VERSION ""

NS_ :

BS_:

BU_: PowertrainControlModule AtmosphericSensor SafetyRestraintSystem2 Aftertreatment_2_GasOutlet Aftertreatment_2_GasIntake DieselParticulateFilterControl Turbocharger SafetyRestraintSystem1 CabDisplay2 Aftertreatment_1_GasOutlet Aftertreatment_1_GasIntake OnBoardDataLogger OffBoardDiagnosticTool2 OffBoardDiagnosticTool1 FileServer ParkingBrakeController SeatController2 FanDriveController SteeringColumnUnit CommunicationUnitRadio CommunicationUnitSatellite CommunicationUnitCellular PropulsionBatteryCharger ChassisController2 ChassisController1 EngineValveControl AuxiliaryHeater2 AuxiliaryHeater1 ClutchUnit RampControl InformationSystem1 SuspensionSystemController2 OilSensor VehicleDynamicStability ExhaustEmissionController TransmissionDisplay2 TransmissionDisplay1 ClimateControl2 WaterPumpController RearAxleSteeringController LightingOperatorControl SeatController1 IgnitionController2 IgnitionController1 TirePressureController CabController2 CabController1 PneumaticSystemController SuspensionSystemController1 HydraulicPumpController EnduranceBrakingSystem RetarderExhaustEngine2 OnBoardDiagnosticUnit HeadwayController RetarderExhaustEngine1 CabDisplay1 ManagementComputer VirtualTerminal OffVehicleGateway PowerTakeOffFront HitchControl AuxiliaryValveControl BodyController TractorTrailerBridge1 StarterSystem ElectricalSystem VehicleSecurity VehicleNavigation AerodynamicControl ElectricalChargingSystem ClimateControl1 TripRecorder InstrumentCluster SuspensionDriveAxle2 SuspensionDriveAxle1 SuspensionSteerAxle SteeringController FuelSystem CruiseControl RetarderDriveline RetarderEngine BrakesDriveAxle2 BrakesDriveAxle1 BrakesSystemController BrakesSteerAxle AxleDrive2 AxleDrive1 AxleSteering PowerTakeOff ShiftConsoleSecondary ShiftConsolePrimary Transmission2 Transmission1 Engine2 Engine1

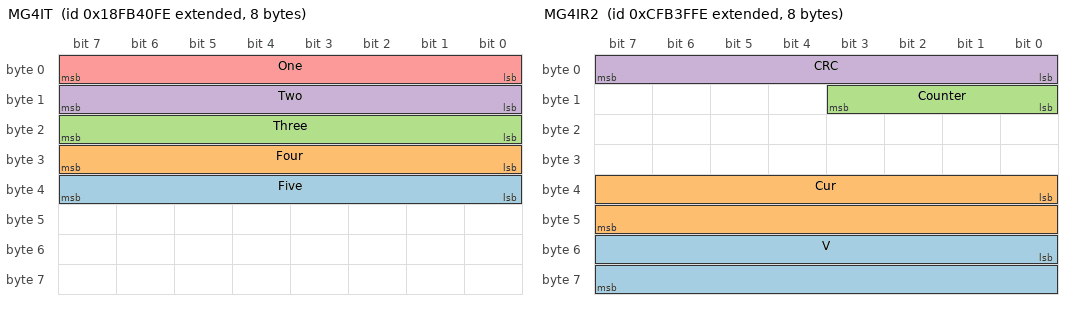
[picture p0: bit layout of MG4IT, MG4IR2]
BO_ 2566603006 MG4IT: 8 Vector__XXX
 SG_ Five : 32|8@1+ (1,-40) [-40|210] "°C" Vector__XXX
 SG_ Four : 24|8@1+ (1,-40) [-40|210] "°C" Vector__XXX
 SG_ Three : 16|8@1+ (1,-40) [-40|210] "°C" Vector__XXX
 SG_ Two : 8|8@1+ (1,-40) [-40|210] "°C" Vector__XXX
 SG_ One : 0|8@1+ (1,-40) [-40|210] "°C" Vector__XXX

BO_ 2365276158 MG4IR2: 8 Vector__XXX
 SG_ V : 48|16@1+ (0.125,0) [0|8031.875] "V" Vector__XXX
 SG_ Cur : 32|16@1+ (0.125,0) [0|8031.875] "A" Vector__XXX
 SG_ Counter : 8|4@1+ (1,0) [0|15] "" Vector__XXX
 SG_ CRC : 0|8@1+ (1,0) [0|255] "" Vector__XXX

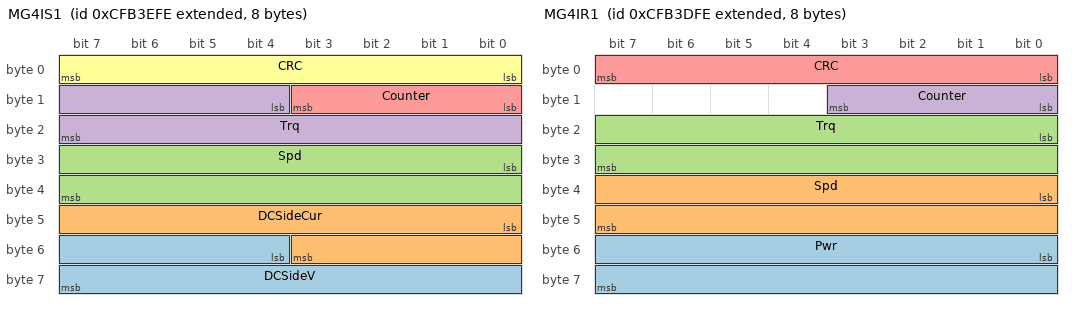
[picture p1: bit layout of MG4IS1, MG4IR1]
BO_ 2365275902 MG4IS1: 8 Vector__XXX
 SG_ DCSideV : 52|12@1+ (0.0625,-125) [-125|125.9375] "%" Vector__XXX
 SG_ DCSideCur : 40|12@1+ (0.0625,-125) [-125|125.9375] "%" Vector__XXX
 SG_ Spd : 24|16@1+ (0.00390625,-125) [-125|125.99609375] "%" Vector__XXX
 SG_ Trq : 12|12@1+ (0.0625,-125) [-125|125.9375] "%" Vector__XXX
 SG_ Counter : 8|4@1+ (1,0) [0|15] "" Vector__XXX
 SG_ CRC : 0|8@1+ (1,0) [0|255] "" Vector__XXX

BO_ 2365275646 MG4IR1: 8 Vector__XXX
 SG_ Pwr : 48|16@1+ (0.0625,0) [0|4015.9375] "kW" Vector__XXX
 SG_ Spd : 32|16@1+ (4,0) [0|257020] "rpm" Vector__XXX
 SG_ Trq : 16|16@1+ (0.5,0) [0|32127.5] "Nm" Vector__XXX
 SG_ Counter : 8|4@1+ (1,0) [0|15] "" Vector__XXX
 SG_ CRC : 0|8@1+ (1,0) [0|255] "" Vector__XXX

BO_ 2566601982 MG5IAPL: 8 Vector__XXX
 SG_ TrqLimDueToMachineCharacter_0003 : 38|2@1+ (1,0) [0|3] "" Vector__XXX
 SG_ PLedDueToActiveSpdRateLmt : 36|2@1+ (1,0) [0|3] "" Vector__XXX
 SG_ PLedDueToActiveTrqRateLmt : 34|2@1+ (1,0) [0|3] "" Vector__XXX
 SG_ PLedDueToFaultCondition : 32|2@1+ (1,0) [0|3] "" Vector__XXX
 SG_ PLedDueToMotorTemp : 30|2@1+ (1,0) [0|3] "" Vector__XXX
 SG_ PLedDueToInvTemp : 28|2@1+ (1,0) [0|3] "" Vector__XXX
 SG_ PLedDueToSpdMin : 24|2@1+ (1,0) [0|3] "" Vector__XXX
 SG_ PLedDueToSpdMax : 22|2@1+ (1,0) [0|3] "" Vector__XXX
 SG_ PLedDueToTrqMin : 20|2@1+ (1,0) [0|3] "" Vector__XXX
 SG_ PLedDueToTrqMax : 18|2@1+ (1,0) [0|3] "" Vector__XXX
 SG_ PLedDueToDCSidePwrMin : 16|2@1+ (1,0) [0|3] "" Vector__XXX
 SG_ PLedDueToDCSidePwrMax : 14|2@1+ (1,0) [0|3] "" Vector__XXX
 SG_ PLedDueToMechPwrMin : 12|2@1+ (1,0) [0|3] "" Vector__XXX
 SG_ PLedDueToMechPwrMax : 10|2@1+ (1,0) [0|3] "" Vector__XXX
 SG_ PLedDueToDCSideVMin : 8|2@1+ (1,0) [0|3] "" Vector__XXX
 SG_ PLedDueToDCSideVMax : 6|2@1+ (1,0) [0|3] "" Vector__XXX
 SG_ PLedDueToDCSideCurMin : 4|2@1+ (1,0) [0|3] "" Vector__XXX
 SG_ PLedDueToDCSideCurMax : 2|2@1+ (1,0) [0|3] "" Vector__XXX
 SG_ PLedDueToUndefinedReason : 0|2@1+ (1,0) [0|3] "" Vector__XXX

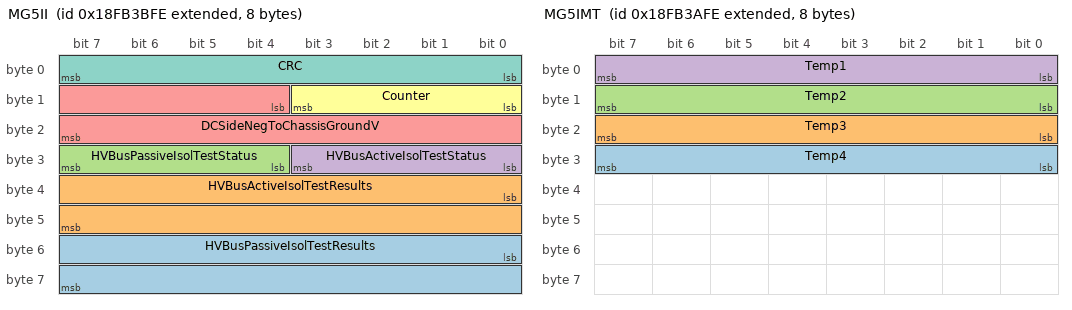
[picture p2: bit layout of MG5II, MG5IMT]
BO_ 2566601726 MG5II: 8 Vector__XXX
 SG_ HVBusPassiveIsolTestResults : 48|16@1+ (0.1,0) [0|6425.5] "Ohm/V" Vector__XXX
 SG_ HVBusActiveIsolTestResults : 32|16@1+ (0.1,0) [0|6425.5] "Ohm/V" Vector__XXX
 SG_ HVBusPassiveIsolTestStatus : 28|4@1+ (1,0) [0|15] "" Vector__XXX
 SG_ HVBusActiveIsolTestStatus : 24|4@1+ (1,0) [0|15] "" Vector__XXX
 SG_ DCSideNegToChassisGroundV : 12|12@1+ (0.0625,-125) [-125|125.9375] "%" Vector__XXX
 SG_ Counter : 8|4@1+ (1,0) [0|15] "" Vector__XXX
 SG_ CRC : 0|8@1+ (1,0) [0|255] "" Vector__XXX

BO_ 2566601470 MG5IMT: 8 Vector__XXX
 SG_ Temp4 : 24|8@1+ (1,-40) [-40|210] "°C" Vector__XXX
 SG_ Temp3 : 16|8@1+ (1,-40) [-40|210] "°C" Vector__XXX
 SG_ Temp2 : 8|8@1+ (1,-40) [-40|210] "°C" Vector__XXX
 SG_ Temp1 : 0|8@1+ (1,-40) [-40|210] "°C" Vector__XXX

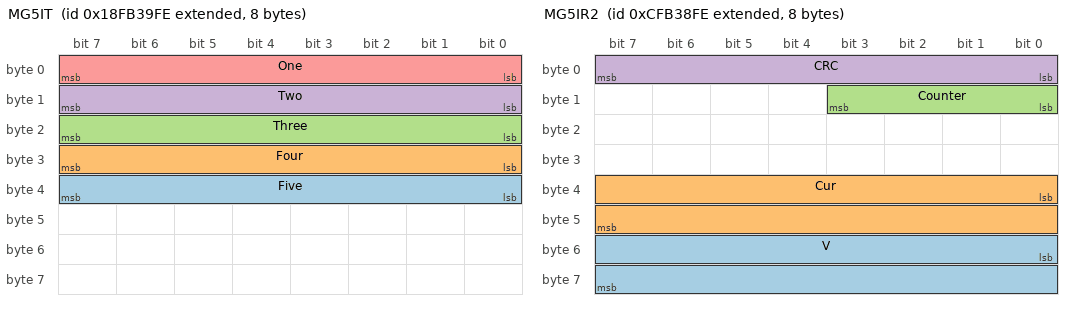
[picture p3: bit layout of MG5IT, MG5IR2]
BO_ 2566601214 MG5IT: 8 Vector__XXX
 SG_ Five : 32|8@1+ (1,-40) [-40|210] "°C" Vector__XXX
 SG_ Four : 24|8@1+ (1,-40) [-40|210] "°C" Vector__XXX
 SG_ Three : 16|8@1+ (1,-40) [-40|210] "°C" Vector__XXX
 SG_ Two : 8|8@1+ (1,-40) [-40|210] "°C" Vector__XXX
 SG_ One : 0|8@1+ (1,-40) [-40|210] "°C" Vector__XXX

BO_ 2365274366 MG5IR2: 8 Vector__XXX
 SG_ V : 48|16@1+ (0.125,0) [0|8031.875] "V" Vector__XXX
 SG_ Cur : 32|16@1+ (0.125,0) [0|8031.875] "A" Vector__XXX
 SG_ Counter : 8|4@1+ (1,0) [0|15] "" Vector__XXX
 SG_ CRC : 0|8@1+ (1,0) [0|255] "" Vector__XXX

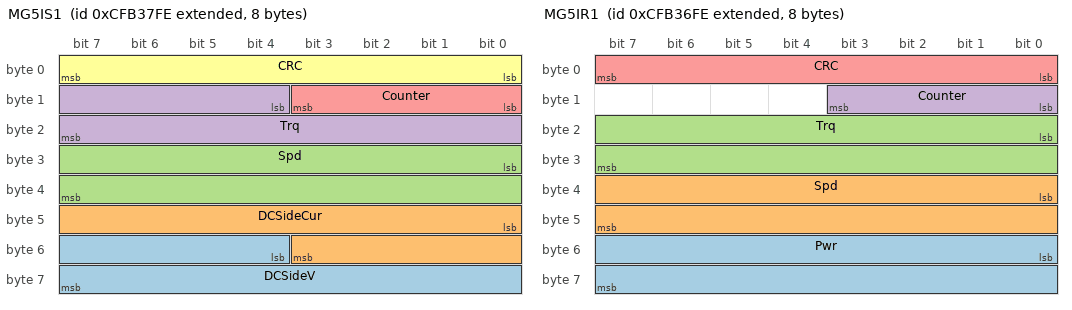
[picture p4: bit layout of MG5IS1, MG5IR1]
BO_ 2365274110 MG5IS1: 8 Vector__XXX
 SG_ DCSideV : 52|12@1+ (0.0625,-125) [-125|125.9375] "%" Vector__XXX
 SG_ DCSideCur : 40|12@1+ (0.0625,-125) [-125|125.9375] "%" Vector__XXX
 SG_ Spd : 24|16@1+ (0.00390625,-125) [-125|125.99609375] "%" Vector__XXX
 SG_ Trq : 12|12@1+ (0.0625,-125) [-125|125.9375] "%" Vector__XXX
 SG_ Counter : 8|4@1+ (1,0) [0|15] "" Vector__XXX
 SG_ CRC : 0|8@1+ (1,0) [0|255] "" Vector__XXX

BO_ 2365273854 MG5IR1: 8 Vector__XXX
 SG_ Pwr : 48|16@1+ (0.0625,0) [0|4015.9375] "kW" Vector__XXX
 SG_ Spd : 32|16@1+ (4,0) [0|257020] "rpm" Vector__XXX
 SG_ Trq : 16|16@1+ (0.5,0) [0|32127.5] "Nm" Vector__XXX
 SG_ Counter : 8|4@1+ (1,0) [0|15] "" Vector__XXX
 SG_ CRC : 0|8@1+ (1,0) [0|255] "" Vector__XXX

BO_ 2566600190 MG6IAPL: 8 Vector__XXX
 SG_ TrqLimDueToMachineCharacter_0004 : 38|2@1+ (1,0) [0|3] "" Vector__XXX
 SG_ PLedDueToActiveSpdRateLmt : 36|2@1+ (1,0) [0|3] "" Vector__XXX
 SG_ PLedDueToActiveTrqRateLmt : 34|2@1+ (1,0) [0|3] "" Vector__XXX
 SG_ PLedDueToFaultCondition : 32|2@1+ (1,0) [0|3] "" Vector__XXX
 SG_ PLedDueToMotorTemp : 30|2@1+ (1,0) [0|3] "" Vector__XXX
 SG_ PLedDueToInvTemp : 28|2@1+ (1,0) [0|3] "" Vector__XXX
 SG_ PLedDueToSpdMin : 24|2@1+ (1,0) [0|3] "" Vector__XXX
 SG_ PLedDueToSpdMax : 22|2@1+ (1,0) [0|3] "" Vector__XXX
 SG_ PLedDueToTrqMin : 20|2@1+ (1,0) [0|3] "" Vector__XXX
 SG_ PLedDueToTrqMax : 18|2@1+ (1,0) [0|3] "" Vector__XXX
 SG_ PLedDueToDCSidePwrMin : 16|2@1+ (1,0) [0|3] "" Vector__XXX
 SG_ PLedDueToDCSidePwrMax : 14|2@1+ (1,0) [0|3] "" Vector__XXX
 SG_ PLedDueToMechPwrMin : 12|2@1+ (1,0) [0|3] "" Vector__XXX
 SG_ PLedDueToMechPwrMax : 10|2@1+ (1,0) [0|3] "" Vector__XXX
 SG_ PLedDueToDCSideVMin : 8|2@1+ (1,0) [0|3] "" Vector__XXX
 SG_ PLedDueToDCSideVMax : 6|2@1+ (1,0) [0|3] "" Vector__XXX
 SG_ PLedDueToDCSideCurMin : 4|2@1+ (1,0) [0|3] "" Vector__XXX
 SG_ PLedDueToDCSideCurMax : 2|2@1+ (1,0) [0|3] "" Vector__XXX
 SG_ PLedDueToUndefinedReason : 0|2@1+ (1,0) [0|3] "" Vector__XXX

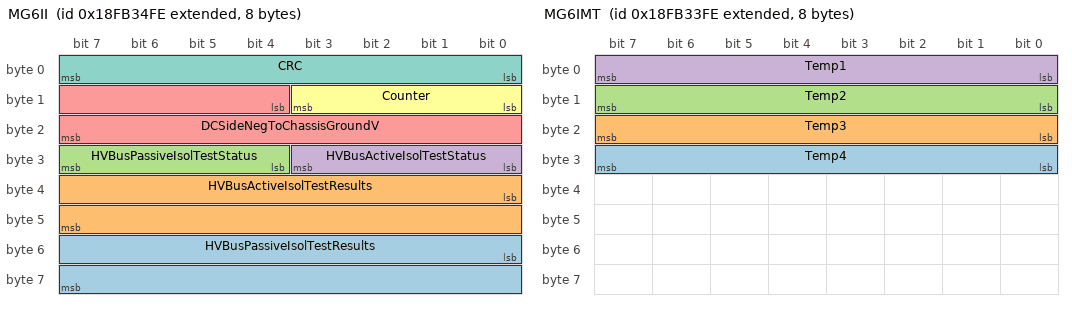
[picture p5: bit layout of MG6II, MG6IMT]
BO_ 2566599934 MG6II: 8 Vector__XXX
 SG_ HVBusPassiveIsolTestResults : 48|16@1+ (0.1,0) [0|6425.5] "Ohm/V" Vector__XXX
 SG_ HVBusActiveIsolTestResults : 32|16@1+ (0.1,0) [0|6425.5] "Ohm/V" Vector__XXX
 SG_ HVBusPassiveIsolTestStatus : 28|4@1+ (1,0) [0|15] "" Vector__XXX
 SG_ HVBusActiveIsolTestStatus : 24|4@1+ (1,0) [0|15] "" Vector__XXX
 SG_ DCSideNegToChassisGroundV : 12|12@1+ (0.0625,-125) [-125|125.9375] "%" Vector__XXX
 SG_ Counter : 8|4@1+ (1,0) [0|15] "" Vector__XXX
 SG_ CRC : 0|8@1+ (1,0) [0|255] "" Vector__XXX

BO_ 2566599678 MG6IMT: 8 Vector__XXX
 SG_ Temp4 : 24|8@1+ (1,-40) [-40|210] "°C" Vector__XXX
 SG_ Temp3 : 16|8@1+ (1,-40) [-40|210] "°C" Vector__XXX
 SG_ Temp2 : 8|8@1+ (1,-40) [-40|210] "°C" Vector__XXX
 SG_ Temp1 : 0|8@1+ (1,-40) [-40|210] "°C" Vector__XXX

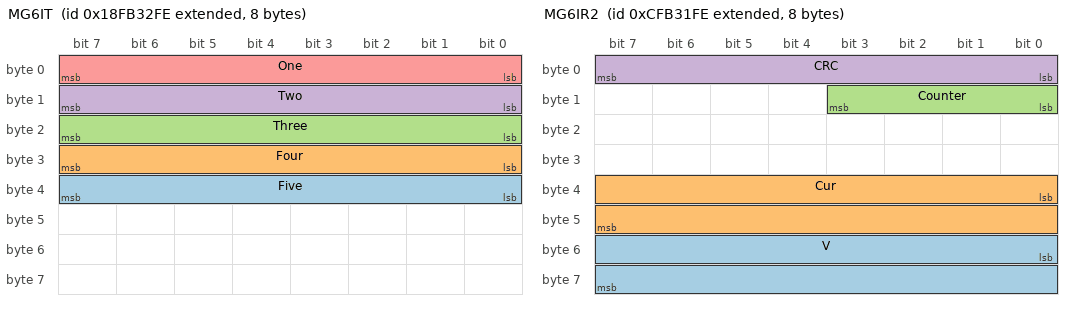
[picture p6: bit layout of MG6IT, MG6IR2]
BO_ 2566599422 MG6IT: 8 Vector__XXX
 SG_ Five : 32|8@1+ (1,-40) [-40|210] "°C" Vector__XXX
 SG_ Four : 24|8@1+ (1,-40) [-40|210] "°C" Vector__XXX
 SG_ Three : 16|8@1+ (1,-40) [-40|210] "°C" Vector__XXX
 SG_ Two : 8|8@1+ (1,-40) [-40|210] "°C" Vector__XXX
 SG_ One : 0|8@1+ (1,-40) [-40|210] "°C" Vector__XXX

BO_ 2365272574 MG6IR2: 8 Vector__XXX
 SG_ V : 48|16@1+ (0.125,0) [0|8031.875] "V" Vector__XXX
 SG_ Cur : 32|16@1+ (0.125,0) [0|8031.875] "A" Vector__XXX
 SG_ Counter : 8|4@1+ (1,0) [0|15] "" Vector__XXX
 SG_ CRC : 0|8@1+ (1,0) [0|255] "" Vector__XXX

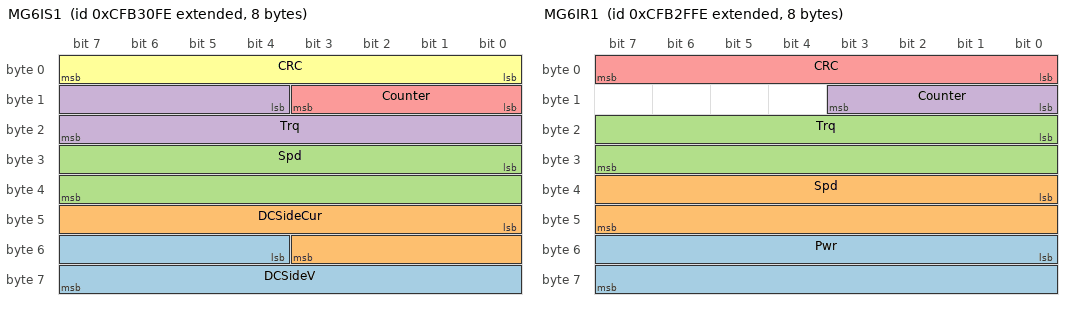
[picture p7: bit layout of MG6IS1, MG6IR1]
BO_ 2365272318 MG6IS1: 8 Vector__XXX
 SG_ DCSideV : 52|12@1+ (0.0625,-125) [-125|125.9375] "%" Vector__XXX
 SG_ DCSideCur : 40|12@1+ (0.0625,-125) [-125|125.9375] "%" Vector__XXX
 SG_ Spd : 24|16@1+ (0.00390625,-125) [-125|125.99609375] "%" Vector__XXX
 SG_ Trq : 12|12@1+ (0.0625,-125) [-125|125.9375] "%" Vector__XXX
 SG_ Counter : 8|4@1+ (1,0) [0|15] "" Vector__XXX
 SG_ CRC : 0|8@1+ (1,0) [0|255] "" Vector__XXX

BO_ 2365272062 MG6IR1: 8 Vector__XXX
 SG_ Pwr : 48|16@1+ (0.0625,0) [0|4015.9375] "kW" Vector__XXX
 SG_ Spd : 32|16@1+ (4,0) [0|257020] "rpm" Vector__XXX
 SG_ Trq : 16|16@1+ (0.5,0) [0|32127.5] "Nm" Vector__XXX
 SG_ Counter : 8|4@1+ (1,0) [0|15] "" Vector__XXX
 SG_ CRC : 0|8@1+ (1,0) [0|255] "" Vector__XXX

BO_ 2566598398 WINCH2: 8 Vector__XXX
 SG_ RevolutionCounter : 0|32@1+ (1,0) [0|4211081215] "" Vector__XXX

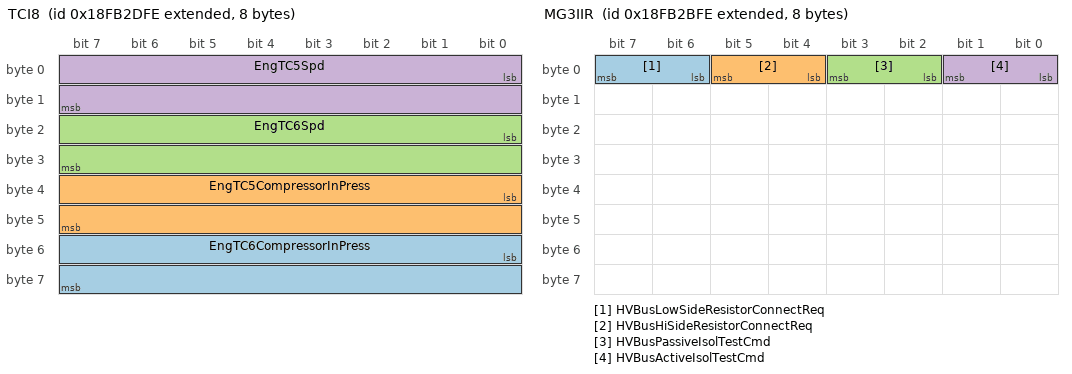
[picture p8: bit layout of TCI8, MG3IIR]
BO_ 2566598142 TCI8: 8 Vector__XXX
 SG_ EngTC6CompressorInPress : 48|16@1+ (0.0078125,-250) [-250|251.9921875] "kPa" Vector__XXX
 SG_ EngTC5CompressorInPress : 32|16@1+ (0.0078125,-250) [-250|251.9921875] "kPa" Vector__XXX
 SG_ EngTC6Spd : 16|16@1+ (4,0) [0|257020] "rpm" Vector__XXX
 SG_ EngTC5Spd : 0|16@1+ (4,0) [0|257020] "rpm" Vector__XXX

BO_ 2566597630 MG3IIR: 8 Vector__XXX
 SG_ HVBusLowSideResistorConnectReq : 6|2@1+ (1,0) [0|3] "" Vector__XXX
 SG_ HVBusHiSideResistorConnectReq : 4|2@1+ (1,0) [0|3] "" Vector__XXX
 SG_ HVBusPassiveIsolTestCmd : 2|2@1+ (1,0) [0|3] "" Vector__XXX
 SG_ HVBusActiveIsolTestCmd : 0|2@1+ (1,0) [0|3] "" Vector__XXX

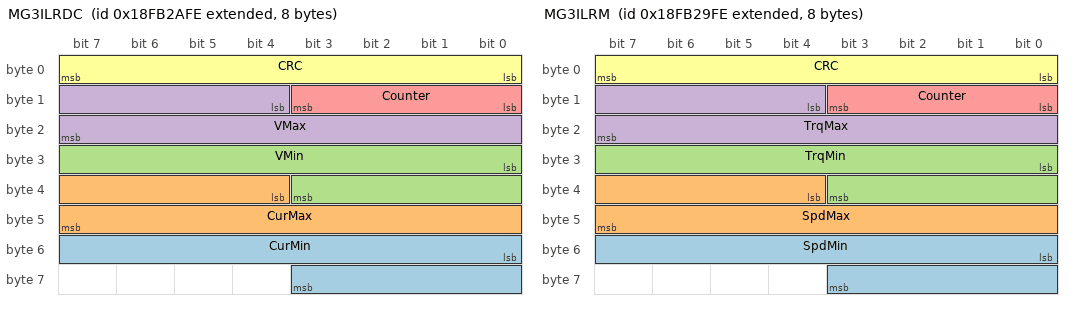
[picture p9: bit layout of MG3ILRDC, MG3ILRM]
BO_ 2566597374 MG3ILRDC: 8 Vector__XXX
 SG_ CurMin : 48|12@1+ (0.0625,-125) [-125|125.9375] "%" Vector__XXX
 SG_ CurMax : 36|12@1+ (0.0625,-125) [-125|125.9375] "%" Vector__XXX
 SG_ VMin : 24|12@1+ (0.0625,-125) [-125|125.9375] "%" Vector__XXX
 SG_ VMax : 12|12@1+ (0.0625,-125) [-125|125.9375] "%" Vector__XXX
 SG_ Counter : 8|4@1+ (1,0) [0|15] "" Vector__XXX
 SG_ CRC : 0|8@1+ (1,0) [0|255] "" Vector__XXX

BO_ 2566597118 MG3ILRM: 8 Vector__XXX
 SG_ SpdMin : 48|12@1+ (0.0625,-125) [-125|125.9375] "%" Vector__XXX
 SG_ SpdMax : 36|12@1+ (0.0625,-125) [-125|125.9375] "%" Vector__XXX
 SG_ TrqMin : 24|12@1+ (0.0625,-125) [-125|125.9375] "%" Vector__XXX
 SG_ TrqMax : 12|12@1+ (0.0625,-125) [-125|125.9375] "%" Vector__XXX
 SG_ Counter : 8|4@1+ (1,0) [0|15] "" Vector__XXX
 SG_ CRC : 0|8@1+ (1,0) [0|255] "" Vector__XXX

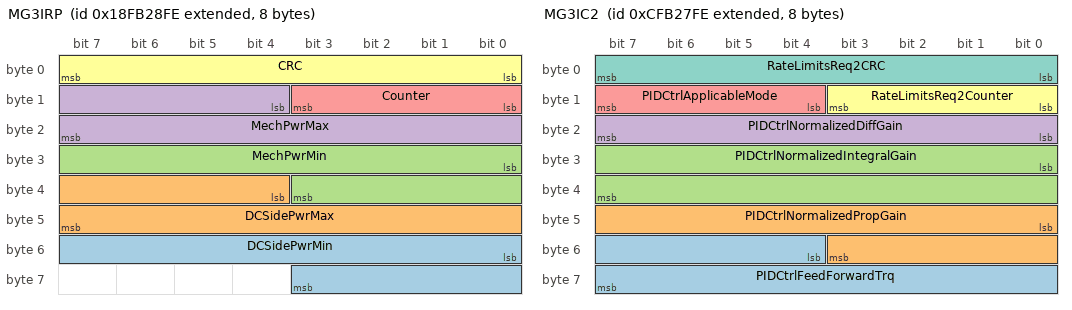
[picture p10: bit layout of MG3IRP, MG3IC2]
BO_ 2566596862 MG3IRP: 8 Vector__XXX
 SG_ DCSidePwrMin : 48|12@1+ (0.0625,-125) [-125|125.9375] "%" Vector__XXX
 SG_ DCSidePwrMax : 36|12@1+ (0.0625,-125) [-125|125.9375] "%" Vector__XXX
 SG_ MechPwrMin : 24|12@1+ (0.0625,-125) [-125|125.9375] "%" Vector__XXX
 SG_ MechPwrMax : 12|12@1+ (0.0625,-125) [-125|125.9375] "%" Vector__XXX
 SG_ Counter : 8|4@1+ (1,0) [0|15] "" Vector__XXX
 SG_ CRC : 0|8@1+ (1,0) [0|255] "" Vector__XXX

BO_ 2365270014 MG3IC2: 8 Vector__XXX
 SG_ PIDCtrlFeedForwardTrq : 52|12@1+ (0.0625,-125) [-125|125.9375] "%" Vector__XXX
 SG_ PIDCtrlNormalizedPropGain : 40|12@1+ (0.0625,0) [0|250.9375] "%/%" Vector__XXX
 SG_ PIDCtrlNormalizedIntegralGain : 24|16@1+ (0.015625,0) [0|1003.984375] "%/(%*s)" Vector__XXX
 SG_ PIDCtrlNormalizedDiffGain : 16|8@1+ (0.03125,0) [0|7.8125] "%/(%/s)" Vector__XXX
 SG_ PIDCtrlApplicableMode : 12|4@1+ (1,0) [0|15] "" Vector__XXX
 SG_ RateLimitsReq2Counter : 8|4@1+ (1,0) [0|15] "" Vector__XXX
 SG_ RateLimitsReq2CRC : 0|8@1+ (1,0) [0|255] "" Vector__XXX

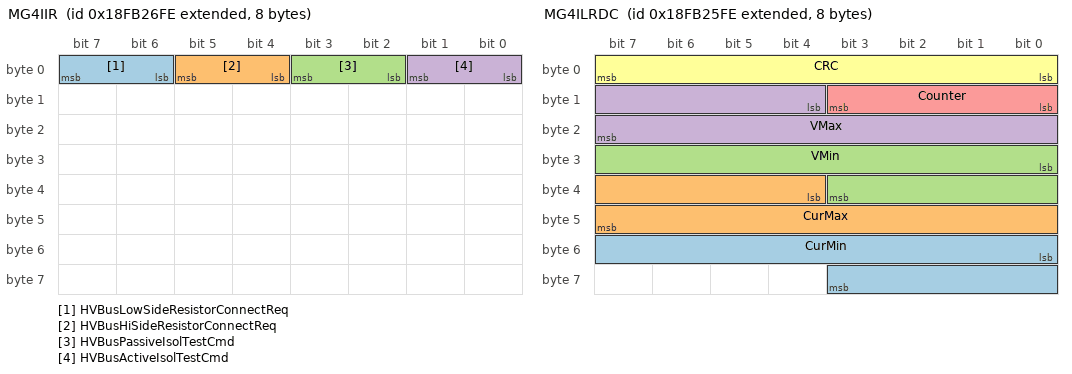
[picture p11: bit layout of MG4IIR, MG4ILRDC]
BO_ 2566596350 MG4IIR: 8 Vector__XXX
 SG_ HVBusLowSideResistorConnectReq : 6|2@1+ (1,0) [0|3] "" Vector__XXX
 SG_ HVBusHiSideResistorConnectReq : 4|2@1+ (1,0) [0|3] "" Vector__XXX
 SG_ HVBusPassiveIsolTestCmd : 2|2@1+ (1,0) [0|3] "" Vector__XXX
 SG_ HVBusActiveIsolTestCmd : 0|2@1+ (1,0) [0|3] "" Vector__XXX

BO_ 2566596094 MG4ILRDC: 8 Vector__XXX
 SG_ CurMin : 48|12@1+ (0.0625,-125) [-125|125.9375] "%" Vector__XXX
 SG_ CurMax : 36|12@1+ (0.0625,-125) [-125|125.9375] "%" Vector__XXX
 SG_ VMin : 24|12@1+ (0.0625,-125) [-125|125.9375] "%" Vector__XXX
 SG_ VMax : 12|12@1+ (0.0625,-125) [-125|125.9375] "%" Vector__XXX
 SG_ Counter : 8|4@1+ (1,0) [0|15] "" Vector__XXX
 SG_ CRC : 0|8@1+ (1,0) [0|255] "" Vector__XXX

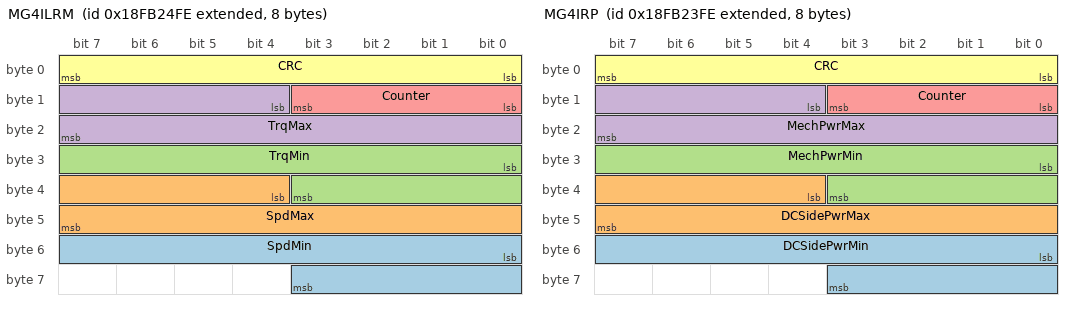
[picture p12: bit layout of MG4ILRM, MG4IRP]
BO_ 2566595838 MG4ILRM: 8 Vector__XXX
 SG_ SpdMin : 48|12@1+ (0.0625,-125) [-125|125.9375] "%" Vector__XXX
 SG_ SpdMax : 36|12@1+ (0.0625,-125) [-125|125.9375] "%" Vector__XXX
 SG_ TrqMin : 24|12@1+ (0.0625,-125) [-125|125.9375] "%" Vector__XXX
 SG_ TrqMax : 12|12@1+ (0.0625,-125) [-125|125.9375] "%" Vector__XXX
 SG_ Counter : 8|4@1+ (1,0) [0|15] "" Vector__XXX
 SG_ CRC : 0|8@1+ (1,0) [0|255] "" Vector__XXX

BO_ 2566595582 MG4IRP: 8 Vector__XXX
 SG_ DCSidePwrMin : 48|12@1+ (0.0625,-125) [-125|125.9375] "%" Vector__XXX
 SG_ DCSidePwrMax : 36|12@1+ (0.0625,-125) [-125|125.9375] "%" Vector__XXX
 SG_ MechPwrMin : 24|12@1+ (0.0625,-125) [-125|125.9375] "%" Vector__XXX
 SG_ MechPwrMax : 12|12@1+ (0.0625,-125) [-125|125.9375] "%" Vector__XXX
 SG_ Counter : 8|4@1+ (1,0) [0|15] "" Vector__XXX
 SG_ CRC : 0|8@1+ (1,0) [0|255] "" Vector__XXX

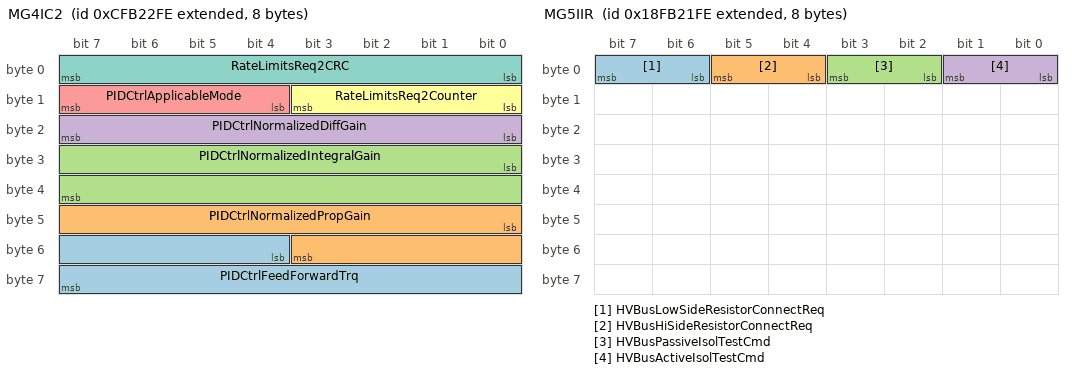
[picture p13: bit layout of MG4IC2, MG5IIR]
BO_ 2365268734 MG4IC2: 8 Vector__XXX
 SG_ PIDCtrlFeedForwardTrq : 52|12@1+ (0.0625,-125) [-125|125.9375] "%" Vector__XXX
 SG_ PIDCtrlNormalizedPropGain : 40|12@1+ (0.0625,0) [0|250.9375] "%/%" Vector__XXX
 SG_ PIDCtrlNormalizedIntegralGain : 24|16@1+ (0.015625,0) [0|1003.984375] "%/(%*s)" Vector__XXX
 SG_ PIDCtrlNormalizedDiffGain : 16|8@1+ (0.03125,0) [0|7.8125] "%/(%/s)" Vector__XXX
 SG_ PIDCtrlApplicableMode : 12|4@1+ (1,0) [0|15] "" Vector__XXX
 SG_ RateLimitsReq2Counter : 8|4@1+ (1,0) [0|15] "" Vector__XXX
 SG_ RateLimitsReq2CRC : 0|8@1+ (1,0) [0|255] "" Vector__XXX

BO_ 2566595070 MG5IIR: 8 Vector__XXX
 SG_ HVBusLowSideResistorConnectReq : 6|2@1+ (1,0) [0|3] "" Vector__XXX
 SG_ HVBusHiSideResistorConnectReq : 4|2@1+ (1,0) [0|3] "" Vector__XXX
 SG_ HVBusPassiveIsolTestCmd : 2|2@1+ (1,0) [0|3] "" Vector__XXX
 SG_ HVBusActiveIsolTestCmd : 0|2@1+ (1,0) [0|3] "" Vector__XXX

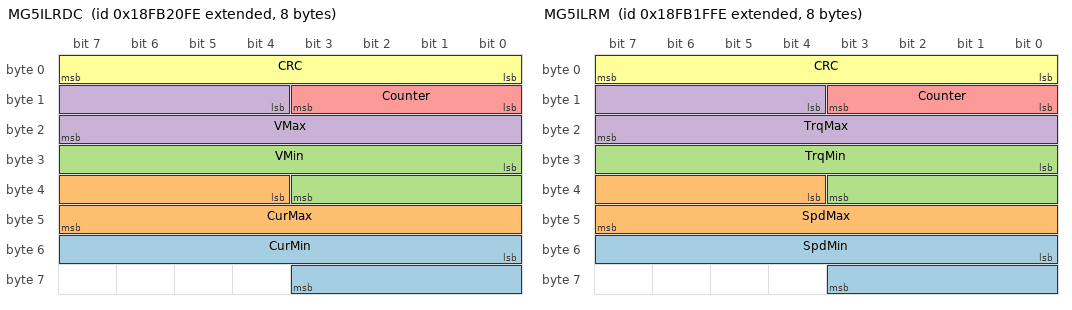
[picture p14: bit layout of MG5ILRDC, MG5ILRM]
BO_ 2566594814 MG5ILRDC: 8 Vector__XXX
 SG_ CurMin : 48|12@1+ (0.0625,-125) [-125|125.9375] "%" Vector__XXX
 SG_ CurMax : 36|12@1+ (0.0625,-125) [-125|125.9375] "%" Vector__XXX
 SG_ VMin : 24|12@1+ (0.0625,-125) [-125|125.9375] "%" Vector__XXX
 SG_ VMax : 12|12@1+ (0.0625,-125) [-125|125.9375] "%" Vector__XXX
 SG_ Counter : 8|4@1+ (1,0) [0|15] "" Vector__XXX
 SG_ CRC : 0|8@1+ (1,0) [0|255] "" Vector__XXX

BO_ 2566594558 MG5ILRM: 8 Vector__XXX
 SG_ SpdMin : 48|12@1+ (0.0625,-125) [-125|125.9375] "%" Vector__XXX
 SG_ SpdMax : 36|12@1+ (0.0625,-125) [-125|125.9375] "%" Vector__XXX
 SG_ TrqMin : 24|12@1+ (0.0625,-125) [-125|125.9375] "%" Vector__XXX
 SG_ TrqMax : 12|12@1+ (0.0625,-125) [-125|125.9375] "%" Vector__XXX
 SG_ Counter : 8|4@1+ (1,0) [0|15] "" Vector__XXX
 SG_ CRC : 0|8@1+ (1,0) [0|255] "" Vector__XXX

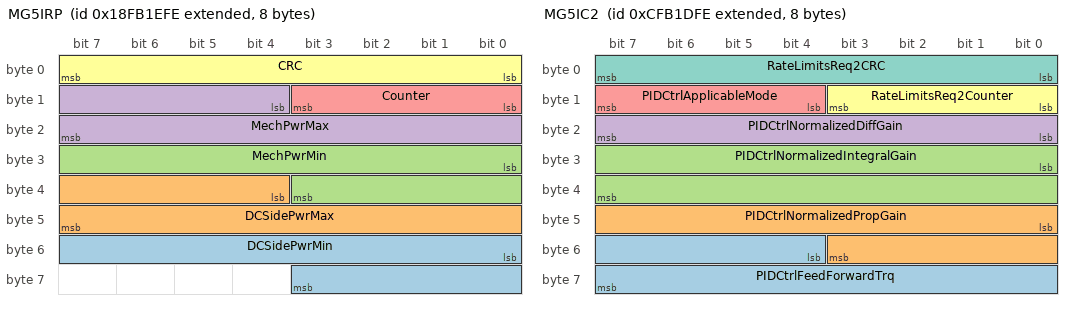
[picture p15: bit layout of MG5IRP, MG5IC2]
BO_ 2566594302 MG5IRP: 8 Vector__XXX
 SG_ DCSidePwrMin : 48|12@1+ (0.0625,-125) [-125|125.9375] "%" Vector__XXX
 SG_ DCSidePwrMax : 36|12@1+ (0.0625,-125) [-125|125.9375] "%" Vector__XXX
 SG_ MechPwrMin : 24|12@1+ (0.0625,-125) [-125|125.9375] "%" Vector__XXX
 SG_ MechPwrMax : 12|12@1+ (0.0625,-125) [-125|125.9375] "%" Vector__XXX
 SG_ Counter : 8|4@1+ (1,0) [0|15] "" Vector__XXX
 SG_ CRC : 0|8@1+ (1,0) [0|255] "" Vector__XXX

BO_ 2365267454 MG5IC2: 8 Vector__XXX
 SG_ PIDCtrlFeedForwardTrq : 52|12@1+ (0.0625,-125) [-125|125.9375] "%" Vector__XXX
 SG_ PIDCtrlNormalizedPropGain : 40|12@1+ (0.0625,0) [0|250.9375] "%/%" Vector__XXX
 SG_ PIDCtrlNormalizedIntegralGain : 24|16@1+ (0.015625,0) [0|1003.984375] "%/(%*s)" Vector__XXX
 SG_ PIDCtrlNormalizedDiffGain : 16|8@1+ (0.03125,0) [0|7.8125] "%/(%/s)" Vector__XXX
 SG_ PIDCtrlApplicableMode : 12|4@1+ (1,0) [0|15] "" Vector__XXX
 SG_ RateLimitsReq2Counter : 8|4@1+ (1,0) [0|15] "" Vector__XXX
 SG_ RateLimitsReq2CRC : 0|8@1+ (1,0) [0|255] "" Vector__XXX

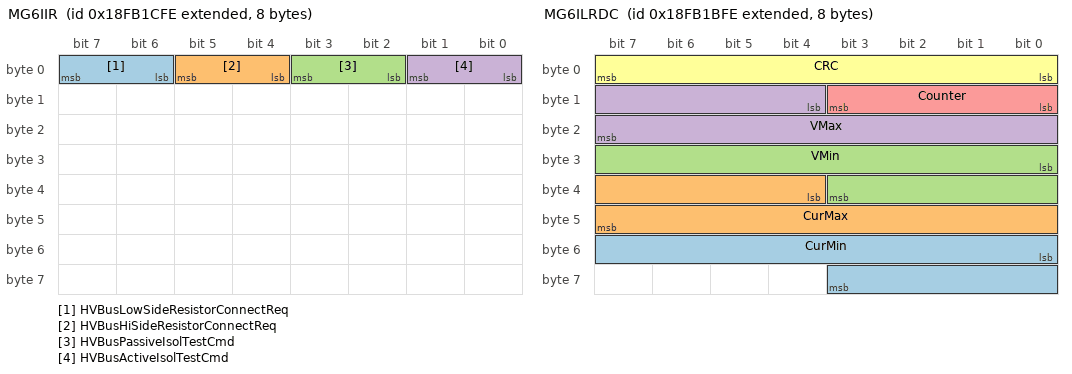
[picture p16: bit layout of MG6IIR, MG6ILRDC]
BO_ 2566593790 MG6IIR: 8 Vector__XXX
 SG_ HVBusLowSideResistorConnectReq : 6|2@1+ (1,0) [0|3] "" Vector__XXX
 SG_ HVBusHiSideResistorConnectReq : 4|2@1+ (1,0) [0|3] "" Vector__XXX
 SG_ HVBusPassiveIsolTestCmd : 2|2@1+ (1,0) [0|3] "" Vector__XXX
 SG_ HVBusActiveIsolTestCmd : 0|2@1+ (1,0) [0|3] "" Vector__XXX

BO_ 2566593534 MG6ILRDC: 8 Vector__XXX
 SG_ CurMin : 48|12@1+ (0.0625,-125) [-125|125.9375] "%" Vector__XXX
 SG_ CurMax : 36|12@1+ (0.0625,-125) [-125|125.9375] "%" Vector__XXX
 SG_ VMin : 24|12@1+ (0.0625,-125) [-125|125.9375] "%" Vector__XXX
 SG_ VMax : 12|12@1+ (0.0625,-125) [-125|125.9375] "%" Vector__XXX
 SG_ Counter : 8|4@1+ (1,0) [0|15] "" Vector__XXX
 SG_ CRC : 0|8@1+ (1,0) [0|255] "" Vector__XXX

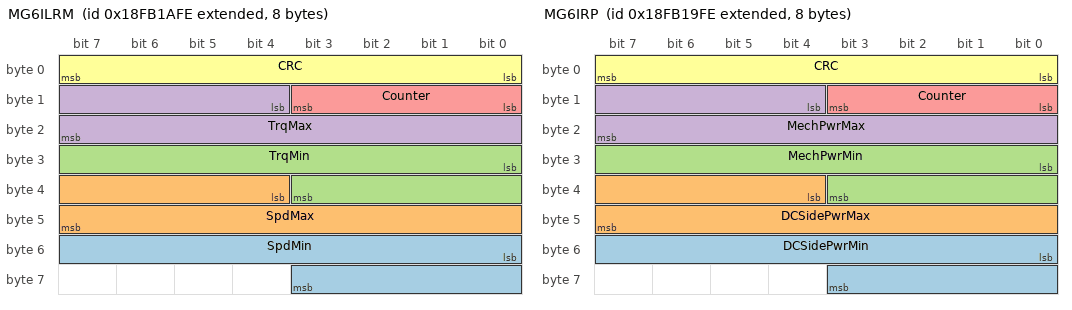
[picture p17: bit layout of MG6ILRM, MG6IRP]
BO_ 2566593278 MG6ILRM: 8 Vector__XXX
 SG_ SpdMin : 48|12@1+ (0.0625,-125) [-125|125.9375] "%" Vector__XXX
 SG_ SpdMax : 36|12@1+ (0.0625,-125) [-125|125.9375] "%" Vector__XXX
 SG_ TrqMin : 24|12@1+ (0.0625,-125) [-125|125.9375] "%" Vector__XXX
 SG_ TrqMax : 12|12@1+ (0.0625,-125) [-125|125.9375] "%" Vector__XXX
 SG_ Counter : 8|4@1+ (1,0) [0|15] "" Vector__XXX
 SG_ CRC : 0|8@1+ (1,0) [0|255] "" Vector__XXX

BO_ 2566593022 MG6IRP: 8 Vector__XXX
 SG_ DCSidePwrMin : 48|12@1+ (0.0625,-125) [-125|125.9375] "%" Vector__XXX
 SG_ DCSidePwrMax : 36|12@1+ (0.0625,-125) [-125|125.9375] "%" Vector__XXX
 SG_ MechPwrMin : 24|12@1+ (0.0625,-125) [-125|125.9375] "%" Vector__XXX
 SG_ MechPwrMax : 12|12@1+ (0.0625,-125) [-125|125.9375] "%" Vector__XXX
 SG_ Counter : 8|4@1+ (1,0) [0|15] "" Vector__XXX
 SG_ CRC : 0|8@1+ (1,0) [0|255] "" Vector__XXX

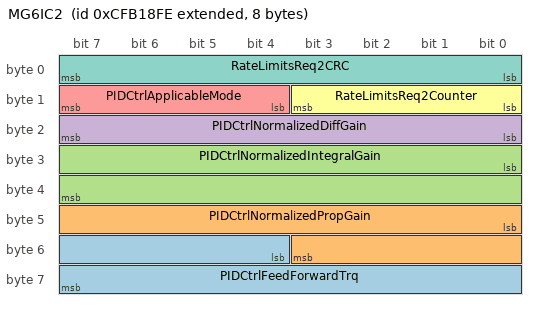
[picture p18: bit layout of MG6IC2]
BO_ 2365266174 MG6IC2: 8 Vector__XXX
 SG_ PIDCtrlFeedForwardTrq : 52|12@1+ (0.0625,-125) [-125|125.9375] "%" Vector__XXX
 SG_ PIDCtrlNormalizedPropGain : 40|12@1+ (0.0625,0) [0|250.9375] "%/%" Vector__XXX
 SG_ PIDCtrlNormalizedIntegralGain : 24|16@1+ (0.015625,0) [0|1003.984375] "%/(%*s)" Vector__XXX
 SG_ PIDCtrlNormalizedDiffGain : 16|8@1+ (0.03125,0) [0|7.8125] "%/(%/s)" Vector__XXX
 SG_ PIDCtrlApplicableMode : 12|4@1+ (1,0) [0|15] "" Vector__XXX
 SG_ RateLimitsReq2Counter : 8|4@1+ (1,0) [0|15] "" Vector__XXX
 SG_ RateLimitsReq2CRC : 0|8@1+ (1,0) [0|255] "" Vector__XXX

BO_ 2566592510 NTSNA: 68 Vector__XXX
 SG_ Bin17 : 512|32@1+ (0.0002,0) [0|842216.243] "g" Vector__XXX
 SG_ Bin16 : 480|32@1+ (0.0002,0) [0|842216.243] "g" Vector__XXX
 SG_ Bin15 : 448|32@1+ (0.0002,0) [0|842216.243] "g" Vector__XXX
 SG_ Bin14 : 416|32@1+ (0.0002,0) [0|842216.243] "g" Vector__XXX
 SG_ Bin13 : 384|32@1+ (0.0002,0) [0|842216.243] "g" Vector__XXX
 SG_ Bin12 : 352|32@1+ (0.0002,0) [0|842216.243] "g" Vector__XXX
 SG_ Bin11 : 320|32@1+ (0.0002,0) [0|842216.243] "g" Vector__XXX
 SG_ Bin10 : 288|32@1+ (0.0002,0) [0|842216.243] "g" Vector__XXX
 SG_ Bin9 : 256|32@1+ (0.0002,0) [0|842216.243] "g" Vector__XXX
 SG_ Bin8 : 224|32@1+ (0.0002,0) [0|842216.243] "g" Vector__XXX
 SG_ Bin7 : 192|32@1+ (0.0002,0) [0|842216.243] "g" Vector__XXX
 SG_ Bin6 : 160|32@1+ (0.0002,0) [0|842216.243] "g" Vector__XXX
 SG_ Bin5 : 128|32@1+ (0.0002,0) [0|842216.243] "g" Vector__XXX
 SG_ Bin4 : 96|32@1+ (0.0002,0) [0|842216.243] "g" Vector__XXX
 SG_ Bin3 : 64|32@1+ (0.0002,0) [0|842216.243] "g" Vector__XXX
 SG_ Bin2 : 32|32@1+ (0.0002,0) [0|842216.243] "g" Vector__XXX
 SG_ Bin1 : 0|32@1+ (0.0002,0) [0|842216.243] "g" Vector__XXX

BO_ 2566592254 NTENA: 68 Vector__XXX
 SG_ Bin17 : 512|32@1+ (0.0005,0) [0|2105540.6075] "g" Vector__XXX
 SG_ Bin16 : 480|32@1+ (0.0005,0) [0|2105540.6075] "g" Vector__XXX
 SG_ Bin15 : 448|32@1+ (0.0005,0) [0|2105540.6075] "g" Vector__XXX
 SG_ Bin14 : 416|32@1+ (0.0005,0) [0|2105540.6075] "g" Vector__XXX
 SG_ Bin13 : 384|32@1+ (0.0005,0) [0|2105540.6075] "g" Vector__XXX
 SG_ Bin12 : 352|32@1+ (0.0005,0) [0|2105540.6075] "g" Vector__XXX
 SG_ Bin11 : 320|32@1+ (0.0005,0) [0|2105540.6075] "g" Vector__XXX
 SG_ Bin10 : 288|32@1+ (0.0005,0) [0|2105540.6075] "g" Vector__XXX
 SG_ Bin9 : 256|32@1+ (0.0005,0) [0|2105540.6075] "g" Vector__XXX
 SG_ Bin8 : 224|32@1+ (0.0005,0) [0|2105540.6075] "g" Vector__XXX
 SG_ Bin7 : 192|32@1+ (0.0005,0) [0|2105540.6075] "g" Vector__XXX
 SG_ Bin6 : 160|32@1+ (0.0005,0) [0|2105540.6075] "g" Vector__XXX
 SG_ Bin5 : 128|32@1+ (0.0005,0) [0|2105540.6075] "g" Vector__XXX
 SG_ Bin4 : 96|32@1+ (0.0005,0) [0|2105540.6075] "g" Vector__XXX
 SG_ Bin3 : 64|32@1+ (0.0005,0) [0|2105540.6075] "g" Vector__XXX
 SG_ Bin2 : 32|32@1+ (0.0005,0) [0|2105540.6075] "g" Vector__XXX
 SG_ Bin1 : 0|32@1+ (0.0005,0) [0|2105540.6075] "g" Vector__XXX

BO_ 2566591998 NTEEA: 34 Vector__XXX
 SG_ Bin17 : 256|16@1+ (1,0) [0|64255] "kWh" Vector__XXX
 SG_ Bin16 : 240|16@1+ (1,0) [0|64255] "kWh" Vector__XXX
 SG_ Bin15 : 224|16@1+ (1,0) [0|64255] "kWh" Vector__XXX
 SG_ Bin14 : 208|16@1+ (1,0) [0|64255] "kWh" Vector__XXX
 SG_ Bin13 : 192|16@1+ (1,0) [0|64255] "kWh" Vector__XXX
 SG_ Bin12 : 176|16@1+ (1,0) [0|64255] "kWh" Vector__XXX
 SG_ Bin11 : 160|16@1+ (1,0) [0|64255] "kWh" Vector__XXX
 SG_ Bin10 : 144|16@1+ (1,0) [0|64255] "kWh" Vector__XXX
 SG_ Bin9 : 128|16@1+ (1,0) [0|64255] "kWh" Vector__XXX
 SG_ Bin8 : 112|16@1+ (1,0) [0|64255] "kWh" Vector__XXX
 SG_ Bin7 : 96|16@1+ (1,0) [0|64255] "kWh" Vector__XXX
 SG_ Bin6 : 80|16@1+ (1,0) [0|64255] "kWh" Vector__XXX
 SG_ Bin5 : 64|16@1+ (1,0) [0|64255] "kWh" Vector__XXX
 SG_ Bin4 : 48|16@1+ (1,0) [0|64255] "kWh" Vector__XXX
 SG_ Bin3 : 32|16@1+ (1,0) [0|64255] "kWh" Vector__XXX
 SG_ Bin2 : 16|16@1+ (1,0) [0|64255] "kWh" Vector__XXX
 SG_ Bin1 : 0|16@1+ (1,0) [0|64255] "kWh" Vector__XXX

BO_ 2566591742 NTVMA: 34 Vector__XXX
 SG_ Bin17 : 256|16@1+ (0.25,0) [0|16063.75] "km" Vector__XXX
 SG_ Bin16 : 240|16@1+ (0.25,0) [0|16063.75] "km" Vector__XXX
 SG_ Bin15 : 224|16@1+ (0.25,0) [0|16063.75] "km" Vector__XXX
 SG_ Bin14 : 208|16@1+ (0.25,0) [0|16063.75] "km" Vector__XXX
 SG_ Bin13 : 192|16@1+ (0.25,0) [0|16063.75] "km" Vector__XXX
 SG_ Bin12 : 176|16@1+ (0.25,0) [0|16063.75] "km" Vector__XXX
 SG_ Bin11 : 160|16@1+ (0.25,0) [0|16063.75] "km" Vector__XXX
 SG_ Bin10 : 144|16@1+ (0.25,0) [0|16063.75] "km" Vector__XXX
 SG_ Bin9 : 128|16@1+ (0.25,0) [0|16063.75] "km" Vector__XXX
 SG_ Bin8 : 112|16@1+ (0.25,0) [0|16063.75] "km" Vector__XXX
 SG_ Bin7 : 96|16@1+ (0.25,0) [0|16063.75] "km" Vector__XXX
 SG_ Bin6 : 80|16@1+ (0.25,0) [0|16063.75] "km" Vector__XXX
 SG_ Bin5 : 64|16@1+ (0.25,0) [0|16063.75] "km" Vector__XXX
 SG_ Bin4 : 48|16@1+ (0.25,0) [0|16063.75] "km" Vector__XXX
 SG_ Bin3 : 32|16@1+ (0.25,0) [0|16063.75] "km" Vector__XXX
 SG_ Bin2 : 16|16@1+ (0.25,0) [0|16063.75] "km" Vector__XXX
 SG_ Bin1 : 0|16@1+ (0.25,0) [0|16063.75] "km" Vector__XXX

BO_ 2566591486 NTEHA: 34 Vector__XXX
 SG_ Bin17 : 256|16@1+ (10,0) [0|642550] "s" Vector__XXX
 SG_ Bin16 : 240|16@1+ (10,0) [0|642550] "s" Vector__XXX
 SG_ Bin15 : 224|16@1+ (10,0) [0|642550] "s" Vector__XXX
 SG_ Bin14 : 208|16@1+ (10,0) [0|642550] "s" Vector__XXX
 SG_ Bin13 : 192|16@1+ (10,0) [0|642550] "s" Vector__XXX
 SG_ Bin12 : 176|16@1+ (10,0) [0|642550] "s" Vector__XXX
 SG_ Bin11 : 160|16@1+ (10,0) [0|642550] "s" Vector__XXX
 SG_ Bin10 : 144|16@1+ (10,0) [0|642550] "s" Vector__XXX
 SG_ Bin9 : 128|16@1+ (10,0) [0|642550] "s" Vector__XXX
 SG_ Bin8 : 112|16@1+ (10,0) [0|642550] "s" Vector__XXX
 SG_ Bin7 : 96|16@1+ (10,0) [0|642550] "s" Vector__XXX
 SG_ Bin6 : 80|16@1+ (10,0) [0|642550] "s" Vector__XXX
 SG_ Bin5 : 64|16@1+ (10,0) [0|642550] "s" Vector__XXX
 SG_ Bin4 : 48|16@1+ (10,0) [0|642550] "s" Vector__XXX
 SG_ Bin3 : 32|16@1+ (10,0) [0|642550] "s" Vector__XXX
 SG_ Bin2 : 16|16@1+ (10,0) [0|642550] "s" Vector__XXX
 SG_ Bin1 : 0|16@1+ (10,0) [0|642550] "s" Vector__XXX

BO_ 2566591230 NTFCA: 34 Vector__XXX
 SG_ Bin17 : 256|16@1+ (0.5,0) [0|32127.5] "l" Vector__XXX
 SG_ Bin16 : 240|16@1+ (0.5,0) [0|32127.5] "l" Vector__XXX
 SG_ Bin15 : 224|16@1+ (0.5,0) [0|32127.5] "l" Vector__XXX
 SG_ Bin14 : 208|16@1+ (0.5,0) [0|32127.5] "l" Vector__XXX
 SG_ Bin13 : 192|16@1+ (0.5,0) [0|32127.5] "l" Vector__XXX
 SG_ Bin12 : 176|16@1+ (0.5,0) [0|32127.5] "l" Vector__XXX
 SG_ Bin11 : 160|16@1+ (0.5,0) [0|32127.5] "l" Vector__XXX
 SG_ Bin10 : 144|16@1+ (0.5,0) [0|32127.5] "l" Vector__XXX
 SG_ Bin9 : 128|16@1+ (0.5,0) [0|32127.5] "l" Vector__XXX
 SG_ Bin8 : 112|16@1+ (0.5,0) [0|32127.5] "l" Vector__XXX
 SG_ Bin7 : 96|16@1+ (0.5,0) [0|32127.5] "l" Vector__XXX
 SG_ Bin6 : 80|16@1+ (0.5,0) [0|32127.5] "l" Vector__XXX
 SG_ Bin5 : 64|16@1+ (0.5,0) [0|32127.5] "l" Vector__XXX
 SG_ Bin4 : 48|16@1+ (0.5,0) [0|32127.5] "l" Vector__XXX
 SG_ Bin3 : 32|16@1+ (0.5,0) [0|32127.5] "l" Vector__XXX
 SG_ Bin2 : 16|16@1+ (0.5,0) [0|32127.5] "l" Vector__XXX
 SG_ Bin1 : 0|16@1+ (0.5,0) [0|32127.5] "l" Vector__XXX

BO_ 2566590974 NTSNS: 68 Vector__XXX
 SG_ Bin17 : 512|32@1+ (0.0002,0) [0|842216.243] "g" Vector__XXX
 SG_ Bin16 : 480|32@1+ (0.0002,0) [0|842216.243] "g" Vector__XXX
 SG_ Bin15 : 448|32@1+ (0.0002,0) [0|842216.243] "g" Vector__XXX
 SG_ Bin14 : 416|32@1+ (0.0002,0) [0|842216.243] "g" Vector__XXX
 SG_ Bin13 : 384|32@1+ (0.0002,0) [0|842216.243] "g" Vector__XXX
 SG_ Bin12 : 352|32@1+ (0.0002,0) [0|842216.243] "g" Vector__XXX
 SG_ Bin11 : 320|32@1+ (0.0002,0) [0|842216.243] "g" Vector__XXX
 SG_ Bin10 : 288|32@1+ (0.0002,0) [0|842216.243] "g" Vector__XXX
 SG_ Bin9 : 256|32@1+ (0.0002,0) [0|842216.243] "g" Vector__XXX
 SG_ Bin8 : 224|32@1+ (0.0002,0) [0|842216.243] "g" Vector__XXX
 SG_ Bin7 : 192|32@1+ (0.0002,0) [0|842216.243] "g" Vector__XXX
 SG_ Bin6 : 160|32@1+ (0.0002,0) [0|842216.243] "g" Vector__XXX
 SG_ Bin5 : 128|32@1+ (0.0002,0) [0|842216.243] "g" Vector__XXX
 SG_ Bin4 : 96|32@1+ (0.0002,0) [0|842216.243] "g" Vector__XXX
 SG_ Bin3 : 64|32@1+ (0.0002,0) [0|842216.243] "g" Vector__XXX
 SG_ Bin2 : 32|32@1+ (0.0002,0) [0|842216.243] "g" Vector__XXX
 SG_ Bin1 : 0|32@1+ (0.0002,0) [0|842216.243] "g" Vector__XXX

BO_ 2566590718 NTENS: 68 Vector__XXX
 SG_ Bin17 : 512|32@1+ (0.0005,0) [0|2105540.6075] "g" Vector__XXX
 SG_ Bin16 : 480|32@1+ (0.0005,0) [0|2105540.6075] "g" Vector__XXX
 SG_ Bin15 : 448|32@1+ (0.0005,0) [0|2105540.6075] "g" Vector__XXX
 SG_ Bin14 : 416|32@1+ (0.0005,0) [0|2105540.6075] "g" Vector__XXX
 SG_ Bin13 : 384|32@1+ (0.0005,0) [0|2105540.6075] "g" Vector__XXX
 SG_ Bin12 : 352|32@1+ (0.0005,0) [0|2105540.6075] "g" Vector__XXX
 SG_ Bin11 : 320|32@1+ (0.0005,0) [0|2105540.6075] "g" Vector__XXX
 SG_ Bin10 : 288|32@1+ (0.0005,0) [0|2105540.6075] "g" Vector__XXX
 SG_ Bin9 : 256|32@1+ (0.0005,0) [0|2105540.6075] "g" Vector__XXX
 SG_ Bin8 : 224|32@1+ (0.0005,0) [0|2105540.6075] "g" Vector__XXX
 SG_ Bin7 : 192|32@1+ (0.0005,0) [0|2105540.6075] "g" Vector__XXX
 SG_ Bin6 : 160|32@1+ (0.0005,0) [0|2105540.6075] "g" Vector__XXX
 SG_ Bin5 : 128|32@1+ (0.0005,0) [0|2105540.6075] "g" Vector__XXX
 SG_ Bin4 : 96|32@1+ (0.0005,0) [0|2105540.6075] "g" Vector__XXX
 SG_ Bin3 : 64|32@1+ (0.0005,0) [0|2105540.6075] "g" Vector__XXX
 SG_ Bin2 : 32|32@1+ (0.0005,0) [0|2105540.6075] "g" Vector__XXX
 SG_ Bin1 : 0|32@1+ (0.0005,0) [0|2105540.6075] "g" Vector__XXX

BO_ 2566590462 NTEES: 34 Vector__XXX
 SG_ Bin17 : 256|16@1+ (1,0) [0|64255] "kWh" Vector__XXX
 SG_ Bin16 : 240|16@1+ (1,0) [0|64255] "kWh" Vector__XXX
 SG_ Bin15 : 224|16@1+ (1,0) [0|64255] "kWh" Vector__XXX
 SG_ Bin14 : 208|16@1+ (1,0) [0|64255] "kWh" Vector__XXX
 SG_ Bin13 : 192|16@1+ (1,0) [0|64255] "kWh" Vector__XXX
 SG_ Bin12 : 176|16@1+ (1,0) [0|64255] "kWh" Vector__XXX
 SG_ Bin11 : 160|16@1+ (1,0) [0|64255] "kWh" Vector__XXX
 SG_ Bin10 : 144|16@1+ (1,0) [0|64255] "kWh" Vector__XXX
 SG_ Bin9 : 128|16@1+ (1,0) [0|64255] "kWh" Vector__XXX
 SG_ Bin8 : 112|16@1+ (1,0) [0|64255] "kWh" Vector__XXX
 SG_ Bin7 : 96|16@1+ (1,0) [0|64255] "kWh" Vector__XXX
 SG_ Bin6 : 80|16@1+ (1,0) [0|64255] "kWh" Vector__XXX
 SG_ Bin5 : 64|16@1+ (1,0) [0|64255] "kWh" Vector__XXX
 SG_ Bin4 : 48|16@1+ (1,0) [0|64255] "kWh" Vector__XXX
 SG_ Bin3 : 32|16@1+ (1,0) [0|64255] "kWh" Vector__XXX
 SG_ Bin2 : 16|16@1+ (1,0) [0|64255] "kWh" Vector__XXX
 SG_ Bin1 : 0|16@1+ (1,0) [0|64255] "kWh" Vector__XXX

BO_ 2566590206 NTVMS: 34 Vector__XXX
 SG_ Bin17 : 256|16@1+ (0.25,0) [0|16063.75] "km" Vector__XXX
 SG_ Bin16 : 240|16@1+ (0.25,0) [0|16063.75] "km" Vector__XXX
 SG_ Bin15 : 224|16@1+ (0.25,0) [0|16063.75] "km" Vector__XXX
 SG_ Bin14 : 208|16@1+ (0.25,0) [0|16063.75] "km" Vector__XXX
 SG_ Bin13 : 192|16@1+ (0.25,0) [0|16063.75] "km" Vector__XXX
 SG_ Bin12 : 176|16@1+ (0.25,0) [0|16063.75] "km" Vector__XXX
 SG_ Bin11 : 160|16@1+ (0.25,0) [0|16063.75] "km" Vector__XXX
 SG_ Bin10 : 144|16@1+ (0.25,0) [0|16063.75] "km" Vector__XXX
 SG_ Bin9 : 128|16@1+ (0.25,0) [0|16063.75] "km" Vector__XXX
 SG_ Bin8 : 112|16@1+ (0.25,0) [0|16063.75] "km" Vector__XXX
 SG_ Bin7 : 96|16@1+ (0.25,0) [0|16063.75] "km" Vector__XXX
 SG_ Bin6 : 80|16@1+ (0.25,0) [0|16063.75] "km" Vector__XXX
 SG_ Bin5 : 64|16@1+ (0.25,0) [0|16063.75] "km" Vector__XXX
 SG_ Bin4 : 48|16@1+ (0.25,0) [0|16063.75] "km" Vector__XXX
 SG_ Bin3 : 32|16@1+ (0.25,0) [0|16063.75] "km" Vector__XXX
 SG_ Bin2 : 16|16@1+ (0.25,0) [0|16063.75] "km" Vector__XXX
 SG_ Bin1 : 0|16@1+ (0.25,0) [0|16063.75] "km" Vector__XXX

BO_ 2566589950 NTEHS: 34 Vector__XXX
 SG_ Bin17 : 256|16@1+ (10,0) [0|642550] "s" Vector__XXX
 SG_ Bin16 : 240|16@1+ (10,0) [0|642550] "s" Vector__XXX
 SG_ Bin15 : 224|16@1+ (10,0) [0|642550] "s" Vector__XXX
 SG_ Bin14 : 208|16@1+ (10,0) [0|642550] "s" Vector__XXX
 SG_ Bin13 : 192|16@1+ (10,0) [0|642550] "s" Vector__XXX
 SG_ Bin12 : 176|16@1+ (10,0) [0|642550] "s" Vector__XXX
 SG_ Bin11 : 160|16@1+ (10,0) [0|642550] "s" Vector__XXX
 SG_ Bin10 : 144|16@1+ (10,0) [0|642550] "s" Vector__XXX
 SG_ Bin9 : 128|16@1+ (10,0) [0|642550] "s" Vector__XXX
 SG_ Bin8 : 112|16@1+ (10,0) [0|642550] "s" Vector__XXX
 SG_ Bin7 : 96|16@1+ (10,0) [0|642550] "s" Vector__XXX
 SG_ Bin6 : 80|16@1+ (10,0) [0|642550] "s" Vector__XXX
 SG_ Bin5 : 64|16@1+ (10,0) [0|642550] "s" Vector__XXX
 SG_ Bin4 : 48|16@1+ (10,0) [0|642550] "s" Vector__XXX
 SG_ Bin3 : 32|16@1+ (10,0) [0|642550] "s" Vector__XXX
 SG_ Bin2 : 16|16@1+ (10,0) [0|642550] "s" Vector__XXX
 SG_ Bin1 : 0|16@1+ (10,0) [0|642550] "s" Vector__XXX

BO_ 2566589694 NTFCS: 34 Vector__XXX
 SG_ Bin17 : 256|16@1+ (0.5,0) [0|32127.5] "l" Vector__XXX
 SG_ Bin16 : 240|16@1+ (0.5,0) [0|32127.5] "l" Vector__XXX
 SG_ Bin15 : 224|16@1+ (0.5,0) [0|32127.5] "l" Vector__XXX
 SG_ Bin14 : 208|16@1+ (0.5,0) [0|32127.5] "l" Vector__XXX
 SG_ Bin13 : 192|16@1+ (0.5,0) [0|32127.5] "l" Vector__XXX
 SG_ Bin12 : 176|16@1+ (0.5,0) [0|32127.5] "l" Vector__XXX
 SG_ Bin11 : 160|16@1+ (0.5,0) [0|32127.5] "l" Vector__XXX
 SG_ Bin10 : 144|16@1+ (0.5,0) [0|32127.5] "l" Vector__XXX
 SG_ Bin9 : 128|16@1+ (0.5,0) [0|32127.5] "l" Vector__XXX
 SG_ Bin8 : 112|16@1+ (0.5,0) [0|32127.5] "l" Vector__XXX
 SG_ Bin7 : 96|16@1+ (0.5,0) [0|32127.5] "l" Vector__XXX
 SG_ Bin6 : 80|16@1+ (0.5,0) [0|32127.5] "l" Vector__XXX
 SG_ Bin5 : 64|16@1+ (0.5,0) [0|32127.5] "l" Vector__XXX
 SG_ Bin4 : 48|16@1+ (0.5,0) [0|32127.5] "l" Vector__XXX
 SG_ Bin3 : 32|16@1+ (0.5,0) [0|32127.5] "l" Vector__XXX
 SG_ Bin2 : 16|16@1+ (0.5,0) [0|32127.5] "l" Vector__XXX
 SG_ Bin1 : 0|16@1+ (0.5,0) [0|32127.5] "l" Vector__XXX

BO_ 2566589438 NTSNV: 68 Vector__XXX
 SG_ Bin17 : 512|32@1+ (1,0) [0|4211081215] "g" Vector__XXX
 SG_ Bin16 : 480|32@1+ (1,0) [0|4211081215] "g" Vector__XXX
 SG_ Bin15 : 448|32@1+ (1,0) [0|4211081215] "g" Vector__XXX
 SG_ Bin14 : 416|32@1+ (1,0) [0|4211081215] "g" Vector__XXX
 SG_ Bin13 : 384|32@1+ (1,0) [0|4211081215] "g" Vector__XXX
 SG_ Bin12 : 352|32@1+ (1,0) [0|4211081215] "g" Vector__XXX
 SG_ Bin11 : 320|32@1+ (1,0) [0|4211081215] "g" Vector__XXX
 SG_ Bin10 : 288|32@1+ (1,0) [0|4211081215] "g" Vector__XXX
 SG_ Bin9 : 256|32@1+ (1,0) [0|4211081215] "g" Vector__XXX
 SG_ Bin8 : 224|32@1+ (1,0) [0|4211081215] "g" Vector__XXX
 SG_ Bin7 : 192|32@1+ (1,0) [0|4211081215] "g" Vector__XXX
 SG_ Bin6 : 160|32@1+ (1,0) [0|4211081215] "g" Vector__XXX
 SG_ Bin5 : 128|32@1+ (1,0) [0|4211081215] "g" Vector__XXX
 SG_ Bin4 : 96|32@1+ (1,0) [0|4211081215] "g" Vector__XXX
 SG_ Bin3 : 64|32@1+ (1,0) [0|4211081215] "g" Vector__XXX
 SG_ Bin2 : 32|32@1+ (1,0) [0|4211081215] "g" Vector__XXX
 SG_ Bin1 : 0|32@1+ (1,0) [0|4211081215] "g" Vector__XXX

BO_ 2566589182 NTENV: 68 Vector__XXX
 SG_ Bin17 : 512|32@1+ (1,0) [0|4211081215] "g" Vector__XXX
 SG_ Bin16 : 480|32@1+ (1,0) [0|4211081215] "g" Vector__XXX
 SG_ Bin15 : 448|32@1+ (1,0) [0|4211081215] "g" Vector__XXX
 SG_ Bin14 : 416|32@1+ (1,0) [0|4211081215] "g" Vector__XXX
 SG_ Bin13 : 384|32@1+ (1,0) [0|4211081215] "g" Vector__XXX
 SG_ Bin12 : 352|32@1+ (1,0) [0|4211081215] "g" Vector__XXX
 SG_ Bin11 : 320|32@1+ (1,0) [0|4211081215] "g" Vector__XXX
 SG_ Bin10 : 288|32@1+ (1,0) [0|4211081215] "g" Vector__XXX
 SG_ Bin9 : 256|32@1+ (1,0) [0|4211081215] "g" Vector__XXX
 SG_ Bin8 : 224|32@1+ (1,0) [0|4211081215] "g" Vector__XXX
 SG_ Bin7 : 192|32@1+ (1,0) [0|4211081215] "g" Vector__XXX
 SG_ Bin6 : 160|32@1+ (1,0) [0|4211081215] "g" Vector__XXX
 SG_ Bin5 : 128|32@1+ (1,0) [0|4211081215] "g" Vector__XXX
 SG_ Bin4 : 96|32@1+ (1,0) [0|4211081215] "g" Vector__XXX
 SG_ Bin3 : 64|32@1+ (1,0) [0|4211081215] "g" Vector__XXX
 SG_ Bin2 : 32|32@1+ (1,0) [0|4211081215] "g" Vector__XXX
 SG_ Bin1 : 0|32@1+ (1,0) [0|4211081215] "g" Vector__XXX

CM_ BO_ 2566603006 "Motor/Generator 4 Inverter Temperature
Inverter Temperature Status Message";
CM_ SG_ 2566603006 Five "The exact location of this temperature can be defined by the manufacturer. It is intended to be located somewhere on the inverter.";
CM_ SG_ 2566603006 Four "The exact location of this temperature can be defined by the manufacturer.  It is intended to be located somewhere on the inverter.";
CM_ SG_ 2566603006 Three "The exact location of this temperature can be defined by the manufacturer.  It is intended to be located somewhere on the inverter.";
CM_ SG_ 2566603006 Two "The exact location of this temperature can be defined by the manufacturer.  It is intended to be located somewhere on the inverter.";
CM_ SG_ 2566603006 One "The exact location of this temperature can be defined by the manufacturer.  It is intended to be located somewhere on the inverter.";
CM_ BO_ 2365276158 "Motor/Generator 4 Inverter Reference 2
The electrical reference values from this inverter.";
CM_ SG_ 2365276158 V "This value is used for converting inverter voltage in percent to units of Volts (RMS or DC).
(Value in Volts) = (Percent Value)/(100%) * (Reference Voltage)
For example, if this parameter has a value of 400 V and the percent value is equal to 75%, ...";
CM_ SG_ 2365276158 Cur "This value is used for converting inverter current in percent to units of Amps (RMS or DC).
(Value in Amps) = (Percent Value)/(100%) * (Reference Current)
For example, if this parameter has a value of 200 A and the percent value is equal to 75%, ...";
CM_ SG_ 2365276158 Counter "The message counter is used to detect situations where the transmitting ECU malfunction repeats the same frame all the time. The receiver of the information may use the counter parameter to detect this situation. The transmitting device will ...";
CM_ SG_ 2365276158 CRC "The CRC is defined as follows:
• Length: 8 bits
• Polynomial: x^8+x^5+x^3+x^2+x+1
• Initial Value: FFh
• Input Data Reflection: Not reflected
• Result Data Reflection: Not reflected
• XOR value: FFh
SAE makes no claim of the functional safety ...";
CM_ BO_ 2365275902 "Motor/Generator 4 Inverter Status 1
First Status Message from the Inverter.  Some examples of use would be for a hybrid or electric vehicle propulsion motor or generator.";
CM_ SG_ 2365275902 DCSideV "The measured or estimated DC side voltage.  

Refer to SPN 11972 [Reference Voltage] to convert % to Volts.";
CM_ SG_ 2365275902 DCSideCur "This is the DC side current of the inverter.
Refer to SPN 11971 [Reference Current] to convert % to Amps.
While motoring, the current is defined as positive.  For example, in a hybrid propulsion system, positive current flows from the HVES through ...";
CM_ SG_ 2365275902 Spd "The measured or estimated motor speed.  This refers to the motor rotor output and excludes any gearbox that may be attached to the motor.   

Refer to SPN 11940 [Reference Speed] to convert % to rpm.";
CM_ SG_ 2365275902 Trq "The measured or estimated motor torque.  This refers to the motor rotor output and excludes any gearbox that may be attached to the motor.
Refer to SPN 11939 [Reference Torque] to convert % to Nm.
The motor is generating when SPN 11919 [Speed] and ...";
CM_ SG_ 2365275902 Counter "The message counter is used to detect situations where the transmitting ECU malfunction repeats the same frame all the time. The receiver of the information may use the counter parameter to detect this situation. The transmitting device will ...";
CM_ SG_ 2365275902 CRC "The CRC is defined as follows:
• Length: 8 bits
• Polynomial: x^8+x^5+x^3+x^2+x+1
• Initial Value: FFh
• Input Data Reflection: Not reflected
• Result Data Reflection: Not reflected
• XOR value: FFh
SAE makes no claim of the functional safety ...";
CM_ BO_ 2365275646 "Motor/Generator 4 Inverter Reference 1
The torque and speed reference values from this inverter.";
CM_ SG_ 2365275646 Pwr "This value is used for converting power in percent to units of kW.  It is applicable to both mechanical and electrical power.
(Value in kW) = (Percent Value)/(100%) * (Reference Power)
For example, if this parameter has a value of 400 kW and the ...";
CM_ SG_ 2365275646 Spd "This value is used for converting Speed in percent to units of rpm.
Value in rpm = (Percent Value)/(100%) * (Reference Speed)
For example, if this parameter has a value of 8192 rpm and the percent value is equal to 75%, then the value in rpm will ...";
CM_ SG_ 2365275646 Trq "This value is used for converting torque in percent to units of Nm.
Value in Nm = (Percent Value)/(100%) * (Reference Torque)
For example, if this parameter has a value of 400 Nm and the percent value is equal to 75%, then the value in Nm will be ...";
CM_ SG_ 2365275646 Counter "The message counter is used to detect situations where the transmitting ECU malfunction repeats the same frame all the time. The receiver of the information may use the counter parameter to detect this situation. The transmitting device will ...";
CM_ SG_ 2365275646 CRC "The CRC is defined as follows:
• Length: 8 bits
• Polynomial: x^8+x^5+x^3+x^2+x+1
• Initial Value: FFh
• Input Data Reflection: Not reflected
• Result Data Reflection: Not reflected
• XOR value: FFh
SAE makes no claim of the functional safety ...";
CM_ BO_ 2566601982 "Motor/Generator 5 Inverter Active Power Limits
Sent by this Motor/Generator Inverter instance and contains the current operating conditions of the inverter.  This message would be received by a controller application that is responsible for ...";
CM_ SG_ 2566601982 TrqLimDueToMachineCharacter_0003 "Output torque is being limited due to SPN 12039 [Torque] approaching or exceeding a motor design characteristic.  For example, for permanent magnet machines, this would be in the field weakening area.
00b = No torque limit for this reason
01b = ...";
CM_ SG_ 2566601982 PLedDueToActiveSpdRateLmt "Output power is being limited due to exceeding internally defined speed rate limit(s) or SPN 12142 [Inverter Rate Limits Request Absolute Speed Rate Limit].
00b = No power limit for this reason
01b = Power limited for this reason
10b = Error
11b ...";
CM_ SG_ 2566601982 PLedDueToActiveTrqRateLmt "Output power is being limited due to exceeding internally defined torque rate limit(s) or SPN 12143 [Inverter Rate Limits Request Absolute Torque Rate Limit].
00b = No power limit for this reason
01b = Power limited for this reason
10b = Error
 ...";
CM_ SG_ 2566601982 PLedDueToFaultCondition "Output power is being limited due to an fault condition that requires a torque limitation to prevent further damage (e.g. “limp home mode”).  For example, this could be in case of temperature sensor defects.  Typically, this parameter would be ...";
CM_ SG_ 2566601982 PLedDueToMotorTemp "Output power is being limited due to one or more motor temperature(s), see SPNs 12038 and 12107 through 12109 [Motor Temperature 1-4] approaching or exceeding internally defined limit(s).
00b = No power limit for this reason
01b = Power limited ...";
CM_ SG_ 2566601982 PLedDueToInvTemp "Output power is being limited due to one or more inverter temperature(s), see SPNs 12103 through 12106 [Inverter Temperature 1-4] approaching or exceeding internally defined limit(s).
00b = No power limit for this reason
01b = Power limited for ...";
CM_ SG_ 2566601982 PLedDueToSpdMin "Output power is being limited due to SPN 12037 [Speed] approaching or falling below the SPN 12086 [Inverter Limits Active Speed Minimum].

00b = No power limit for this reason
01b = Power limited for this reason
10b = Error
11b = Not Available";
CM_ SG_ 2566601982 PLedDueToSpdMax "Output power is being limited due to SPN 12037 [Speed] approaching or exceeding the SPN 12085 [Inverter Limits Active Speed Maximum].

00b = No power limit for this reason
01b = Power limited for this reason
10b = Error
11b = Not Available";
CM_ SG_ 2566601982 PLedDueToTrqMin "Output power is being limited due to SPN 12039 [Torque] approaching or falling below the SPN 12084 [Inverter Limits Active Torque Minimum].
00b = No power limit for this reason
01b = Power limited for this reason
10b = Error
11b = Not Available
 ...";
CM_ SG_ 2566601982 PLedDueToTrqMax "Output power is being limited due to SPN 12039 [Torque] approaching or exceeding the SPN 12083 [Inverter Limits Active Torque Maximum].

00b = No power limit for this reason
01b = Power limited for this reason
10b = Error
11b = Not Available";
CM_ SG_ 2566601982 PLedDueToDCSidePwrMin "Output power is being limited due to DC Side Power (product of SPN 12062 [Inverter DC Side Current] and SPN 12040 [Inverter DC Side Voltage]) approaching or falling below the SPN 12074 [Inverter Limits Active DC Side Power Minimum].
00b = No power ...";
CM_ SG_ 2566601982 PLedDueToDCSidePwrMax "Output power is being limited due to DC Side Power (product of SPN 12062 [Inverter DC Side Current] and SPN 12040 [Inverter DC Side Voltage]) approaching or exceeding the SPN 12073 [Inverter Limits Active DC Side Power Maximum].
00b = No power ...";
CM_ SG_ 2566601982 PLedDueToMechPwrMin "Output power is being limited due to Mechanical Power (product of SPN 12039 [Torque] and SPN 12037 [Speed]) approaching or falling below the SPN 12072 [Inverter Limits Active Mechanical Power Minimum].
00b = No power limit for this reason
01b = ...";
CM_ SG_ 2566601982 PLedDueToMechPwrMax "Output power is being limited due to Mechanical Power (product of SPN 12039 [Torque] and SPN 12037 [Speed]) approaching or exceeding the SPN 12071 [Inverter Limits Active Mechanical Power Maximum].
00b = No power limit for this reason
01b = Power ...";
CM_ SG_ 2566601982 PLedDueToDCSideVMin "Output power is being limited due to SPN 12040 [Inverter DC Side Voltage] approaching or falling below the SPN 12100 [Inverter Limits Active DC Side Voltage Minimum].
00b = No power limit for this reason
01b = Power limited for this reason
10b = ...";
CM_ SG_ 2566601982 PLedDueToDCSideVMax "Output power is being limited due to SPN 12040 [Inverter DC Side Voltage] approaching or exceeding the SPN 12099 [Inverter Limits Active DC Side Voltage Maximum].
00b = No power limit for this reason
01b = Power limited for this reason
10b = ...";
CM_ SG_ 2566601982 PLedDueToDCSideCurMin "Output power is being limited due to SPN 12062 [Inverter DC Side Current] approaching or falling below the SPN 12102 [Inverter Limits Active DC Side Current Minimum].
00b = No power limit for this reason
01b = Power limited for this reason
10b = ...";
CM_ SG_ 2566601982 PLedDueToDCSideCurMax "Output power is being limited due to SPN 12062 [Inverter DC Side Current] approaching or exceeding the SPN 12101 [Inverter Limits Active DC Side Current Maximum].
00b = No power limit for this reason
01b = Power limited for this reason
10b = ...";
CM_ SG_ 2566601982 PLedDueToUndefinedReason "Output power is being limited due to an undefined reason.

00b = No power limit for this reason
01b = Power limited for this reason
10b = Error
11b = Not Available";
CM_ BO_ 2566601726 "Motor/Generator 5 Inverter Isolation Integrity
The electrical isolation Integrity status of the Inverter.  Some examples of use would be for a hybrid or electric vehicle propulsion motor or generator.";
CM_ SG_ 2566601726 HVBusPassiveIsolTestResults "The isolation resistance that resulted from the High-Voltage Bus Passive Isolation Test.
See SPN 12122 [High-Voltage Bus Passive Isolation Test Status] for test status and SPN 12115 [High-Voltage Bus Passive Isolation Test Command] for the command ...";
CM_ SG_ 2566601726 HVBusActiveIsolTestResults "The isolation resistance that resulted from the High-Voltage Bus Active Isolation Test.
See SPN 12121 [High-Voltage Bus Active Isolation Test Status] for test status and SPN 12114 [High-Voltage Bus Active Isolation Test Command] for the command to ...";
CM_ SG_ 2566601726 HVBusPassiveIsolTestStatus "Status of the high-voltage bus electrical passive isolation test as performed by this instance of the Motor/Generator.
0000b = No test requested / No test in process
0001b = Test requested but not yet in process
0010b = Test in process
0011b = ...";
CM_ SG_ 2566601726 HVBusActiveIsolTestStatus "Status of the high-voltage bus electrical active isolation test as performed by this instance of the Motor/Generator.
0000b = No test requested / No test in process
0001b = Test requested but not yet in process
0010b = Test in process
0011b = ...";
CM_ SG_ 2566601726 DCSideNegToChassisGroundV "The voltage level of the high voltage DC side, as measured by the inverter between the negative side of the High Voltage DC Side input and the chassis of the inverter enclosure.  This voltage can be used for system level monitoring of DC Side High ...";
CM_ SG_ 2566601726 Counter "The message counter is used to detect situations where the transmitting ECU malfunction repeats the same frame all the time. The receiver of the information may use the counter parameter to detect this situation. The transmitting device will ...";
CM_ SG_ 2566601726 CRC "The CRC is defined as follows:
• Length: 8 bits
• Polynomial: x^8+x^5+x^3+x^2+x+1
• Initial Value: FFh
• Input Data Reflection: Not reflected
• Result Data Reflection: Not reflected
• XOR value: FFh
SAE makes no claim of the functional safety ...";
CM_ BO_ 2566601470 "Motor/Generator 5 Inverter Motor Temperature
Motor Temperature Status Message";
CM_ SG_ 2566601470 Temp4 "The exact location of this temperature can be defined by the manufacturer.  It is intended to located somewhere on the motor.";
CM_ SG_ 2566601470 Temp3 "The exact location of this temperature can be defined by the manufacturer.  It is intended to located somewhere on the motor.";
CM_ SG_ 2566601470 Temp2 "The exact location of this temperature can be defined by the manufacturer.  It is intended to located somewhere on the motor.";
CM_ SG_ 2566601470 Temp1 "The exact location of this temperature can be defined by the manufacturer.  It is intended to located somewhere on the motor.";
CM_ BO_ 2566601214 "Motor/Generator 5 Inverter Temperature
Inverter Temperature Status Message";
CM_ SG_ 2566601214 Five "The exact location of this temperature can be defined by the manufacturer. It is intended to be located somewhere on the inverter.";
CM_ SG_ 2566601214 Four "The exact location of this temperature can be defined by the manufacturer.  It is intended to be located somewhere on the inverter.";
CM_ SG_ 2566601214 Three "The exact location of this temperature can be defined by the manufacturer.  It is intended to be located somewhere on the inverter.";
CM_ SG_ 2566601214 Two "The exact location of this temperature can be defined by the manufacturer.  It is intended to be located somewhere on the inverter.";
CM_ SG_ 2566601214 One "The exact location of this temperature can be defined by the manufacturer.  It is intended to be located somewhere on the inverter.";
CM_ BO_ 2365274366 "Motor/Generator 5 Inverter Reference 2
The electrical reference values from this inverter.";
CM_ SG_ 2365274366 V "This value is used for converting inverter voltage in percent to units of Volts (RMS or DC).
(Value in Volts) = (Percent Value)/(100%) * (Reference Voltage)
For example, if this parameter has a value of 400 V and the percent value is equal to 75%, ...";
CM_ SG_ 2365274366 Cur "This value is used for converting inverter current in percent to units of Amps (RMS or DC).
(Value in Amps) = (Percent Value)/(100%) * (Reference Current)
For example, if this parameter has a value of 200 A and the percent value is equal to 75%, ...";
CM_ SG_ 2365274366 Counter "The message counter is used to detect situations where the transmitting ECU malfunction repeats the same frame all the time. The receiver of the information may use the counter parameter to detect this situation. The transmitting device will ...";
CM_ SG_ 2365274366 CRC "The CRC is defined as follows:
• Length: 8 bits
• Polynomial: x^8+x^5+x^3+x^2+x+1
• Initial Value: FFh
• Input Data Reflection: Not reflected
• Result Data Reflection: Not reflected
• XOR value: FFh
SAE makes no claim of the functional safety ...";
CM_ BO_ 2365274110 "Motor/Generator 5 Inverter Status 1
First Status Message from the Inverter.  Some examples of use would be for a hybrid or electric vehicle propulsion motor or generator.";
CM_ SG_ 2365274110 DCSideV "The measured or estimated DC side voltage.  

Refer to SPN 12090 [Reference Voltage] to convert % to Volts.";
CM_ SG_ 2365274110 DCSideCur "This is the DC side current of the inverter.
Refer to SPN 12089 [Reference Current] to convert % to Amps.
While motoring, the current is defined as positive.  For example, in a hybrid propulsion system, positive current flows from the HVES through ...";
CM_ SG_ 2365274110 Spd "The measured or estimated motor speed.  This refers to the motor rotor output and excludes any gearbox that may be attached to the motor.   

Refer to SPN 12058 [Reference Speed] to convert % to rpm.";
CM_ SG_ 2365274110 Trq "The measured or estimated motor torque.  This refers to the motor rotor output and excludes any gearbox that may be attached to the motor.
Refer to SPN 12057 [Reference Torque] to convert % to Nm.
The motor is generating when SPN 12037 [Speed] and ...";
CM_ SG_ 2365274110 Counter "The message counter is used to detect situations where the transmitting ECU malfunction repeats the same frame all the time. The receiver of the information may use the counter parameter to detect this situation. The transmitting device will ...";
CM_ SG_ 2365274110 CRC "The CRC is defined as follows:
• Length: 8 bits
• Polynomial: x^8+x^5+x^3+x^2+x+1
• Initial Value: FFh
• Input Data Reflection: Not reflected
• Result Data Reflection: Not reflected
• XOR value: FFh
SAE makes no claim of the functional safety ...";
CM_ BO_ 2365273854 "Motor/Generator 5 Inverter Reference 1
The torque and speed reference values from this inverter.";
CM_ SG_ 2365273854 Pwr "This value is used for converting power in percent to units of kW.  It is applicable to both mechanical and electrical power.
(Value in kW) = (Percent Value)/(100%) * (Reference Power)
For example, if this parameter has a value of 400 kW and the ...";
CM_ SG_ 2365273854 Spd "This value is used for converting Speed in percent to units of rpm.
Value in rpm = (Percent Value)/(100%) * (Reference Speed)
For example, if this parameter has a value of 8192 rpm and the percent value is equal to 75%, then the value in rpm will ...";
CM_ SG_ 2365273854 Trq "This value is used for converting torque in percent to units of Nm.
Value in Nm = (Percent Value)/(100%) * (Reference Torque)
For example, if this parameter has a value of 400 Nm and the percent value is equal to 75%, then the value in Nm will be ...";
CM_ SG_ 2365273854 Counter "The message counter is used to detect situations where the transmitting ECU malfunction repeats the same frame all the time. The receiver of the information may use the counter parameter to detect this situation. The transmitting device will ...";
CM_ SG_ 2365273854 CRC "The CRC is defined as follows:
• Length: 8 bits
• Polynomial: x^8+x^5+x^3+x^2+x+1
• Initial Value: FFh
• Input Data Reflection: Not reflected
• Result Data Reflection: Not reflected
• XOR value: FFh
SAE makes no claim of the functional safety ...";
CM_ BO_ 2566600190 "Motor/Generator 6 Inverter Active Power Limits
Sent by this Motor/Generator Inverter instance and contains the current operating conditions of the inverter.  This message would be received by a controller application that is responsible for ...";
CM_ SG_ 2566600190 TrqLimDueToMachineCharacter_0004 "Output torque is being limited due to SPN 12157 [Torque] approaching or exceeding a motor design characteristic.  For example, for permanent magnet machines, this would be in the field weakening area.
00b = No torque limit for this reason
01b = ...";
CM_ SG_ 2566600190 PLedDueToActiveSpdRateLmt "Output power is being limited due to exceeding internally defined speed rate limit(s) or SPN 12260 [Inverter Rate Limits Request Absolute Speed Rate Limit].
00b = No power limit for this reason
01b = Power limited for this reason
10b = Error
11b ...";
CM_ SG_ 2566600190 PLedDueToActiveTrqRateLmt "Output power is being limited due to exceeding internally defined torque rate limit(s) or SPN 12261 [Inverter Rate Limits Request Absolute Torque Rate Limit].
00b = No power limit for this reason
01b = Power limited for this reason
10b = Error
 ...";
CM_ SG_ 2566600190 PLedDueToFaultCondition "Output power is being limited due to an fault condition that requires a torque limitation to prevent further damage (e.g. “limp home mode”).  For example, this could be in case of temperature sensor defects.  Typically, this parameter would be ...";
CM_ SG_ 2566600190 PLedDueToMotorTemp "Output power is being limited due to one or more motor temperature(s), see SPNs 12156 and 12225 through 12227 [Motor Temperature 1-4] approaching or exceeding internally defined limit(s).
00b = No power limit for this reason
01b = Power limited ...";
CM_ SG_ 2566600190 PLedDueToInvTemp "Output power is being limited due to one or more inverter temperature(s), see SPNs 12221 through 12224 [Inverter Temperature 1-4] approaching or exceeding internally defined limit(s).
00b = No power limit for this reason
01b = Power limited for ...";
CM_ SG_ 2566600190 PLedDueToSpdMin "Output power is being limited due to SPN 12155 [Speed] approaching or falling below the SPN 12204 [Inverter Limits Active Speed Minimum].

00b = No power limit for this reason
01b = Power limited for this reason
10b = Error
11b = Not Available";
CM_ SG_ 2566600190 PLedDueToSpdMax "Output power is being limited due to SPN 12155 [Speed] approaching or exceeding the SPN 12203 [Inverter Limits Active Speed Maximum].

00b = No power limit for this reason
01b = Power limited for this reason
10b = Error
11b = Not Available";
CM_ SG_ 2566600190 PLedDueToTrqMin "Output power is being limited due to SPN 12157 [Torque] approaching or falling below the SPN 12202 [Inverter Limits Active Torque Minimum].
00b = No power limit for this reason
01b = Power limited for this reason
10b = Error
11b = Not Available
 ...";
CM_ SG_ 2566600190 PLedDueToTrqMax "Output power is being limited due to SPN 12157 [Torque] approaching or exceeding the SPN 12201 [Inverter Limits Active Torque Maximum].

00b = No power limit for this reason
01b = Power limited for this reason
10b = Error
11b = Not Available";
CM_ SG_ 2566600190 PLedDueToDCSidePwrMin "Output power is being limited due to DC Side Power (product of SPN 12180 [Inverter DC Side Current] and SPN 12158 [Inverter DC Side Voltage]) approaching or falling below the SPN 12192 [Inverter Limits Active DC Side Power Minimum].
00b = No power ...";
CM_ SG_ 2566600190 PLedDueToDCSidePwrMax "Output power is being limited due to DC Side Power (product of SPN 12180 [Inverter DC Side Current] and SPN 12158 [Inverter DC Side Voltage]) approaching or exceeding the SPN 12191 [Inverter Limits Active DC Side Power Maximum].
00b = No power ...";
CM_ SG_ 2566600190 PLedDueToMechPwrMin "Output power is being limited due to Mechanical Power (product of SPN 12157 [Torque] and SPN 12155 [Speed]) approaching or falling below the SPN 12190 [Inverter Limits Active Mechanical Power Minimum].
00b = No power limit for this reason
01b = ...";
CM_ SG_ 2566600190 PLedDueToMechPwrMax "Output power is being limited due to Mechanical Power (product of SPN 12157 [Torque] and SPN 12155 [Speed]) approaching or exceeding the SPN 12189 [Inverter Limits Active Mechanical Power Maximum].
00b = No power limit for this reason
01b = Power ...";
CM_ SG_ 2566600190 PLedDueToDCSideVMin "Output power is being limited due to SPN 12158 [Inverter DC Side Voltage] approaching or falling below the SPN 12218 [Inverter Limits Active DC Side Voltage Minimum].
00b = No power limit for this reason
01b = Power limited for this reason
10b = ...";
CM_ SG_ 2566600190 PLedDueToDCSideVMax "Output power is being limited due to SPN 12158 [Inverter DC Side Voltage] approaching or exceeding the SPN 12217 [Inverter Limits Active DC Side Voltage Maximum].
00b = No power limit for this reason
01b = Power limited for this reason
10b = ...";
CM_ SG_ 2566600190 PLedDueToDCSideCurMin "Output power is being limited due to SPN 12180 [Inverter DC Side Current] approaching or falling below the SPN 12220 [Inverter Limits Active DC Side Current Minimum].
00b = No power limit for this reason
01b = Power limited for this reason
10b = ...";
CM_ SG_ 2566600190 PLedDueToDCSideCurMax "Output power is being limited due to SPN 12180 [Inverter DC Side Current] approaching or exceeding the SPN 12219 [Inverter Limits Active DC Side Current Maximum].
00b = No power limit for this reason
01b = Power limited for this reason
10b = ...";
CM_ SG_ 2566600190 PLedDueToUndefinedReason "Output power is being limited due to an undefined reason.

00b = No power limit for this reason
01b = Power limited for this reason
10b = Error
11b = Not Available";
CM_ BO_ 2566599934 "Motor/Generator 6 Inverter Isolation Integrity
The electrical isolation Integrity status of the Inverter.  Some examples of use would be for a hybrid or electric vehicle propulsion motor or generator.";
CM_ SG_ 2566599934 HVBusPassiveIsolTestResults "The isolation resistance that resulted from the High-Voltage Bus Passive Isolation Test.
See SPN 12240 [High-Voltage Bus Passive Isolation Test Status] for test status and SPN 12233 [High-Voltage Bus Passive Isolation Test Command] for the command ...";
CM_ SG_ 2566599934 HVBusActiveIsolTestResults "The isolation resistance that resulted from the High-Voltage Bus Active Isolation Test.
See SPN 12239 [High-Voltage Bus Active Isolation Test Status] for test status and SPN 12232 [High-Voltage Bus Active Isolation Test Command] for the command to ...";
CM_ SG_ 2566599934 HVBusPassiveIsolTestStatus "Status of the high-voltage bus electrical passive isolation test as performed by this instance of the Motor/Generator.
0000b = No test requested / No test in process
0001b = Test requested but not yet in process
0010b = Test in process
0011b = ...";
CM_ SG_ 2566599934 HVBusActiveIsolTestStatus "Status of the high-voltage bus electrical active isolation test as performed by this instance of the Motor/Generator.
0000b = No test requested / No test in process
0001b = Test requested but not yet in process
0010b = Test in process
0011b = ...";
CM_ SG_ 2566599934 DCSideNegToChassisGroundV "The voltage level of the high voltage DC side, as measured by the inverter between the negative side of the High Voltage DC Side input and the chassis of the inverter enclosure.  This voltage can be used for system level monitoring of DC Side High ...";
CM_ SG_ 2566599934 Counter "The message counter is used to detect situations where the transmitting ECU malfunction repeats the same frame all the time. The receiver of the information may use the counter parameter to detect this situation. The transmitting device will ...";
CM_ SG_ 2566599934 CRC "The CRC is defined as follows:
• Length: 8 bits
• Polynomial: x^8+x^5+x^3+x^2+x+1
• Initial Value: FFh
• Input Data Reflection: Not reflected
• Result Data Reflection: Not reflected
• XOR value: FFh
SAE makes no claim of the functional safety ...";
CM_ BO_ 2566599678 "Motor/Generator 6 Inverter Motor Temperature
Motor Temperature Status Message";
CM_ SG_ 2566599678 Temp4 "The exact location of this temperature can be defined by the manufacturer.  It is intended to located somewhere on the motor.";
CM_ SG_ 2566599678 Temp3 "The exact location of this temperature can be defined by the manufacturer.  It is intended to located somewhere on the motor.";
CM_ SG_ 2566599678 Temp2 "The exact location of this temperature can be defined by the manufacturer.  It is intended to located somewhere on the motor.";
CM_ SG_ 2566599678 Temp1 "The exact location of this temperature can be defined by the manufacturer.  It is intended to located somewhere on the motor.";
CM_ BO_ 2566599422 "Motor/Generator 6 Inverter Temperature
Inverter Temperature Status Message";
CM_ SG_ 2566599422 Five "The exact location of this temperature can be defined by the manufacturer. It is intended to be located somewhere on the inverter.";
CM_ SG_ 2566599422 Four "The exact location of this temperature can be defined by the manufacturer.  It is intended to be located somewhere on the inverter.";
CM_ SG_ 2566599422 Three "The exact location of this temperature can be defined by the manufacturer.  It is intended to be located somewhere on the inverter.";
CM_ SG_ 2566599422 Two "The exact location of this temperature can be defined by the manufacturer.  It is intended to be located somewhere on the inverter.";
CM_ SG_ 2566599422 One "The exact location of this temperature can be defined by the manufacturer.  It is intended to be located somewhere on the inverter.";
CM_ BO_ 2365272574 "Motor/Generator 6 Inverter Reference 2
The electrical reference values from this inverter.";
CM_ SG_ 2365272574 V "This value is used for converting inverter voltage in percent to units of Volts (RMS or DC).
(Value in Volts) = (Percent Value)/(100%) * (Reference Voltage)
For example, if this parameter has a value of 400 V and the percent value is equal to 75%, ...";
CM_ SG_ 2365272574 Cur "This value is used for converting inverter current in percent to units of Amps (RMS or DC).
(Value in Amps) = (Percent Value)/(100%) * (Reference Current)
For example, if this parameter has a value of 200 A and the percent value is equal to 75%, ...";
CM_ SG_ 2365272574 Counter "The message counter is used to detect situations where the transmitting ECU malfunction repeats the same frame all the time. The receiver of the information may use the counter parameter to detect this situation. The transmitting device will ...";
CM_ SG_ 2365272574 CRC "The CRC is defined as follows:
• Length: 8 bits
• Polynomial: x^8+x^5+x^3+x^2+x+1
• Initial Value: FFh
• Input Data Reflection: Not reflected
• Result Data Reflection: Not reflected
• XOR value: FFh
SAE makes no claim of the functional safety ...";
CM_ BO_ 2365272318 "Motor/Generator 6 Inverter Status 1
First Status Message from the Inverter.  Some examples of use would be for a hybrid or electric vehicle propulsion motor or generator.";
CM_ SG_ 2365272318 DCSideV "The measured or estimated DC side voltage.  

Refer to SPN 12208 [Reference Voltage] to convert % to Volts.";
CM_ SG_ 2365272318 DCSideCur "This is the DC side current of the inverter.
Refer to SPN 12207 [Reference Current] to convert % to Amps.
While motoring, the current is defined as positive.  For example, in a hybrid propulsion system, positive current flows from the HVES through ...";
CM_ SG_ 2365272318 Spd "The measured or estimated motor speed.  This refers to the motor rotor output and excludes any gearbox that may be attached to the motor.   

Refer to SPN 12176 [Reference Speed] to convert % to rpm.";
CM_ SG_ 2365272318 Trq "The measured or estimated motor torque.  This refers to the motor rotor output and excludes any gearbox that may be attached to the motor.
Refer to SPN 12175 [Reference Torque] to convert % to Nm.
The motor is generating when SPN 12155 [Speed] and ...";
CM_ SG_ 2365272318 Counter "The message counter is used to detect situations where the transmitting ECU malfunction repeats the same frame all the time. The receiver of the information may use the counter parameter to detect this situation. The transmitting device will ...";
CM_ SG_ 2365272318 CRC "The CRC is defined as follows:
• Length: 8 bits
• Polynomial: x^8+x^5+x^3+x^2+x+1
• Initial Value: FFh
• Input Data Reflection: Not reflected
• Result Data Reflection: Not reflected
• XOR value: FFh
SAE makes no claim of the functional safety ...";
CM_ BO_ 2365272062 "Motor/Generator 6 Inverter Reference 1
The torque and speed reference values from this inverter.";
CM_ SG_ 2365272062 Pwr "This value is used for converting power in percent to units of kW.  It is applicable to both mechanical and electrical power.
(Value in kW) = (Percent Value)/(100%) * (Reference Power)
For example, if this parameter has a value of 400 kW and the ...";
CM_ SG_ 2365272062 Spd "This value is used for converting Speed in percent to units of rpm.
Value in rpm = (Percent Value)/(100%) * (Reference Speed)
For example, if this parameter has a value of 8192 rpm and the percent value is equal to 75%, then the value in rpm will ...";
CM_ SG_ 2365272062 Trq "This value is used for converting torque in percent to units of Nm.
Value in Nm = (Percent Value)/(100%) * (Reference Torque)
For example, if this parameter has a value of 400 Nm and the percent value is equal to 75%, then the value in Nm will be ...";
CM_ SG_ 2365272062 Counter "The message counter is used to detect situations where the transmitting ECU malfunction repeats the same frame all the time. The receiver of the information may use the counter parameter to detect this situation. The transmitting device will ...";
CM_ SG_ 2365272062 CRC "The CRC is defined as follows:
• Length: 8 bits
• Polynomial: x^8+x^5+x^3+x^2+x+1
• Initial Value: FFh
• Input Data Reflection: Not reflected
• Result Data Reflection: Not reflected
• XOR value: FFh
SAE makes no claim of the functional safety ...";
CM_ BO_ 2566598398 "Winch Information 2
Message provides status information for a winch";
CM_ SG_ 2566598398 RevolutionCounter "Accumulated number of revolutions of winch motor during its operation. This includes both forward and reverse directions and may be used for maintenance purposes.";
CM_ BO_ 2566598142 "Turbocharger Information 8
Turbocharger Information";
CM_ SG_ 2566598142 EngTC6CompressorInPress "Gage pressure of the air entering the compressor side of the turbocharger.";
CM_ SG_ 2566598142 EngTC5CompressorInPress "Gage pressure of the air entering the compressor side of the turbocharger.";
CM_ SG_ 2566598142 EngTC6Spd "Rotational velocity of rotor in the turbocharger.";
CM_ SG_ 2566598142 EngTC5Spd "Rotational velocity of rotor in the turbocharger.";
CM_ BO_ 2566597630 "Motor/Generator 3 Inverter Isolation Integrity Request
Requests the Inverter to perform isoltation integritry related tests.";
CM_ SG_ 2566597630 HVBusLowSideResistorConnectReq "This parameter is used to request connection of the inverter High-Voltage bus low side resistor in order to perform an isolation test.  

00b = Connection not Requested
01b = Connection Requested
10b = Reserved
11b = Don’t care/take no action";
CM_ SG_ 2566597630 HVBusHiSideResistorConnectReq "This parameter is used to request connection of the inverter High-Voltage bus high side resistor in order to perform an isolation test. 

00b = Connection not Requested
01b = Connection Requested
10b = Reserved
11b = Don’t care/take no action";
CM_ SG_ 2566597630 HVBusPassiveIsolTestCmd "Command for the inverter to perform a passive electrical isolation test on the high voltage bus.
A passive isolation test uses additional circuitry (e.g. a high impedance network) to monitor the delta between the high voltage connections (e.g ...";
CM_ SG_ 2566597630 HVBusActiveIsolTestCmd "Command for the inverter to perform an active electrical isolation test on the high voltage bus.
An active isolation test might use a generated signal (e.g. an injected AC signal) and then monitor changes in the measurements of the isolated ...";
CM_ BO_ 2566597374 "Motor/Generator 3 Inverter Limits Request DC Side
Sets the DC Side Voltage and Current limits for the inverter being controlled.  Some examples of use would be for a hybrid or electric vehicle propulsion motor or generator.";
CM_ SG_ 2566597374 CurMin "This is a request to the inverter to set a minimum DC Side Current limit for this device instance.
Refer to SPN 11853 [Reference Current] to convert % to Amps.
Request a value of FBFh to instruct the inverter to use its default values.
While ...";
CM_ SG_ 2566597374 CurMax "This is a request to the inverter to set a maximum DC Side Current limit for this device instance.
Refer to SPN 11853 [Reference Current] to convert % to Amps.
Request a value of FBFh to instruct the inverter to use its default values.
While ...";
CM_ SG_ 2566597374 VMin "This is a request to the inverter to set a minimum DC Side Voltage limit for this device instance.
Refer to SPN 11854 [Reference Voltage] to convert % to Volts.
Request a value of FBFh to instruct the inverter to use its default values.
This ...";
CM_ SG_ 2566597374 VMax "This is a request to the inverter to set a maximum DC Side Voltage limit for this device instance.
Refer to SPN 11854 [Reference Voltage] to convert % to Volts.
Request a value of FBFh to instruct the inverter to use its default values.
This ...";
CM_ SG_ 2566597374 Counter "The message counter is used to detect situations where the transmitting ECU malfunction repeats the same frame all the time. The receiver of the information may use the counter parameter to detect this situation. The transmitting device will ...";
CM_ SG_ 2566597374 CRC "The CRC is defined as follows:
• Length: 8 bits
• Polynomial: x^8+x^5+x^3+x^2+x+1
• Initial Value: FFh
• Input Data Reflection: Not reflected
• Result Data Reflection: Not reflected
• XOR value: FFh
SAE makes no claim of the functional safety ...";
CM_ BO_ 2566597118 "Motor/Generator 3 Inverter Limits Request Mechanical
Sets the torque and speed limits for the inverter being controlled. Some examples of use would be for a hybrid or electric vehicle propulsion motor or generator.";
CM_ SG_ 2566597118 SpdMin "This is a request to the inverter to set a minimum speed limit for this device.
Refer to SPN 11822 [Reference Speed] to convert % to rpm.
Request a value of FBFh to instruct the inverter to use its default values.
One use of this message is for ...";
CM_ SG_ 2566597118 SpdMax "This is a request to the inverter to set a maximum speed limit for this device.
Refer to SPN 11822 [Reference Speed] to convert % to rpm.
Request a value of FBFh to instruct the inverter to use its default values.
One use of this message is for ...";
CM_ SG_ 2566597118 TrqMin "This requests a minimum torque the inverter should command for this device.
Refer to SPN 11821 [Reference Torque] to convert % to Nm.
Request a value of FBFh to instruct the inverter to use its default values.
For example, in a typical vehicle ...";
CM_ SG_ 2566597118 TrqMax "This requests a maximum torque the inverter should command for this device.
Refer to SPN 11821 [Reference Torque] to convert % to Nm.
Request a value of FBFh to instruct the inverter to use its default values.
For example, in a typical vehicle ...";
CM_ SG_ 2566597118 Counter "The message counter is used to detect situations where the transmitting ECU malfunction repeats the same frame all the time. The receiver of the information may use the counter parameter to detect this situation. The transmitting device will ...";
CM_ SG_ 2566597118 CRC "The CRC is defined as follows:
• Length: 8 bits
• Polynomial: x^8+x^5+x^3+x^2+x+1
• Initial Value: FFh
• Input Data Reflection: Not reflected
• Result Data Reflection: Not reflected
• XOR value: FFh
SAE makes no claim of the functional safety ...";
CM_ BO_ 2566596862 "Motor/Generator 3 Inverter Limits Request Power
Sets the electrical and mechanical power limits for the inverter being controlled.  Some examples of use would be for a hybrid or electric vehicle propulsion motor or generator.";
CM_ SG_ 2566596862 DCSidePwrMin "This requests a minimum limit for the DC Side power.
Refer to SPN 11823 [Reference Power] to convert % to kW.
Request a value of FBFh to instruct the inverter to use its default values.
For example, in a typical electric vehicle application, the ...";
CM_ SG_ 2566596862 DCSidePwrMax "This requests a maximum limit for the DC Side power.
Refer to SPN 11823 [Reference Power] to convert % to kW.
Request a value of FBFh to instruct the inverter to use its default values.
For example, in a typical electric vehicle application, the ...";
CM_ SG_ 2566596862 MechPwrMin "This requests a minimum limit for the mechanical power.
Refer to SPN 11823 [Reference Power] to convert % to kW.
Request a value of FBFh to instruct the inverter to use its default values.
For example, in a typical electric vehicle application, ...";
CM_ SG_ 2566596862 MechPwrMax "This requests a maximum limit for the mechanical power.
Refer to SPN 11823 [Reference Power] to convert % to kW.
Request a value of FBFh to instruct the inverter to use its default values.
For example, in a typical electric vehicle application, ...";
CM_ SG_ 2566596862 Counter "The message counter is used to detect situations where the transmitting ECU malfunction repeats the same frame all the time. The receiver of the information may use the counter parameter to detect this situation. The transmitting device will ...";
CM_ SG_ 2566596862 CRC "The CRC is defined as follows:
• Length: 8 bits
• Polynomial: x^8+x^5+x^3+x^2+x+1
• Initial Value: FFh
• Input Data Reflection: Not reflected
• Result Data Reflection: Not reflected
• XOR value: FFh
SAE makes no claim of the functional safety ...";
CM_ BO_ 2365270014 "Motor/Generator 3 Inverter Control 2
Secondary control message from this instance of Inverter.  Some examples of use would be for a hybrid or electric vehicle propulsion motor or generator.";
CM_ SG_ 2365270014 PIDCtrlFeedForwardTrq "A PID controller can have a Feed-Forward Torque added to its output. This parameter defines the Feed-Forward Torque Setpoint for control applications in this inverter instance. The Setpoint is in %. Refer to SPN 11821 [Reference Torque] to convert % ...";
CM_ SG_ 2365270014 PIDCtrlNormalizedPropGain "A PID controller can be parametrized by factors Kp, Ki and Kd. This parameter defines the normalized proportional gain (Kpn) for control applications in this inverter instance. The normalization converts absolute physical ranges into normalized ...";
CM_ SG_ 2365270014 PIDCtrlNormalizedIntegralGain "A PID controller can be parametrized by factors Kp, Ki and Kd. This parameter defines the normalized integral gain (Kin) for control applications in this inverter instance. The normalization converts absolute physical ranges into normalized values, ...";
CM_ SG_ 2365270014 PIDCtrlNormalizedDiffGain "A PID controller can be parametrized by factors Kp, Ki and Kd. This parameter defines the normalized integral gain (Kin) for control applications in this inverter instance. The normalization converts absolute physical ranges into normalized values, ...";
CM_ SG_ 2365270014 PIDCtrlApplicableMode "Defines the Mode that the PID Gain parameters apply for this instance of the inverter.  See SPN 11818 [Control Setpoint Mode] for a definition of modes for control purposes.
Applicable modes:
0000b = Speed Control Mode
0001b = DC Side Voltage ...";
CM_ SG_ 2365270014 RateLimitsReq2Counter "The message counter is used to detect situations where the transmitting ECU malfunction repeats the same frame all the time. The receiver of the information may use the counter parameter to detect this situation. The transmitting device will ...";
CM_ SG_ 2365270014 RateLimitsReq2CRC "The CRC is defined as follows:
• Length: 8 bits
• Polynomial: x^8+x^5+x^3+x^2+x+1
• Initial Value: FFh
• Input Data Reflection: Not reflected
• Result Data Reflection: Not reflected
• XOR value: FFh
SAE makes no claim of the functional safety ...";
CM_ BO_ 2566596350 "Motor/Generator 4 Inverter Isolation Integrity Request
Requests the Inverter to perform isolation integrity related tests.";
CM_ SG_ 2566596350 HVBusLowSideResistorConnectReq "This parameter is used to request connection of the inverter High-Voltage bus low side resistor in order to perform an isolation test.  

00b = Connection not Requested
01b = Connection Requested
10b = Reserved
11b = Don’t care/take no action";
CM_ SG_ 2566596350 HVBusHiSideResistorConnectReq "This parameter is used to request connection of the inverter High-Voltage bus high side resistor in order to perform an isolation test. 

00b = Connection not Requested
01b = Connection Requested
10b = Reserved
11b = Don’t care/take no action";
CM_ SG_ 2566596350 HVBusPassiveIsolTestCmd "Command for the inverter to perform a passive electrical isolation test on the high voltage bus.
A passive isolation test uses additional circuitry (e.g. a high impedance network) to monitor the delta between the high voltage connections (e.g ...";
CM_ SG_ 2566596350 HVBusActiveIsolTestCmd "Command for the inverter to perform an active electrical isolation test on the high voltage bus.
An active isolation test might use a generated signal (e.g. an injected AC signal) and then monitor changes in the measurements of the isolated ...";
CM_ BO_ 2566596094 "Motor/Generator 4 Inverter Limits Request DC Side
Sets the DC Side Voltage and Current limits for the inverter being controlled.  Some examples of use would be for a hybrid or electric vehicle propulsion motor or generator.";
CM_ SG_ 2566596094 CurMin "This is a request to the inverter to set a minimum DC Side Current limit for this device instance.
Refer to SPN 11971 [Reference Current] to convert % to Amps.
Request a value of FBFh to instruct the inverter to use its default values.
While ...";
CM_ SG_ 2566596094 CurMax "This is a request to the inverter to set a maximum DC Side Current limit for this device instance.
Refer to SPN 11971 [Reference Current] to convert % to Amps.
Request a value of FBFh to instruct the inverter to use its default values.
While ...";
CM_ SG_ 2566596094 VMin "This is a request to the inverter to set a minimum DC Side Voltage limit for this device instance.
Refer to SPN 11972 [Reference Voltage] to convert % to Volts.
Request a value of FBFh to instruct the inverter to use its default values.
This ...";
CM_ SG_ 2566596094 VMax "This is a request to the inverter to set a maximum DC Side Voltage limit for this device instance.
Refer to SPN 11972 [Reference Voltage] to convert % to Volts.
Request a value of FBFh to instruct the inverter to use its default values.
This ...";
CM_ SG_ 2566596094 Counter "The message counter is used to detect situations where the transmitting ECU malfunction repeats the same frame all the time. The receiver of the information may use the counter parameter to detect this situation. The transmitting device will ...";
CM_ SG_ 2566596094 CRC "The CRC is defined as follows:
• Length: 8 bits
• Polynomial: x^8+x^5+x^3+x^2+x+1
• Initial Value: FFh
• Input Data Reflection: Not reflected
• Result Data Reflection: Not reflected
• XOR value: FFh
SAE makes no claim of the functional safety ...";
CM_ BO_ 2566595838 "Motor/Generator 4 Inverter Limits Request Mechanical
Sets the torque and speed limits for the inverter being controlled. Some examples of use would be for a hybrid or electric vehicle propulsion motor or generator.";
CM_ SG_ 2566595838 SpdMin "This is a request to the inverter to set a minimum speed limit for this device.
Refer to SPN 11940 [Reference Speed] to convert % to rpm.
Request a value of FBFh to instruct the inverter to use its default values.
One use of this message is for ...";
CM_ SG_ 2566595838 SpdMax "This is a request to the inverter to set a maximum speed limit for this device.
Refer to SPN 11940 [Reference Speed] to convert % to rpm.
Request a value of FBFh to instruct the inverter to use its default values.
One use of this message is for ...";
CM_ SG_ 2566595838 TrqMin "This requests a minimum torque the inverter should command for this device.
Refer to SPN 11939 [Reference Torque] to convert % to Nm.
Request a value of FBFh to instruct the inverter to use its default values.
For example, in a typical vehicle ...";
CM_ SG_ 2566595838 TrqMax "This requests a maximum torque the inverter should command for this device.
Refer to SPN 11939 [Reference Torque] to convert % to Nm.
Request a value of FBFh to instruct the inverter to use its default values.
For example, in a typical vehicle ...";
CM_ SG_ 2566595838 Counter "The message counter is used to detect situations where the transmitting ECU malfunction repeats the same frame all the time. The receiver of the information may use the counter parameter to detect this situation. The transmitting device will ...";
CM_ SG_ 2566595838 CRC "The CRC is defined as follows:
• Length: 8 bits
• Polynomial: x^8+x^5+x^3+x^2+x+1
• Initial Value: FFh
• Input Data Reflection: Not reflected
• Result Data Reflection: Not reflected
• XOR value: FFh
SAE makes no claim of the functional safety ...";
CM_ BO_ 2566595582 "Motor/Generator 4 Inverter Limits Request Power
Sets the electrical and mechanical power limits for the inverter being controlled.  Some examples of use would be for a hybrid or electric vehicle propulsion motor or generator.";
CM_ SG_ 2566595582 DCSidePwrMin "This requests a minimum limit for the DC Side power.
Refer to SPN 11941 [Reference Power] to convert % to kW.
Request a value of FBFh to instruct the inverter to use its default values.
For example, in a typical electric vehicle application, the ...";
CM_ SG_ 2566595582 DCSidePwrMax "This requests a maximum limit for the DC Side power.
Refer to SPN 11941 [Reference Power] to convert % to kW.
Request a value of FBFh to instruct the inverter to use its default values.
For example, in a typical electric vehicle application, the ...";
CM_ SG_ 2566595582 MechPwrMin "This requests a minimum limit for the mechanical power.
Refer to SPN 11941 [Reference Power] to convert % to kW.
Request a value of FBFh to instruct the inverter to use its default values.
For example, in a typical electric vehicle application, ...";
CM_ SG_ 2566595582 MechPwrMax "This requests a maximum limit for the mechanical power.
Refer to SPN 11941 [Reference Power] to convert % to kW.
Request a value of FBFh to instruct the inverter to use its default values.
For example, in a typical electric vehicle application, ...";
CM_ SG_ 2566595582 Counter "The message counter is used to detect situations where the transmitting ECU malfunction repeats the same frame all the time. The receiver of the information may use the counter parameter to detect this situation. The transmitting device will ...";
CM_ SG_ 2566595582 CRC "The CRC is defined as follows:
• Length: 8 bits
• Polynomial: x^8+x^5+x^3+x^2+x+1
• Initial Value: FFh
• Input Data Reflection: Not reflected
• Result Data Reflection: Not reflected
• XOR value: FFh
SAE makes no claim of the functional safety ...";
CM_ BO_ 2365268734 "Motor/Generator 4 Inverter Control 2
Secondary control message from this instance of Inverter.  Some examples of use would be for a hybrid or electric vehicle propulsion motor or generator.";
CM_ SG_ 2365268734 PIDCtrlFeedForwardTrq "A PID controller can have a Feed-Forward Torque added to its output. This parameter defines the Feed-Forward Torque Setpoint for control applications in this inverter instance. The Setpoint is in %. Refer to SPN 11939 [Reference Torque] to convert % ...";
CM_ SG_ 2365268734 PIDCtrlNormalizedPropGain "A PID controller can be parametrized by factors Kp, Ki and Kd. This parameter defines the normalized proportional gain (Kpn) for control applications in this inverter instance. The normalization converts absolute physical ranges into normalized ...";
CM_ SG_ 2365268734 PIDCtrlNormalizedIntegralGain "A PID controller can be parametrized by factors Kp, Ki and Kd. This parameter defines the normalized integral gain (Kin) for control applications in this inverter instance. The normalization converts absolute physical ranges into normalized values, ...";
CM_ SG_ 2365268734 PIDCtrlNormalizedDiffGain "A PID controller can be parametrized by factors Kp, Ki and Kd. This parameter defines the normalized integral gain (Kin) for control applications in this inverter instance. The normalization converts absolute physical ranges into normalized values, ...";
CM_ SG_ 2365268734 PIDCtrlApplicableMode "Defines the Mode that the PID Gain parameters apply for this instance of the inverter.  See SPN 11936 [Control Setpoint Mode] for a definition of modes for control purposes.
Applicable modes:
0000b = Speed Control Mode
0001b = DC Side Voltage ...";
CM_ SG_ 2365268734 RateLimitsReq2Counter "The message counter is used to detect situations where the transmitting ECU malfunction repeats the same frame all the time. The receiver of the information may use the counter parameter to detect this situation. The transmitting device will ...";
CM_ SG_ 2365268734 RateLimitsReq2CRC "The CRC is defined as follows:
• Length: 8 bits
• Polynomial: x^8+x^5+x^3+x^2+x+1
• Initial Value: FFh
• Input Data Reflection: Not reflected
• Result Data Reflection: Not reflected
• XOR value: FFh
SAE makes no claim of the functional safety ...";
CM_ BO_ 2566595070 "Motor/Generator 5 Inverter Isolation Integrity Request
Requests the Inverter to perform isolation integrity related tests.";
CM_ SG_ 2566595070 HVBusLowSideResistorConnectReq "This parameter is used to request connection of the inverter High-Voltage bus low side resistor in order to perform an isolation test.  

00b = Connection not Requested
01b = Connection Requested
10b = Reserved
11b = Don’t care/take no action";
CM_ SG_ 2566595070 HVBusHiSideResistorConnectReq "This parameter is used to request connection of the inverter High-Voltage bus high side resistor in order to perform an isolation test. 

00b = Connection not Requested
01b = Connection Requested
10b = Reserved
11b = Don’t care/take no action";
CM_ SG_ 2566595070 HVBusPassiveIsolTestCmd "Command for the inverter to perform a passive electrical isolation test on the high voltage bus.
A passive isolation test uses additional circuitry (e.g. a high impedance network) to monitor the delta between the high voltage connections (e.g ...";
CM_ SG_ 2566595070 HVBusActiveIsolTestCmd "Command for the inverter to perform an active electrical isolation test on the high voltage bus.
An active isolation test might use a generated signal (e.g. an injected AC signal) and then monitor changes in the measurements of the isolated ...";
CM_ BO_ 2566594814 "Motor/Generator 5 Inverter Limits Request DC Side
Sets the DC Side Voltage and Current limits for the inverter being controlled.  Some examples of use would be for a hybrid or electric vehicle propulsion motor or generator.";
CM_ SG_ 2566594814 CurMin "This is a request to the inverter to set a minimum DC Side Current limit for this device instance.
Refer to SPN 12089 [Reference Current] to convert % to Amps.
Request a value of FBFh to instruct the inverter to use its default values.
While ...";
CM_ SG_ 2566594814 CurMax "This is a request to the inverter to set a maximum DC Side Current limit for this device instance.
Refer to SPN 12089 [Reference Current] to convert % to Amps.
Request a value of FBFh to instruct the inverter to use its default values.
While ...";
CM_ SG_ 2566594814 VMin "This is a request to the inverter to set a minimum DC Side Voltage limit for this device instance.
Refer to SPN 12090 [Reference Voltage] to convert % to Volts.
Request a value of FBFh to instruct the inverter to use its default values.
This ...";
CM_ SG_ 2566594814 VMax "This is a request to the inverter to set a maximum DC Side Voltage limit for this device instance.
Refer to SPN 12090 [Reference Voltage] to convert % to Volts.
Request a value of FBFh to instruct the inverter to use its default values.
This ...";
CM_ SG_ 2566594814 Counter "The message counter is used to detect situations where the transmitting ECU malfunction repeats the same frame all the time. The receiver of the information may use the counter parameter to detect this situation. The transmitting device will ...";
CM_ SG_ 2566594814 CRC "The CRC is defined as follows:
• Length: 8 bits
• Polynomial: x^8+x^5+x^3+x^2+x+1
• Initial Value: FFh
• Input Data Reflection: Not reflected
• Result Data Reflection: Not reflected
• XOR value: FFh
SAE makes no claim of the functional safety ...";
CM_ BO_ 2566594558 "Motor/Generator 5 Inverter Limits Request Mechanical
Sets the torque and speed limits for the inverter being controlled. Some examples of use would be for a hybrid or electric vehicle propulsion motor or generator.";
CM_ SG_ 2566594558 SpdMin "This is a request to the inverter to set a minimum speed limit for this device.
Refer to SPN 12058 [Reference Speed] to convert % to rpm.
Request a value of FBFh to instruct the inverter to use its default values.
One use of this message is for ...";
CM_ SG_ 2566594558 SpdMax "This is a request to the inverter to set a maximum speed limit for this device.
Refer to SPN 12058 [Reference Speed] to convert % to rpm.
Request a value of FBFh to instruct the inverter to use its default values.
One use of this message is for ...";
CM_ SG_ 2566594558 TrqMin "This requests a minimum torque the inverter should command for this device.
Refer to SPN 12057 [Reference Torque] to convert % to Nm.
Request a value of FBFh to instruct the inverter to use its default values.
For example, in a typical vehicle ...";
CM_ SG_ 2566594558 TrqMax "This requests a maximum torque the inverter should command for this device.
Refer to SPN 12057 [Reference Torque] to convert % to Nm.
Request a value of FBFh to instruct the inverter to use its default values.
For example, in a typical vehicle ...";
CM_ SG_ 2566594558 Counter "The message counter is used to detect situations where the transmitting ECU malfunction repeats the same frame all the time. The receiver of the information may use the counter parameter to detect this situation. The transmitting device will ...";
CM_ SG_ 2566594558 CRC "The CRC is defined as follows:
• Length: 8 bits
• Polynomial: x^8+x^5+x^3+x^2+x+1
• Initial Value: FFh
• Input Data Reflection: Not reflected
• Result Data Reflection: Not reflected
• XOR value: FFh
SAE makes no claim of the functional safety ...";
CM_ BO_ 2566594302 "Motor/Generator 5 Inverter Limits Request Power
Sets the electrical and mechanical power limits for the inverter being controlled.  Some examples of use would be for a hybrid or electric vehicle propulsion motor or generator.";
CM_ SG_ 2566594302 DCSidePwrMin "This requests a minimum limit for the DC Side power.
Refer to SPN 12059 [Reference Power] to convert % to kW.
Request a value of FBFh to instruct the inverter to use its default values.
For example, in a typical electric vehicle application, the ...";
CM_ SG_ 2566594302 DCSidePwrMax "This requests a maximum limit for the DC Side power.
Refer to SPN 12059 [Reference Power] to convert % to kW.
Request a value of FBFh to instruct the inverter to use its default values.
For example, in a typical electric vehicle application, the ...";
CM_ SG_ 2566594302 MechPwrMin "This requests a minimum limit for the mechanical power.
Refer to SPN 12059 [Reference Power] to convert % to kW.
Request a value of FBFh to instruct the inverter to use its default values.
For example, in a typical electric vehicle application, ...";
CM_ SG_ 2566594302 MechPwrMax "This requests a maximum limit for the mechanical power.
Refer to SPN 12059 [Reference Power] to convert % to kW.
Request a value of FBFh to instruct the inverter to use its default values.
For example, in a typical electric vehicle application, ...";
CM_ SG_ 2566594302 Counter "The message counter is used to detect situations where the transmitting ECU malfunction repeats the same frame all the time. The receiver of the information may use the counter parameter to detect this situation. The transmitting device will ...";
CM_ SG_ 2566594302 CRC "The CRC is defined as follows:
• Length: 8 bits
• Polynomial: x^8+x^5+x^3+x^2+x+1
• Initial Value: FFh
• Input Data Reflection: Not reflected
• Result Data Reflection: Not reflected
• XOR value: FFh
SAE makes no claim of the functional safety ...";
CM_ BO_ 2365267454 "Motor/Generator 5 Inverter Control 2
Secondary control message from this instance of Inverter.  Some examples of use would be for a hybrid or electric vehicle propulsion motor or generator.";
CM_ SG_ 2365267454 PIDCtrlFeedForwardTrq "A PID controller can have a Feed-Forward Torque added to its output. This parameter defines the Feed-Forward Torque Setpoint for control applications in this inverter instance. The Setpoint is in %. Refer to SPN 12057 [Reference Torque] to convert % ...";
CM_ SG_ 2365267454 PIDCtrlNormalizedPropGain "A PID controller can be parametrized by factors Kp, Ki and Kd. This parameter defines the normalized proportional gain (Kpn) for control applications in this inverter instance. The normalization converts absolute physical ranges into normalized ...";
CM_ SG_ 2365267454 PIDCtrlNormalizedIntegralGain "A PID controller can be parametrized by factors Kp, Ki and Kd. This parameter defines the normalized integral gain (Kin) for control applications in this inverter instance. The normalization converts absolute physical ranges into normalized values, ...";
CM_ SG_ 2365267454 PIDCtrlNormalizedDiffGain "A PID controller can be parametrized by factors Kp, Ki and Kd. This parameter defines the normalized integral gain (Kin) for control applications in this inverter instance. The normalization converts absolute physical ranges into normalized values, ...";
CM_ SG_ 2365267454 PIDCtrlApplicableMode "Defines the Mode that the PID Gain parameters apply for this instance of the inverter.  See SPN 12054 [Control Setpoint Mode] for a definition of modes for control purposes.
Applicable modes:
0000b = Speed Control Mode
0001b = DC Side Voltage ...";
CM_ SG_ 2365267454 RateLimitsReq2Counter "The message counter is used to detect situations where the transmitting ECU malfunction repeats the same frame all the time. The receiver of the information may use the counter parameter to detect this situation. The transmitting device will ...";
CM_ SG_ 2365267454 RateLimitsReq2CRC "The CRC is defined as follows:
• Length: 8 bits
• Polynomial: x^8+x^5+x^3+x^2+x+1
• Initial Value: FFh
• Input Data Reflection: Not reflected
• Result Data Reflection: Not reflected
• XOR value: FFh
SAE makes no claim of the functional safety ...";
CM_ BO_ 2566593790 "Motor/Generator 6 Inverter Isolation Integrity Request
Requests the Inverter to perform isolation integrity related tests.";
CM_ SG_ 2566593790 HVBusLowSideResistorConnectReq "This parameter is used to request connection of the inverter High-Voltage bus low side resistor in order to perform an isolation test.  

00b = Connection not Requested
01b = Connection Requested
10b = Reserved
11b = Don’t care/take no action";
CM_ SG_ 2566593790 HVBusHiSideResistorConnectReq "This parameter is used to request connection of the inverter High-Voltage bus high side resistor in order to perform an isolation test. 

00b = Connection not Requested
01b = Connection Requested
10b = Reserved
11b = Don’t care/take no action";
CM_ SG_ 2566593790 HVBusPassiveIsolTestCmd "Command for the inverter to perform a passive electrical isolation test on the high voltage bus.
A passive isolation test uses additional circuitry (e.g. a high impedance network) to monitor the delta between the high voltage connections (e.g ...";
CM_ SG_ 2566593790 HVBusActiveIsolTestCmd "Command for the inverter to perform an active electrical isolation test on the high voltage bus.
An active isolation test might use a generated signal (e.g. an injected AC signal) and then monitor changes in the measurements of the isolated ...";
CM_ BO_ 2566593534 "Motor/Generator 6 Inverter Limits Request DC Side
Sets the DC Side Voltage and Current limits for the inverter being controlled.  Some examples of use would be for a hybrid or electric vehicle propulsion motor or generator.";
CM_ SG_ 2566593534 CurMin "This is a request to the inverter to set a minimum DC Side Current limit for this device instance.
Refer to SPN 12207 [Reference Current] to convert % to Amps.
Request a value of FBFh to instruct the inverter to use its default values.
While ...";
CM_ SG_ 2566593534 CurMax "This is a request to the inverter to set a maximum DC Side Current limit for this device instance.
Refer to SPN 12207 [Reference Current] to convert % to Amps.
Request a value of FBFh to instruct the inverter to use its default values.
While ...";
CM_ SG_ 2566593534 VMin "This is a request to the inverter to set a minimum DC Side Voltage limit for this device instance.
Refer to SPN 12208 [Reference Voltage] to convert % to Volts.
Request a value of FBFh to instruct the inverter to use its default values.
This ...";
CM_ SG_ 2566593534 VMax "This is a request to the inverter to set a maximum DC Side Voltage limit for this device instance.
Refer to SPN 12208 [Reference Voltage] to convert % to Volts.
Request a value of FBFh to instruct the inverter to use its default values.
This ...";
CM_ SG_ 2566593534 Counter "The message counter is used to detect situations where the transmitting ECU malfunction repeats the same frame all the time. The receiver of the information may use the counter parameter to detect this situation. The transmitting device will ...";
CM_ SG_ 2566593534 CRC "The CRC is defined as follows:
• Length: 8 bits
• Polynomial: x^8+x^5+x^3+x^2+x+1
• Initial Value: FFh
• Input Data Reflection: Not reflected
• Result Data Reflection: Not reflected
• XOR value: FFh
SAE makes no claim of the functional safety ...";
CM_ BO_ 2566593278 "Motor/Generator 6 Inverter Limits Request Mechanical
Sets the torque and speed limits for the inverter being controlled. Some examples of use would be for a hybrid or electric vehicle propulsion motor or generator.";
CM_ SG_ 2566593278 SpdMin "This is a request to the inverter to set a minimum speed limit for this device.
Refer to SPN 12176 [Reference Speed] to convert % to rpm.
Request a value of FBFh to instruct the inverter to use its default values.
One use of this message is for ...";
CM_ SG_ 2566593278 SpdMax "This is a request to the inverter to set a maximum speed limit for this device.
Refer to SPN 12176 [Reference Speed] to convert % to rpm.
Request a value of FBFh to instruct the inverter to use its default values.
One use of this message is for ...";
CM_ SG_ 2566593278 TrqMin "This requests a minimum torque the inverter should command for this device.
Refer to SPN 12175 [Reference Torque] to convert % to Nm.
Request a value of FBFh to instruct the inverter to use its default values.
For example, in a typical vehicle ...";
CM_ SG_ 2566593278 TrqMax "This requests a maximum torque the inverter should command for this device.
Refer to SPN 12175 [Reference Torque] to convert % to Nm.
Request a value of FBFh to instruct the inverter to use its default values.
For example, in a typical vehicle ...";
CM_ SG_ 2566593278 Counter "The message counter is used to detect situations where the transmitting ECU malfunction repeats the same frame all the time. The receiver of the information may use the counter parameter to detect this situation. The transmitting device will ...";
CM_ SG_ 2566593278 CRC "The CRC is defined as follows:
• Length: 8 bits
• Polynomial: x^8+x^5+x^3+x^2+x+1
• Initial Value: FFh
• Input Data Reflection: Not reflected
• Result Data Reflection: Not reflected
• XOR value: FFh
SAE makes no claim of the functional safety ...";
CM_ BO_ 2566593022 "Motor/Generator 6 Inverter Limits Request Power
Sets the electrical and mechanical power limits for the inverter being controlled.  Some examples of use would be for a hybrid or electric vehicle propulsion motor or generator.";
CM_ SG_ 2566593022 DCSidePwrMin "This requests a minimum limit for the DC Side power.
Refer to SPN 12177 [Reference Power] to convert % to kW.
Request a value of FBFh to instruct the inverter to use its default values.
For example, in a typical electric vehicle application, the ...";
CM_ SG_ 2566593022 DCSidePwrMax "This requests a maximum limit for the DC Side power.
Refer to SPN 12177 [Reference Power] to convert % to kW.
Request a value of FBFh to instruct the inverter to use its default values.
For example, in a typical electric vehicle application, the ...";
CM_ SG_ 2566593022 MechPwrMin "This requests a minimum limit for the mechanical power.
Refer to SPN 12177 [Reference Power] to convert % to kW.
Request a value of FBFh to instruct the inverter to use its default values.
For example, in a typical electric vehicle application, ...";
CM_ SG_ 2566593022 MechPwrMax "This requests a maximum limit for the mechanical power.
Refer to SPN 12177 [Reference Power] to convert % to kW.
Request a value of FBFh to instruct the inverter to use its default values.
For example, in a typical electric vehicle application, ...";
CM_ SG_ 2566593022 Counter "The message counter is used to detect situations where the transmitting ECU malfunction repeats the same frame all the time. The receiver of the information may use the counter parameter to detect this situation. The transmitting device will ...";
CM_ SG_ 2566593022 CRC "The CRC is defined as follows:
• Length: 8 bits
• Polynomial: x^8+x^5+x^3+x^2+x+1
• Initial Value: FFh
• Input Data Reflection: Not reflected
• Result Data Reflection: Not reflected
• XOR value: FFh
SAE makes no claim of the functional safety ...";
CM_ BO_ 2365266174 "Motor/Generator 6 Inverter Control 2
Secondary control message from this instance of Inverter.  Some examples of use would be for a hybrid or electric vehicle propulsion motor or generator.";
CM_ SG_ 2365266174 PIDCtrlFeedForwardTrq "A PID controller can have a Feed-Forward Torque added to its output. This parameter defines the Feed-Forward Torque Setpoint for control applications in this inverter instance. The Setpoint is in %. Refer to SPN 12175 [Reference Torque] to convert % ...";
CM_ SG_ 2365266174 PIDCtrlNormalizedPropGain "A PID controller can be parametrized by factors Kp, Ki and Kd. This parameter defines the normalized proportional gain (Kpn) for control applications in this inverter instance. The normalization converts absolute physical ranges into normalized ...";
CM_ SG_ 2365266174 PIDCtrlNormalizedIntegralGain "A PID controller can be parametrized by factors Kp, Ki and Kd. This parameter defines the normalized integral gain (Kin) for control applications in this inverter instance. The normalization converts absolute physical ranges into normalized values, ...";
CM_ SG_ 2365266174 PIDCtrlNormalizedDiffGain "A PID controller can be parametrized by factors Kp, Ki and Kd. This parameter defines the normalized integral gain (Kin) for control applications in this inverter instance. The normalization converts absolute physical ranges into normalized values, ...";
CM_ SG_ 2365266174 PIDCtrlApplicableMode "Defines the Mode that the PID Gain parameters apply for this instance of the inverter.  See SPN 12172 [Control Setpoint Mode] for a definition of modes for control purposes.
Applicable modes:
0000b = Speed Control Mode
0001b = DC Side Voltage ...";
CM_ SG_ 2365266174 RateLimitsReq2Counter "The message counter is used to detect situations where the transmitting ECU malfunction repeats the same frame all the time. The receiver of the information may use the counter parameter to detect this situation. The transmitting device will ...";
CM_ SG_ 2365266174 RateLimitsReq2CRC "The CRC is defined as follows:
• Length: 8 bits
• Polynomial: x^8+x^5+x^3+x^2+x+1
• Initial Value: FFh
• Input Data Reflection: Not reflected
• Result Data Reflection: Not reflected
• XOR value: FFh
SAE makes no claim of the functional safety ...";
CM_ BO_ 2566592510 "NOx Tracking Active 100 Hour System Out NOx Mass Bins 
Cumulative System Out (SCR Outlet) NOx mass sorted into bins over the current 100 hour period";
CM_ SG_ 2566592510 Bin17 "Accumulated system out [SCR outlet] NOx mass while all NOx sensors are active over the current 100 hour block for Bin 17 [Note Bin 17 is the MIL On Bin]";
CM_ SG_ 2566592510 Bin16 "Accumulated system out [SCR outlet] NOx mass while all NOx sensors are active over the current 100 hour block for Bin 16 [Note Bin 16 is the Regen Bin]";
CM_ SG_ 2566592510 Bin15 "Accumulated system out [SCR outlet] NOx mass while all NOx sensors are active over the current 100 hour block for Bin 15 [Note Bin 15 is the Regen Bin]";
CM_ SG_ 2566592510 Bin14 "Accumulated system out [SCR outlet] NOx mass while all NOx sensors are active over the current 100 hour block for Bin 14";
CM_ SG_ 2566592510 Bin13 "Accumulated system out [SCR outlet] NOx mass while all NOx sensors are active over the current 100 hour block for Bin 13";
CM_ SG_ 2566592510 Bin12 "Accumulated system out [SCR outlet] NOx mass while all NOx sensors are active over the current 100 hour block for Bin 12";
CM_ SG_ 2566592510 Bin11 "Accumulated system out [SCR outlet] NOx mass while all NOx sensors are active over the current 100 hour block for Bin 11";
CM_ SG_ 2566592510 Bin10 "Accumulated system out [SCR outlet] NOx mass while all NOx sensors are active over the current 100 hour block for Bin 10";
CM_ SG_ 2566592510 Bin9 "Accumulated system out [SCR outlet] NOx mass while all NOx sensors are active over the current 100 hour block for Bin 9";
CM_ SG_ 2566592510 Bin8 "Accumulated system out [SCR outlet] NOx mass while all NOx sensors are active over the current 100 hour block for Bin 8.";
CM_ SG_ 2566592510 Bin7 "Accumulated system out [SCR outlet] NOx mass while all NOx sensors are active over the current 100 hour block for Bin 7.";
CM_ SG_ 2566592510 Bin6 "Accumulated system out [SCR outlet] NOx mass while all NOx sensors are active over the current 100 hour block for Bin 6.";
CM_ SG_ 2566592510 Bin5 "Accumulated system out [SCR outlet] NOx mass while all NOx sensors are active over the current 100 hour block for Bin 5.";
CM_ SG_ 2566592510 Bin4 "Accumulated system out [SCR outlet] NOx mass while all NOx sensors are active over the current 100 hour block for Bin 4.";
CM_ SG_ 2566592510 Bin3 "Accumulated system out [SCR outlet] NOx mass while all NOx sensors are active over the current 100 hour block for Bin 3.";
CM_ SG_ 2566592510 Bin2 "Accumulated system out [SCR outlet] NOx mass while all NOx sensors are active over the current 100 hour block for Bin 2 [Note Bin 2 is the 'idle' bin]";
CM_ SG_ 2566592510 Bin1 "Accumulated system out [SCR outlet] NOx mass while all NOx sensors are active over the current 100 hour block for Bin 1 [Note Bin 1 is the total of Bins 2-14]";
CM_ BO_ 2566592254 "NOx Tracking Active 100 Hour Engine Out NOx Mass Bins 
Cumulative Engine Out NOx mass sorted into bins over the current 100 hour period";
CM_ SG_ 2566592254 Bin17 "Accumulated Engine out NOx mass while all NOx sensors are active over the current 100 hour block for Bin 17 [Note Bin 17 the Mil On Bin]";
CM_ SG_ 2566592254 Bin16 "Accumulated Engine out NOx mass while all NOx sensors are active over the current 100 hour block for Bin 16 [Note Bin 16 is the Regen Bin]";
CM_ SG_ 2566592254 Bin15 "Accumulated Engine out NOx mass while all NOx sensors are active over the current 100 hour block for Bin 15 [Note Bin 15 is the NTE Bin]";
CM_ SG_ 2566592254 Bin14 "Accumulated Engine out NOx mass while all NOx sensors are active over the current 100 hour block for Bin 14";
CM_ SG_ 2566592254 Bin13 "Accumulated Engine out NOx mass while all NOx sensors are active over the current 100 hour block for Bin 13";
CM_ SG_ 2566592254 Bin12 "Accumulated Engine out NOx mass while all NOx sensors are active over the current 100 hour block for Bin 12";
CM_ SG_ 2566592254 Bin11 "Accumulated Engine out NOx mass while all NOx sensors are active over the current 100 hour block for Bin 11";
CM_ SG_ 2566592254 Bin10 "Accumulated Engine out NOx mass while all NOx sensors are active over the current 100 hour block for Bin 10";
CM_ SG_ 2566592254 Bin9 "Accumulated Engine out NOx mass while all NOx sensors are active over the current 100 hour block for Bin 9";
CM_ SG_ 2566592254 Bin8 "Accumulated Engine out NOx mass while all NOx sensors are active over the current 100 hour block for Bin 8.";
CM_ SG_ 2566592254 Bin7 "Accumulated Engine out NOx mass while all NOx sensors are active over the current 100 hour block for Bin 7.";
CM_ SG_ 2566592254 Bin6 "Accumulated Engine out NOx mass while all NOx sensors are active over the current 100 hour block for Bin 6.";
CM_ SG_ 2566592254 Bin5 "Accumulated Engine out NOx mass while all NOx sensors are active over the current 100 hour block for Bin 5.";
CM_ SG_ 2566592254 Bin4 "Accumulated Engine out NOx mass while all NOx sensors are active over the current 100 hour block for Bin 4.";
CM_ SG_ 2566592254 Bin3 "Accumulated Engine out NOx mass while all NOx sensors are active over the current 100 hour block for Bin 3.";
CM_ SG_ 2566592254 Bin2 "Accumulated Engine out NOx mass while all NOx sensors are active over the current 100 hour block for Bin 2 [Note Bin 2 is the 'idle' bin]";
CM_ SG_ 2566592254 Bin1 "Accumulated Engine out NOx mass while all NOx sensors are active over the current 100 hour block for Bin 1 [Note Bin 1 is the total of Bins 2-14]";
CM_ BO_ 2566591998 "NOx Tracking Active 100 Hour Engine Output Energy Bins 
Cumulative Engine Output Energy sorted into bins over the current 100 hour period";
CM_ SG_ 2566591998 Bin17 "Accumulated Engine output energy while all NOx sensors are active over the current 100 hour block for Bin 17 [Note Bin 17 is the MIL On Bin]";
CM_ SG_ 2566591998 Bin16 "Accumulated Engine output energy while all NOx sensors are active over the current 100 hour block for Bin 16 [Note Bin 16 is the Regen Bin]";
CM_ SG_ 2566591998 Bin15 "Accumulated Engine output energy while all NOx sensors are active over the current 100 hour block for Bin 15 [Note Bin 15 is the NTE Bin]";
CM_ SG_ 2566591998 Bin14 "Accumulated Engine output energy while all NOx sensors are active over the current 100 hour block for Bin 14";
CM_ SG_ 2566591998 Bin13 "Accumulated Engine output energy while all NOx sensors are active over the current 100 hour block for Bin 13";
CM_ SG_ 2566591998 Bin12 "Accumulated Engine output energy while all NOx sensors are active over the current 100 hour block for Bin 12";
CM_ SG_ 2566591998 Bin11 "Accumulated Engine output energy while all NOx sensors are active over the current 100 hour block for Bin 11";
CM_ SG_ 2566591998 Bin10 "Accumulated Engine output energy while all NOx sensors are active over the current 100 hour block for Bin 10";
CM_ SG_ 2566591998 Bin9 "Accumulated Engine output energy while all NOx sensors are active over the current 100 hour block for Bin 9";
CM_ SG_ 2566591998 Bin8 "Accumulated Engine output energy while all NOx sensors are active over the current 100 hour block for Bin 8.";
CM_ SG_ 2566591998 Bin7 "Accumulated Engine output energy while all NOx sensors are active over the current 100 hour block for Bin 7.";
CM_ SG_ 2566591998 Bin6 "Accumulated Engine output energy while all NOx sensors are active over the current 100 hour block for Bin 6.";
CM_ SG_ 2566591998 Bin5 "Accumulated Engine output energy while all NOx sensors are active over the current 100 hour block for Bin 5.";
CM_ SG_ 2566591998 Bin4 "Accumulated Engine output energy while all NOx sensors are active over the current 100 hour block for Bin 4.";
CM_ SG_ 2566591998 Bin3 "Accumulated Engine output energy while all NOx sensors are active over the current 100 hour block for Bin 3.";
CM_ SG_ 2566591998 Bin2 "Accumulated Engine output energy while all NOx sensors are active over the current 100 hour block for Bin 2 [Note Bin 2 is the 'idle' bin]";
CM_ SG_ 2566591998 Bin1 "Accumulated Engine output energy while all NOx sensors are active over the current 100 hour block for Bin 1 [Note Bin 1 is the total of Bins 2-14]";
CM_ BO_ 2566591742 "NOx Tracking Active 100 Hour Vehicle Distance Bins 
Cumulative Vehicle Distance sorted into bins over the current 100 hour period";
CM_ SG_ 2566591742 Bin17 "Accumulated Vehicle distance while all NOx sensors are active over the current 100 hour block for Bin 17 [Note Bin 17 is the Mil On Bin]";
CM_ SG_ 2566591742 Bin16 "Accumulated Vehicle distance while all NOx sensors are active over the current 100 hour block for Bin 16 [Note Bin 16 is the Regen Bin]";
CM_ SG_ 2566591742 Bin15 "Accumulated Vehicle distance while all NOx sensors are active over the current 100 hour block for Bin 15 [Note Bin 15 is the NTE Bin]";
CM_ SG_ 2566591742 Bin14 "Accumulated Vehicle distance while all NOx sensors are active over the current 100 hour block for Bin 14";
CM_ SG_ 2566591742 Bin13 "Accumulated Vehicle distance while all NOx sensors are active over the current 100 hour block for Bin 13";
CM_ SG_ 2566591742 Bin12 "Accumulated Vehicle distance while all NOx sensors are active over the current 100 hour block for Bin 12";
CM_ SG_ 2566591742 Bin11 "Accumulated Vehicle distance while all NOx sensors are active over the current 100 hour block for Bin 11";
CM_ SG_ 2566591742 Bin10 "Accumulated Vehicle distance while all NOx sensors are active over the current 100 hour block for Bin 10";
CM_ SG_ 2566591742 Bin9 "Accumulated Vehicle distance while all NOx sensors are active over the current 100 hour block for Bin 9";
CM_ SG_ 2566591742 Bin8 "Accumulated Vehicle distance while all NOx sensors are active over the current 100 hour block for Bin 8.";
CM_ SG_ 2566591742 Bin7 "Accumulated Vehicle distance while all NOx sensors are active over the current 100 hour block for Bin 7.";
CM_ SG_ 2566591742 Bin6 "Accumulated Vehicle distance while all NOx sensors are active over the current 100 hour block for Bin 6.";
CM_ SG_ 2566591742 Bin5 "Accumulated Vehicle distance while all NOx sensors are active over the current 100 hour block for Bin 5.";
CM_ SG_ 2566591742 Bin4 "Accumulated Vehicle distance while all NOx sensors are active over the current 100 hour block for Bin 4.";
CM_ SG_ 2566591742 Bin3 "Accumulated Vehicle distance while all NOx sensors are active over the current 100 hour block for Bin 3.";
CM_ SG_ 2566591742 Bin2 "Accumulated Vehicle distance while all NOx sensors are active over the current 100 hour block for Bin 2 [Note Bin 2 is the 'idle' bin]";
CM_ SG_ 2566591742 Bin1 "Accumulated Vehicle distance while all NOx sensors are active over the current 100 hour block for Bin 1 [Note Bin 1 is the total of Bins 2-14]";
CM_ BO_ 2566591486 "NOx Tracking Active 100 Hour Engine Run Time Bins 
Cumulative Engine Hours sorted into bins over the current 100 hour period";
CM_ SG_ 2566591486 Bin17 "Accumulated Engine run time while all NOx sensors are active over the current 100 hour block for Bin 17 [Note Bin 17 is the MIL On Bin]";
CM_ SG_ 2566591486 Bin16 "Accumulated Engine run time while all NOx sensors are active over the current 100 hour block for Bin 16 [Note Bin 16 is the Regen Bin]";
CM_ SG_ 2566591486 Bin15 "Accumulated Engine run time while all NOx sensors are active over the current 100 hour block for Bin 15 [Note Bin 15 is the NTE Bin]";
CM_ SG_ 2566591486 Bin14 "Accumulated Engine run time while all NOx sensors are active over the current 100 hour block for Bin 14";
CM_ SG_ 2566591486 Bin13 "Accumulated Engine run time while all NOx sensors are active over the current 100 hour block for Bin 13";
CM_ SG_ 2566591486 Bin12 "Accumulated Engine run time while all NOx sensors are active over the current 100 hour block for Bin 12";
CM_ SG_ 2566591486 Bin11 "Accumulated Engine run time while all NOx sensors are active over the current 100 hour block for Bin 11";
CM_ SG_ 2566591486 Bin10 "Accumulated Engine run time while all NOx sensors are active over the current 100 hour block for Bin 10";
CM_ SG_ 2566591486 Bin9 "Accumulated Engine run time while all NOx sensors are active over the current 100 hour block for Bin 9";
CM_ SG_ 2566591486 Bin8 "Accumulated Engine run time while all NOx sensors are active over the current 100 hour block for Bin 8.";
CM_ SG_ 2566591486 Bin7 "Accumulated Engine run time while all NOx sensors are active over the current 100 hour block for Bin 7.";
CM_ SG_ 2566591486 Bin6 "Accumulated Engine run time while all NOx sensors are active over the current 100 hour block for Bin 6.";
CM_ SG_ 2566591486 Bin5 "Accumulated Engine run time while all NOx sensors are active over the current 100 hour block for Bin 5.";
CM_ SG_ 2566591486 Bin4 "Accumulated Engine run time while all NOx sensors are active over the current 100 hour block for Bin 4.";
CM_ SG_ 2566591486 Bin3 "Accumulated Engine run time while all NOx sensors are active over the current 100 hour block for Bin 3.";
CM_ SG_ 2566591486 Bin2 "Accumulated Engine run time while all NOx sensors are active over the current 100 hour block for Bin 2 [Note Bin 2 is the 'idle' bin]";
CM_ SG_ 2566591486 Bin1 "Accumulated Engine run time while all NOx sensors are active over the current 100 hour block for Bin 1 [Note Bin 1 is the total of Bins 2-14]";
CM_ BO_ 2566591230 "NOx Tracking Active 100 Hour Fuel Consumption Bins 
Cumulative Fuel Consumption sorted into bins over the current 100 hour period";
CM_ SG_ 2566591230 Bin17 "Accumulated Fuel consumption while all NOx sensors are active over the current 100 hour block for Bin 17 [Note Bin 17 is the Mil On Bin]";
CM_ SG_ 2566591230 Bin16 "Accumulated Fuel consumption while all NOx sensors are active over the current 100 hour block for Bin 16 [Note Bin 16 is the Regen Bin]";
CM_ SG_ 2566591230 Bin15 "Accumulated Fuel consumption while all NOx sensors are active over the current 100 hour block for Bin 15 [Note Bin 15 is the NTE Bin]";
CM_ SG_ 2566591230 Bin14 "Accumulated Fuel consumption while all NOx sensors are active over the current 100 hour block for Bin 14";
CM_ SG_ 2566591230 Bin13 "Accumulated Fuel consumption while all NOx sensors are active over the current 100 hour block for Bin 13";
CM_ SG_ 2566591230 Bin12 "Accumulated Fuel consumption while all NOx sensors are active over the current 100 hour block for Bin 12";
CM_ SG_ 2566591230 Bin11 "Accumulated Fuel consumption while all NOx sensors are active over the current 100 hour block for Bin 11";
CM_ SG_ 2566591230 Bin10 "Accumulated Fuel consumption while all NOx sensors are active over the current 100 hour block for Bin 10";
CM_ SG_ 2566591230 Bin9 "Accumulated Fuel consumption while all NOx sensors are active over the current 100 hour block for Bin 9";
CM_ SG_ 2566591230 Bin8 "Accumulated Fuel consumption while all NOx sensors are active over the current 100 hour block for Bin 8.";
CM_ SG_ 2566591230 Bin7 "Accumulated Fuel consumption while all NOx sensors are active over the current 100 hour block for Bin 7.";
CM_ SG_ 2566591230 Bin6 "Accumulated Fuel consumption while all NOx sensors are active over the current 100 hour block for Bin 6.";
CM_ SG_ 2566591230 Bin5 "Accumulated Fuel consumption while all NOx sensors are active over the current 100 hour block for Bin 5.";
CM_ SG_ 2566591230 Bin4 "Accumulated Fuel consumption while all NOx sensors are active over the current 100 hour block for Bin 4.";
CM_ SG_ 2566591230 Bin3 "Accumulated Fuel consumption while all NOx sensors are active over the current 100 hour block for Bin 3.";
CM_ SG_ 2566591230 Bin2 "Accumulated Fuel consumption while all NOx sensors are active over the current 100 hour block for Bin 2 [Note Bin 2 is the 'idle' bin]";
CM_ SG_ 2566591230 Bin1 "Accumulated Fuel consumption while all NOx sensors are active over the current 100 hour block for Bin 1 [Note Bin 1 is the total of Bins 2-14]";
CM_ BO_ 2566590974 "NOx Tracking Stored 100 Hour System Out NOx Mass Bins 
Cumulative System Out (SCR Outlet) NOx mass sorted into bins over the prior 100 hour period";
CM_ SG_ 2566590974 Bin17 "Accumulated system out [SCR outlet] NOx mass while all NOx sensors are active over the prior 100 hour period for Bin 17 [Note Bin 17 is the MIL On Bin]";
CM_ SG_ 2566590974 Bin16 "Accumulated system out [SCR outlet] NOx mass while all NOx sensors are active over the prior 100 hour period for Bin 16 [Note Bin 16 is the Regen Bin]";
CM_ SG_ 2566590974 Bin15 "Accumulated system out [SCR outlet] NOx mass while all NOx sensors are active over the prior 100 hour period for Bin 15 [Note Bin 15 is the Regen Bin]";
CM_ SG_ 2566590974 Bin14 "Accumulated system out [SCR outlet] NOx mass while all NOx sensors are active over the prior 100 hour period for Bin 14";
CM_ SG_ 2566590974 Bin13 "Accumulated system out [SCR outlet] NOx mass while all NOx sensors are active over the prior 100 hour period for Bin 13";
CM_ SG_ 2566590974 Bin12 "Accumulated system out [SCR outlet] NOx mass while all NOx sensors are active over the prior 100 hour period for Bin 12";
CM_ SG_ 2566590974 Bin11 "Accumulated system out [SCR outlet] NOx mass while all NOx sensors are active over the prior 100 hour period for Bin 11";
CM_ SG_ 2566590974 Bin10 "Accumulated system out [SCR outlet] NOx mass while all NOx sensors are active over the prior 100 hour period for Bin 10";
CM_ SG_ 2566590974 Bin9 "Accumulated system out [SCR outlet] NOx mass while all NOx sensors are active over the prior 100 hour period for Bin 9";
CM_ SG_ 2566590974 Bin8 "Accumulated system out [SCR outlet] NOx mass while all NOx sensors are active over the prior 100 hour period for Bin 8.";
CM_ SG_ 2566590974 Bin7 "Accumulated system out [SCR outlet] NOx mass while all NOx sensors are active over the prior 100 hour period for Bin 7.";
CM_ SG_ 2566590974 Bin6 "Accumulated system out [SCR outlet] NOx mass while all NOx sensors are active over the prior 100 hour period for Bin 6.";
CM_ SG_ 2566590974 Bin5 "Accumulated system out [SCR outlet] NOx mass while all NOx sensors are active over the prior 100 hour period for Bin 5.";
CM_ SG_ 2566590974 Bin4 "Accumulated system out [SCR outlet] NOx mass while all NOx sensors are active over the prior 100 hour period for Bin 4.";
CM_ SG_ 2566590974 Bin3 "Accumulated system out [SCR outlet] NOx mass while all NOx sensors are active over the prior 100 hour period for Bin 3.";
CM_ SG_ 2566590974 Bin2 "Accumulated system out [SCR outlet] NOx mass while all NOx sensors are active over the prior 100 hour period for Bin 2 [Note Bin 2 is the 'idle' bin]";
CM_ SG_ 2566590974 Bin1 "Accumulated system out [SCR outlet] NOx mass while all NOx sensors are active over the prior 100 hour period for Bin 1 [Note Bin 1 is the total of Bins 2-14]";
CM_ BO_ 2566590718 "NOx Tracking Stored 100 Hour Engine Out NOx Mass Bins 
Cumulative Engine Out NOx mass sorted into bins over the prior 100 hour period";
CM_ SG_ 2566590718 Bin17 "Accumulated Engine out NOx mass while all NOx sensors are active over the prior 100 hour period for Bin 17 [Note Bin 17 is the Mil On Bin]";
CM_ SG_ 2566590718 Bin16 "Accumulated Engine out NOx mass while all NOx sensors are active over the prior 100 hour period for Bin 16 [Note Bin 16 is the Regen Bin]";
CM_ SG_ 2566590718 Bin15 "Accumulated Engine out NOx mass while all NOx sensors are active over the prior 100 hour period for Bin 15 [Note Bin 15 is the NTE Bin]";
CM_ SG_ 2566590718 Bin14 "Accumulated Engine out NOx mass while all NOx sensors are active over the prior 100 hour period for Bin 14";
CM_ SG_ 2566590718 Bin13 "Accumulated Engine out NOx mass while all NOx sensors are active over the prior 100 hour period for Bin 13";
CM_ SG_ 2566590718 Bin12 "Accumulated Engine out NOx mass while all NOx sensors are active over the prior 100 hour period for Bin 12";
CM_ SG_ 2566590718 Bin11 "Accumulated Engine out NOx mass while all NOx sensors are active over the prior 100 hour period for Bin 11";
CM_ SG_ 2566590718 Bin10 "Accumulated Engine out NOx mass while all NOx sensors are active over the prior 100 hour period for Bin 10";
CM_ SG_ 2566590718 Bin9 "Accumulated Engine out NOx mass while all NOx sensors are active over the prior 100 hour period for Bin 9";
CM_ SG_ 2566590718 Bin8 "Accumulated Engine out NOx mass while all NOx sensors are active over the prior 100 hour period for Bin 8.";
CM_ SG_ 2566590718 Bin7 "Accumulated Engine out NOx mass while all NOx sensors are active over the prior 100 hour period for Bin 7.";
CM_ SG_ 2566590718 Bin6 "Accumulated Engine out NOx mass while all NOx sensors are active over the prior 100 hour period for Bin 6.";
CM_ SG_ 2566590718 Bin5 "Accumulated Engine out NOx mass while all NOx sensors are active over the prior 100 hour period for Bin 5.";
CM_ SG_ 2566590718 Bin4 "Accumulated Engine out NOx mass while all NOx sensors are active over the prior 100 hour period for Bin 4.";
CM_ SG_ 2566590718 Bin3 "Accumulated Engine out NOx mass while all NOx sensors are active over the prior 100 hour period for Bin 3.";
CM_ SG_ 2566590718 Bin2 "Accumulated Engine out NOx mass while all NOx sensors are active over the prior 100 hour period for Bin 2 [Note Bin 2 is the 'idle' bin]";
CM_ SG_ 2566590718 Bin1 "Accumulated Engine out NOx mass while all NOx sensors are active over the prior 100 hour period for Bin 1 [Note Bin 1 is the total of Bins 2-14]";
CM_ BO_ 2566590462 "NOx Tracking Stored 100 Hour Engine Output Energy Bins 
Cumulative Engine Output Energy sorted into bins over the prior 100 hour period";
CM_ SG_ 2566590462 Bin17 "Accumulated Engine output energy while all NOx sensors are active over the prior 100 hour period for Bin 17 [Note Bin 17 is the MIL On Bin]";
CM_ SG_ 2566590462 Bin16 "Accumulated Engine output energy while all NOx sensors are active over the prior 100 hour period for Bin 16 [Note Bin 16 is the Regen Bin]";
CM_ SG_ 2566590462 Bin15 "Accumulated Engine output energy while all NOx sensors are active over the prior 100 hour period for Bin 15 [Note Bin 15 is the NTE Bin]";
CM_ SG_ 2566590462 Bin14 "Accumulated Engine output energy while all NOx sensors are active over the prior 100 hour period for Bin 14";
CM_ SG_ 2566590462 Bin13 "Accumulated Engine output energy while all NOx sensors are active over the prior 100 hour period for Bin 13";
CM_ SG_ 2566590462 Bin12 "Accumulated Engine output energy while all NOx sensors are active over the prior 100 hour period for Bin 12";
CM_ SG_ 2566590462 Bin11 "Accumulated Engine output energy while all NOx sensors are active over the prior 100 hour period for Bin 11";
CM_ SG_ 2566590462 Bin10 "Accumulated Engine output energy while all NOx sensors are active over the prior 100 hour period for Bin 10";
CM_ SG_ 2566590462 Bin9 "Accumulated Engine output energy while all NOx sensors are active over the prior 100 hour period for Bin 9";
CM_ SG_ 2566590462 Bin8 "Accumulated Engine output energy while all NOx sensors are active over the prior 100 hour period for Bin 8.";
CM_ SG_ 2566590462 Bin7 "Accumulated Engine output energy while all NOx sensors are active over the prior 100 hour period for Bin 7.";
CM_ SG_ 2566590462 Bin6 "Accumulated Engine output energy while all NOx sensors are active over the prior 100 hour period for Bin 6.";
CM_ SG_ 2566590462 Bin5 "Accumulated Engine output energy while all NOx sensors are active over the prior 100 hour period for Bin 5.";
CM_ SG_ 2566590462 Bin4 "Accumulated Engine output energy while all NOx sensors are active over the prior 100 hour period for Bin 4.";
CM_ SG_ 2566590462 Bin3 "Accumulated Engine output energy while all NOx sensors are active over the prior 100 hour period for Bin 3.";
CM_ SG_ 2566590462 Bin2 "Accumulated Engine output energy while all NOx sensors are active over the prior 100 hour period for Bin 2 [Note Bin 2 is the 'idle' bin]";
CM_ SG_ 2566590462 Bin1 "Accumulated Engine output energy while all NOx sensors are active over the prior 100 hour period for Bin 1 [Note Bin 1 is the total of Bins 2-14]";
CM_ BO_ 2566590206 "NOx Tracking Stored 100 Hour Vehicle Distance Bins 
Cumulative Vehicle Distance sorted into bins over the prior 100 hour period";
CM_ SG_ 2566590206 Bin17 "Accumulated Vehicle distance while all NOx sensors are active over the prior 100 hour period for Bin 17 [Note Bin 17 is the MIL ON Bin]";
CM_ SG_ 2566590206 Bin16 "Accumulated Vehicle distance while all NOx sensors are active over the prior 100 hour period for Bin 16 [Note Bin 16 is the Regen Bin]";
CM_ SG_ 2566590206 Bin15 "Accumulated Vehicle distance while all NOx sensors are active over the prior 100 hour period for Bin 15 [Note Bin 15 is the NTE Bin]";
CM_ SG_ 2566590206 Bin14 "Accumulated Vehicle distance while all NOx sensors are active over the prior 100 hour period for Bin 14";
CM_ SG_ 2566590206 Bin13 "Accumulated Vehicle distance while all NOx sensors are active over the prior 100 hour period for Bin 13";
CM_ SG_ 2566590206 Bin12 "Accumulated Vehicle distance while all NOx sensors are active over the prior 100 hour period for Bin 12";
CM_ SG_ 2566590206 Bin11 "Accumulated Vehicle distance while all NOx sensors are active over the prior 100 hour period for Bin 11";
CM_ SG_ 2566590206 Bin10 "Accumulated Vehicle distance while all NOx sensors are active over the prior 100 hour period for Bin 10";
CM_ SG_ 2566590206 Bin9 "Accumulated Vehicle distance while all NOx sensors are active over the prior 100 hour period for Bin 9";
CM_ SG_ 2566590206 Bin8 "Accumulated Vehicle distance while all NOx sensors are active over the prior 100 hour period for Bin 8.";
CM_ SG_ 2566590206 Bin7 "Accumulated Vehicle distance while all NOx sensors are active over the prior 100 hour period for Bin 7.";
CM_ SG_ 2566590206 Bin6 "Accumulated Vehicle distance while all NOx sensors are active over the prior 100 hour period for Bin 6.";
CM_ SG_ 2566590206 Bin5 "Accumulated Vehicle distance while all NOx sensors are active over the prior 100 hour period for Bin 5.";
CM_ SG_ 2566590206 Bin4 "Accumulated Vehicle distance while all NOx sensors are active over the prior 100 hour period for Bin 4.";
CM_ SG_ 2566590206 Bin3 "Accumulated Vehicle distance while all NOx sensors are active over the prior 100 hour period for Bin 3.";
CM_ SG_ 2566590206 Bin2 "Accumulated Vehicle distance while all NOx sensors are active over the prior 100 hour period for Bin 2 [Note Bin 2 is the 'idle' bin]";
CM_ SG_ 2566590206 Bin1 "Accumulated Vehicle distance while all NOx sensors are active over the prior 100 hour period for Bin 1 [Note Bin 1 is the total of Bins 2-14]";
CM_ BO_ 2566589950 "NOx Tracking Stored 100 Hour Engine Run Time Bins 
Cumulative Engine Hours sorted into bins over the prior 100 hour period";
CM_ SG_ 2566589950 Bin17 "Accumulated Engine run time while all NOx sensors are active over the prior 100 hour period for Bin 17 [Note Bin 17 is the MIL On Bin]";
CM_ SG_ 2566589950 Bin16 "Accumulated Engine run time while all NOx sensors are active over the prior 100 hour period for Bin 16 [Note Bin 16 is the Regen Bin]";
CM_ SG_ 2566589950 Bin15 "Accumulated Engine run time while all NOx sensors are active over the prior 100 hour period for Bin 15 [Note Bin 15 is the NTE Bin]";
CM_ SG_ 2566589950 Bin14 "Accumulated Engine run time while all NOx sensors are active over the prior 100 hour period for Bin 14";
CM_ SG_ 2566589950 Bin13 "Accumulated Engine run time while all NOx sensors are active over the prior 100 hour period for Bin 13";
CM_ SG_ 2566589950 Bin12 "Accumulated Engine run time while all NOx sensors are active over the prior 100 hour period for Bin 12";
CM_ SG_ 2566589950 Bin11 "Accumulated Engine run time while all NOx sensors are active over the prior 100 hour period for Bin 11";
CM_ SG_ 2566589950 Bin10 "Accumulated Engine run time while all NOx sensors are active over the prior 100 hour period for Bin 10";
CM_ SG_ 2566589950 Bin9 "Accumulated Engine run time while all NOx sensors are active over the prior 100 hour period for Bin 9";
CM_ SG_ 2566589950 Bin8 "Accumulated Engine run time while all NOx sensors are active over the prior 100 hour period for Bin 8.";
CM_ SG_ 2566589950 Bin7 "Accumulated Engine run time while all NOx sensors are active over the prior 100 hour period for Bin 7.";
CM_ SG_ 2566589950 Bin6 "Accumulated Engine run time while all NOx sensors are active over the prior 100 hour period for Bin 6.";
CM_ SG_ 2566589950 Bin5 "Accumulated Engine run time while all NOx sensors are active over the prior 100 hour period for Bin 5.";
CM_ SG_ 2566589950 Bin4 "Accumulated Engine run time while all NOx sensors are active over the prior 100 hour period for Bin 4.";
CM_ SG_ 2566589950 Bin3 "Accumulated Engine run time while all NOx sensors are active over the prior 100 hour period for Bin 3.";
CM_ SG_ 2566589950 Bin2 "Accumulated Engine run time while all NOx sensors are active over the prior 100 hour period for Bin 2 [Note Bin 2 is the 'idle' bin]";
CM_ SG_ 2566589950 Bin1 "Accumulated Engine run time while all NOx sensors are active over the prior 100 hour period for Bin 1 [Note Bin 1 is the total of Bins 2-14]";
CM_ BO_ 2566589694 "NOx Tracking Stored 100 Hour Fuel Consumption Bins 
Cumulative Fuel Consumption sorted into bins over the prior 100 hour period";
CM_ SG_ 2566589694 Bin17 "Accumulated Fuel consumption while all NOx sensors are active over the prior 100 hour period for Bin 17 [Note Bin 17 is the MIL On Bin]";
CM_ SG_ 2566589694 Bin16 "Accumulated Fuel consumption while all NOx sensors are active over the prior 100 hour period for Bin 16 [Note Bin 16 is the Regen Bin]";
CM_ SG_ 2566589694 Bin15 "Accumulated Fuel consumption while all NOx sensors are active over the prior 100 hour period for Bin 15 [Note Bin 15 is the NTE Bin]";
CM_ SG_ 2566589694 Bin14 "Accumulated Fuel consumption while all NOx sensors are active over the prior 100 hour period for Bin 14";
CM_ SG_ 2566589694 Bin13 "Accumulated Fuel consumption while all NOx sensors are active over the prior 100 hour period for Bin 13";
CM_ SG_ 2566589694 Bin12 "Accumulated Fuel consumption while all NOx sensors are active over the prior 100 hour period for Bin 12";
CM_ SG_ 2566589694 Bin11 "Accumulated Fuel consumption while all NOx sensors are active over the prior 100 hour period for Bin 11";
CM_ SG_ 2566589694 Bin10 "Accumulated Fuel consumption while all NOx sensors are active over the prior 100 hour period for Bin 10";
CM_ SG_ 2566589694 Bin9 "Accumulated Fuel consumption while all NOx sensors are active over the prior 100 hour period for Bin 9";
CM_ SG_ 2566589694 Bin8 "Accumulated Fuel consumption while all NOx sensors are active over the prior 100 hour period for Bin 8.";
CM_ SG_ 2566589694 Bin7 "Accumulated Fuel consumption while all NOx sensors are active over the prior 100 hour period for Bin 7.";
CM_ SG_ 2566589694 Bin6 "Accumulated Fuel consumption while all NOx sensors are active over the prior 100 hour period for Bin 6.";
CM_ SG_ 2566589694 Bin5 "Accumulated Fuel consumption while all NOx sensors are active over the prior 100 hour period for Bin 5.";
CM_ SG_ 2566589694 Bin4 "Accumulated Fuel consumption while all NOx sensors are active over the prior 100 hour period for Bin 4.";
CM_ SG_ 2566589694 Bin3 "Accumulated Fuel consumption while all NOx sensors are active over the prior 100 hour period for Bin 3.";
CM_ SG_ 2566589694 Bin2 "Accumulated Fuel consumption while all NOx sensors are active over the prior 100 hour period for Bin 2 [Note Bin 2 is the 'idle' bin]";
CM_ SG_ 2566589694 Bin1 "Accumulated Fuel consumption while all NOx sensors are active over the prior 100 hour period for Bin 1 [Note Bin 1 is the total of Bins 2-14]";
CM_ BO_ 2566589438 "NOx Tracking Valid NOx Lifetime System Out NOx Mass Bins 
Cumulative System Out (SCR Outlet) NOx mass sorted into bins over the lifetime of the vehicle while the NOx sensors are Valid";
CM_ SG_ 2566589438 Bin17 "Accumulated system out [SCR outlet] NOx mass while all NOx sensors are active over the lifetime of the vehicle for Bin 17 [Note Bin 17 is the MIL On Bin]";
CM_ SG_ 2566589438 Bin16 "Accumulated system out [SCR outlet] NOx mass while all NOx sensors are active over the lifetime of the vehicle for Bin 16 [Note Bin 16 is the Regen Bin]";
CM_ SG_ 2566589438 Bin15 "Accumulated system out [SCR outlet] NOx mass while all NOx sensors are active over the lifetime of the vehicle for Bin 15 [Note Bin 15 is the Regen Bin]";
CM_ SG_ 2566589438 Bin14 "Accumulated system out [SCR outlet] NOx mass while all NOx sensors are active over the lifetime of the vehicle for Bin 14";
CM_ SG_ 2566589438 Bin13 "Accumulated system out [SCR outlet] NOx mass while all NOx sensors are active over the lifetime of the vehicle for Bin 13";
CM_ SG_ 2566589438 Bin12 "Accumulated system out [SCR outlet] NOx mass while all NOx sensors are active over the lifetime of the vehicle for Bin 12";
CM_ SG_ 2566589438 Bin11 "Accumulated system out [SCR outlet] NOx mass while all NOx sensors are active over the lifetime of the vehicle for Bin 11";
CM_ SG_ 2566589438 Bin10 "Accumulated system out [SCR outlet] NOx mass while all NOx sensors are active over the lifetime of the vehicle for Bin 10";
CM_ SG_ 2566589438 Bin9 "Accumulated system out [SCR outlet] NOx mass while all NOx sensors are active over the lifetime of the vehicle for Bin 9";
CM_ SG_ 2566589438 Bin8 "Accumulated system out [SCR outlet] NOx mass while all NOx sensors are active over the lifetime of the vehicle for Bin 8.";
CM_ SG_ 2566589438 Bin7 "Accumulated system out [SCR outlet] NOx mass while all NOx sensors are active over the lifetime of the vehicle for Bin 7.";
CM_ SG_ 2566589438 Bin6 "Accumulated system out [SCR outlet] NOx mass while all NOx sensors are active over the lifetime of the vehicle for Bin 6.";
CM_ SG_ 2566589438 Bin5 "Accumulated system out [SCR outlet] NOx mass while all NOx sensors are active over the lifetime of the vehicle for Bin 5.";
CM_ SG_ 2566589438 Bin4 "Accumulated system out [SCR outlet] NOx mass while all NOx sensors are active over the lifetime of the vehicle for Bin 4.";
CM_ SG_ 2566589438 Bin3 "Accumulated system out [SCR outlet] NOx mass while all NOx sensors are active over the lifetime of the vehicle for Bin 3.";
CM_ SG_ 2566589438 Bin2 "Accumulated system out [SCR outlet] NOx mass while all NOx sensors are active over the lifetime of the vehicle for Bin 2 [Note Bin 2 is the 'idle' bin]";
CM_ SG_ 2566589438 Bin1 "Accumulated system out [SCR outlet] NOx mass while all NOx sensors are active over the lifetime of the vehicle for Bin 1 [Note Bin 1 is the total of Bins 2-14]";
CM_ BO_ 2566589182 "NOx Tracking Valid NOx Lifetime Engine Out NOx Mass Bins 
Cumulative Engine Out NOx mass sorted into bins over the lifetime of the vehicle while the NOx sensors are Valid";
CM_ SG_ 2566589182 Bin17 "Accumulated Engine out NOx mass while all NOx sensors are active over the lifetime of the vehicle for Bin 17 [Note Bin 17 is the MIL On Bin]";
CM_ SG_ 2566589182 Bin16 "Accumulated Engine out NOx mass while all NOx sensors are active over the lifetime of the vehicle for Bin 16 [Note Bin 16 is the Regen Bin]";
CM_ SG_ 2566589182 Bin15 "Accumulated Engine out NOx mass while all NOx sensors are active over the lifetime of the vehicle for Bin 15 [Note Bin 15 is the NTE Bin]";
CM_ SG_ 2566589182 Bin14 "Accumulated Engine out NOx mass while all NOx sensors are active over the lifetime of the vehicle for Bin 14";
CM_ SG_ 2566589182 Bin13 "Accumulated Engine out NOx mass while all NOx sensors are active over the lifetime of the vehicle for Bin 13";
CM_ SG_ 2566589182 Bin12 "Accumulated Engine out NOx mass while all NOx sensors are active over the lifetime of the vehicle for Bin 12";
CM_ SG_ 2566589182 Bin11 "Accumulated Engine out NOx mass while all NOx sensors are active over the lifetime of the vehicle for Bin 11";
CM_ SG_ 2566589182 Bin10 "Accumulated Engine out NOx mass while all NOx sensors are active over the lifetime of the vehicle for Bin 10";
CM_ SG_ 2566589182 Bin9 "Accumulated Engine out NOx mass while all NOx sensors are active over the lifetime of the vehicle for Bin 9";
CM_ SG_ 2566589182 Bin8 "Accumulated Engine out NOx mass while all NOx sensors are active over the lifetime of the vehicle for Bin 8.";
CM_ SG_ 2566589182 Bin7 "Accumulated Engine out NOx mass while all NOx sensors are active over the lifetime of the vehicle for Bin 7.";
CM_ SG_ 2566589182 Bin6 "Accumulated Engine out NOx mass while all NOx sensors are active over the lifetime of the vehicle for Bin 6.";
CM_ SG_ 2566589182 Bin5 "Accumulated Engine out NOx mass while all NOx sensors are active over the lifetime of the vehicle for Bin 5.";
CM_ SG_ 2566589182 Bin4 "Accumulated Engine out NOx mass while all NOx sensors are active over the lifetime of the vehicle for Bin 4.";
CM_ SG_ 2566589182 Bin3 "Accumulated Engine out NOx mass while all NOx sensors are active over the lifetime of the vehicle for Bin 3.";
CM_ SG_ 2566589182 Bin2 "Accumulated Engine out NOx mass while all NOx sensors are active over the lifetime of the vehicle for Bin 2 [Note Bin 2 is the 'idle' bin]";
CM_ SG_ 2566589182 Bin1 "Accumulated Engine out NOx mass while all NOx sensors are active over the lifetime of the vehicle for Bin 1 [Note Bin 1 is the total of Bins 2-14]";
BA_DEF_ SG_  "GenSigInactiveValue" INT 0 0;
BA_DEF_ SG_  "SigType" ENUM  "Default","Range","RangeSigned","ASCII","Discrete","Control","ReferencePGN","DTC","StringDelimiter","StringLength","StringLengthControl","MessageCounter","MessageChecksum";
BA_DEF_ SG_  "GenSigStartValue" INT 0 2147483647;
BA_DEF_ SG_  "GenSigSendType" ENUM  "Cyclic","OnWrite","OnWriteWithRepetition","OnChange","OnChangeWithRepetition","IfActive","IfActiveWithRepetition","NoSigSendType";
BA_DEF_ SG_  "GenSigILSupport" ENUM  "No","Yes";
BA_DEF_ SG_  "SPN" INT 0 524287;
BA_DEF_ BO_  "J1939CPgSendTimeout" INT -1 3600000;
BA_DEF_ BO_  "J1939CPgTOS" INT 0 7;
BA_DEF_ BO_  "J1939PgAppearanceOnBus" ENUM  "Default","CAN_Extended","CANFD_Extended";
BA_DEF_ BO_  "FsJ1939UseCrcAndCounter" STRING ;
BA_DEF_ BO_  "TpJ1939VarDlc" ENUM  "No","Yes";
BA_DEF_ BO_  "GenMsgNrOfRepetition" INT 0 1000000;
BA_DEF_ BO_  "GenMsgCycleTimeFast" INT 0 3600000;
BA_DEF_ BO_  "GenMsgFastOnStart" INT 0 100000;
BA_DEF_ BO_  "GenMsgStartDelayTime" INT 0 100000;
BA_DEF_ BO_  "GenMsgILSupport" ENUM  "No","Yes";
BA_DEF_ BO_  "GenMsgDelayTime" INT 0 1000;
BA_DEF_ BO_  "GenMsgRequestable" INT 0 1;
BA_DEF_ BO_  "GenMsgSendType" ENUM  "cyclic","NotUsed","NotUsed","NotUsed","NotUsed","NotUsed","NotUsed","IfActive","noMsgSendType";
BA_DEF_ BO_  "VFrameFormat" ENUM  "StandardCAN","ExtendedCAN","reserved","J1939PG","reserved","reserved","reserved","reserved","reserved","reserved","reserved","reserved","reserved","reserved","StandardCAN_FD","ExtendedCAN_FD";
BA_DEF_ BO_  "SingleFrame" INT 0 1;
BA_DEF_ BO_  "GenMsgCycleTime" INT 0 3600000;
BA_DEF_ SG_  "SystemSignalLongSymbol" STRING ;
BA_DEF_DEF_  "GenSigInactiveValue" 0;
BA_DEF_DEF_  "SigType" "Default";
BA_DEF_DEF_  "GenSigStartValue" 0;
BA_DEF_DEF_  "GenSigSendType" "NoSigSendType";
BA_DEF_DEF_  "GenSigILSupport" "Yes";
BA_DEF_DEF_  "SPN" 0;
BA_DEF_DEF_  "J1939CPgSendTimeout" -1;
BA_DEF_DEF_  "J1939CPgTOS" 2;
BA_DEF_DEF_  "J1939PgAppearanceOnBus" "Default";
BA_DEF_DEF_  "FsJ1939UseCrcAndCounter" "";
BA_DEF_DEF_  "TpJ1939VarDlc" "No";
BA_DEF_DEF_  "GenMsgNrOfRepetition" 0;
BA_DEF_DEF_  "GenMsgCycleTimeFast" 0;
BA_DEF_DEF_  "GenMsgFastOnStart" 0;
BA_DEF_DEF_  "GenMsgStartDelayTime" 0;
BA_DEF_DEF_  "GenMsgILSupport" "Yes";
BA_DEF_DEF_  "GenMsgDelayTime" 0;
BA_DEF_DEF_  "GenMsgRequestable" 1;
BA_DEF_DEF_  "GenMsgSendType" "noMsgSendType";
BA_DEF_DEF_  "VFrameFormat" "J1939PG";
BA_DEF_DEF_  "SingleFrame" 1;
BA_DEF_DEF_  "GenMsgCycleTime" 0;
BA_DEF_DEF_  "SystemSignalLongSymbol" "";
BA_ "GenMsgSendType" BO_ 2566603006 0;
BA_ "GenMsgCycleTime" BO_ 2566603006 1000;
BA_ "FsJ1939UseCrcAndCounter" BO_ 2365276158 "Bc";
BA_ "GenMsgSendType" BO_ 2365276158 0;
BA_ "GenMsgCycleTime" BO_ 2365276158 1000;
BA_ "FsJ1939UseCrcAndCounter" BO_ 2365275902 "Bc";
BA_ "GenMsgSendType" BO_ 2365275902 0;
BA_ "GenMsgCycleTime" BO_ 2365275902 10;
BA_ "FsJ1939UseCrcAndCounter" BO_ 2365275646 "Bc";
BA_ "GenMsgSendType" BO_ 2365275646 0;
BA_ "GenMsgCycleTime" BO_ 2365275646 1000;
BA_ "GenMsgDelayTime" BO_ 2566601982 100;
BA_ "GenMsgSendType" BO_ 2566601982 0;
BA_ "GenMsgCycleTime" BO_ 2566601982 1000;
BA_ "FsJ1939UseCrcAndCounter" BO_ 2566601726 "Bc";
BA_ "GenMsgSendType" BO_ 2566601726 0;
BA_ "GenMsgCycleTime" BO_ 2566601726 250;
BA_ "GenMsgSendType" BO_ 2566601470 0;
BA_ "GenMsgCycleTime" BO_ 2566601470 1000;
BA_ "GenMsgSendType" BO_ 2566601214 0;
BA_ "GenMsgCycleTime" BO_ 2566601214 1000;
BA_ "FsJ1939UseCrcAndCounter" BO_ 2365274366 "Bc";
BA_ "GenMsgSendType" BO_ 2365274366 0;
BA_ "GenMsgCycleTime" BO_ 2365274366 1000;
BA_ "FsJ1939UseCrcAndCounter" BO_ 2365274110 "Bc";
BA_ "GenMsgSendType" BO_ 2365274110 0;
BA_ "GenMsgCycleTime" BO_ 2365274110 10;
BA_ "FsJ1939UseCrcAndCounter" BO_ 2365273854 "Bc";
BA_ "GenMsgSendType" BO_ 2365273854 0;
BA_ "GenMsgCycleTime" BO_ 2365273854 1000;
BA_ "GenMsgDelayTime" BO_ 2566600190 100;
BA_ "GenMsgSendType" BO_ 2566600190 0;
BA_ "GenMsgCycleTime" BO_ 2566600190 1000;
BA_ "FsJ1939UseCrcAndCounter" BO_ 2566599934 "Bc";
BA_ "GenMsgSendType" BO_ 2566599934 0;
BA_ "GenMsgCycleTime" BO_ 2566599934 250;
BA_ "GenMsgSendType" BO_ 2566599678 0;
BA_ "GenMsgCycleTime" BO_ 2566599678 1000;
BA_ "GenMsgSendType" BO_ 2566599422 0;
BA_ "GenMsgCycleTime" BO_ 2566599422 1000;
BA_ "FsJ1939UseCrcAndCounter" BO_ 2365272574 "Bc";
BA_ "GenMsgSendType" BO_ 2365272574 0;
BA_ "GenMsgCycleTime" BO_ 2365272574 1000;
BA_ "FsJ1939UseCrcAndCounter" BO_ 2365272318 "Bc";
BA_ "GenMsgSendType" BO_ 2365272318 0;
BA_ "GenMsgCycleTime" BO_ 2365272318 10;
BA_ "FsJ1939UseCrcAndCounter" BO_ 2365272062 "Bc";
BA_ "GenMsgSendType" BO_ 2365272062 0;
BA_ "GenMsgCycleTime" BO_ 2365272062 1000;
BA_ "GenMsgSendType" BO_ 2566598142 0;
BA_ "GenMsgCycleTime" BO_ 2566598142 1000;
BA_ "FsJ1939UseCrcAndCounter" BO_ 2566597374 "Bc";
BA_ "GenMsgSendType" BO_ 2566597374 0;
BA_ "GenMsgCycleTime" BO_ 2566597374 1000;
BA_ "FsJ1939UseCrcAndCounter" BO_ 2566597118 "Bc";
BA_ "GenMsgSendType" BO_ 2566597118 0;
BA_ "GenMsgCycleTime" BO_ 2566597118 1000;
BA_ "FsJ1939UseCrcAndCounter" BO_ 2566596862 "Bc";
BA_ "GenMsgSendType" BO_ 2566596862 0;
BA_ "GenMsgCycleTime" BO_ 2566596862 1000;
BA_ "FsJ1939UseCrcAndCounter" BO_ 2365270014 "Bc";
BA_ "GenMsgSendType" BO_ 2365270014 0;
BA_ "GenMsgCycleTime" BO_ 2365270014 100;
BA_ "FsJ1939UseCrcAndCounter" BO_ 2566596094 "Bc";
BA_ "GenMsgSendType" BO_ 2566596094 0;
BA_ "GenMsgCycleTime" BO_ 2566596094 1000;
BA_ "FsJ1939UseCrcAndCounter" BO_ 2566595838 "Bc";
BA_ "GenMsgSendType" BO_ 2566595838 0;
BA_ "GenMsgCycleTime" BO_ 2566595838 1000;
BA_ "FsJ1939UseCrcAndCounter" BO_ 2566595582 "Bc";
BA_ "GenMsgSendType" BO_ 2566595582 0;
BA_ "GenMsgCycleTime" BO_ 2566595582 1000;
BA_ "FsJ1939UseCrcAndCounter" BO_ 2365268734 "Bc";
BA_ "GenMsgSendType" BO_ 2365268734 0;
BA_ "GenMsgCycleTime" BO_ 2365268734 100;
BA_ "FsJ1939UseCrcAndCounter" BO_ 2566594814 "Bc";
BA_ "GenMsgSendType" BO_ 2566594814 0;
BA_ "GenMsgCycleTime" BO_ 2566594814 1000;
BA_ "FsJ1939UseCrcAndCounter" BO_ 2566594558 "Bc";
BA_ "GenMsgSendType" BO_ 2566594558 0;
BA_ "GenMsgCycleTime" BO_ 2566594558 1000;
BA_ "FsJ1939UseCrcAndCounter" BO_ 2566594302 "Bc";
BA_ "GenMsgSendType" BO_ 2566594302 0;
BA_ "GenMsgCycleTime" BO_ 2566594302 1000;
BA_ "FsJ1939UseCrcAndCounter" BO_ 2365267454 "Bc";
BA_ "GenMsgSendType" BO_ 2365267454 0;
BA_ "GenMsgCycleTime" BO_ 2365267454 100;
BA_ "FsJ1939UseCrcAndCounter" BO_ 2566593534 "Bc";
BA_ "GenMsgSendType" BO_ 2566593534 0;
BA_ "GenMsgCycleTime" BO_ 2566593534 1000;
BA_ "FsJ1939UseCrcAndCounter" BO_ 2566593278 "Bc";
BA_ "GenMsgSendType" BO_ 2566593278 0;
BA_ "GenMsgCycleTime" BO_ 2566593278 1000;
BA_ "FsJ1939UseCrcAndCounter" BO_ 2566593022 "Bc";
BA_ "GenMsgSendType" BO_ 2566593022 0;
BA_ "GenMsgCycleTime" BO_ 2566593022 1000;
BA_ "FsJ1939UseCrcAndCounter" BO_ 2365266174 "Bc";
BA_ "GenMsgSendType" BO_ 2365266174 0;
BA_ "GenMsgCycleTime" BO_ 2365266174 100;
BA_ "SigType" SG_ 2566603006 Five 1;
BA_ "SPN" SG_ 2566603006 Five 20917;
BA_ "SigType" SG_ 2566603006 Four 1;
BA_ "SPN" SG_ 2566603006 Four 11988;
BA_ "SigType" SG_ 2566603006 Three 1;
BA_ "SPN" SG_ 2566603006 Three 11987;
BA_ "SigType" SG_ 2566603006 Two 1;
BA_ "SPN" SG_ 2566603006 Two 11986;
BA_ "SigType" SG_ 2566603006 One 1;
BA_ "SPN" SG_ 2566603006 One 11985;
BA_ "SigType" SG_ 2365276158 V 1;
BA_ "SPN" SG_ 2365276158 V 11972;
BA_ "SigType" SG_ 2365276158 Cur 1;
BA_ "SPN" SG_ 2365276158 Cur 11971;
BA_ "SigType" SG_ 2365276158 Counter 11;
BA_ "SPN" SG_ 2365276158 Counter 11970;
BA_ "SigType" SG_ 2365276158 CRC 12;
BA_ "SPN" SG_ 2365276158 CRC 11969;
BA_ "SPN" SG_ 2365275902 DCSideV 11922;
BA_ "SPN" SG_ 2365275902 DCSideCur 11944;
BA_ "SigType" SG_ 2365275902 Spd 1;
BA_ "SPN" SG_ 2365275902 Spd 11919;
BA_ "SPN" SG_ 2365275902 Trq 11921;
BA_ "SigType" SG_ 2365275902 Counter 11;
BA_ "SPN" SG_ 2365275902 Counter 11943;
BA_ "SigType" SG_ 2365275902 CRC 12;
BA_ "SPN" SG_ 2365275902 CRC 11942;
BA_ "SigType" SG_ 2365275646 Pwr 1;
BA_ "SPN" SG_ 2365275646 Pwr 11941;
BA_ "SigType" SG_ 2365275646 Spd 1;
BA_ "SPN" SG_ 2365275646 Spd 11940;
BA_ "SigType" SG_ 2365275646 Trq 1;
BA_ "SPN" SG_ 2365275646 Trq 11939;
BA_ "SigType" SG_ 2365275646 Counter 11;
BA_ "SPN" SG_ 2365275646 Counter 11938;
BA_ "SigType" SG_ 2365275646 CRC 12;
BA_ "SPN" SG_ 2365275646 CRC 11937;
BA_ "SigType" SG_ 2566601982 TrqLimDueToMachineCharacter_0003 4;
BA_ "SPN" SG_ 2566601982 TrqLimDueToMachineCharacter_0003 13060;
BA_ "SystemSignalLongSymbol" SG_ 2566601982 TrqLimDueToMachineCharacter_0003 "TrqLimDueToMachineCharacteristics";
BA_ "SigType" SG_ 2566601982 PLedDueToActiveSpdRateLmt 4;
BA_ "SPN" SG_ 2566601982 PLedDueToActiveSpdRateLmt 13059;
BA_ "SigType" SG_ 2566601982 PLedDueToActiveTrqRateLmt 4;
BA_ "SPN" SG_ 2566601982 PLedDueToActiveTrqRateLmt 13058;
BA_ "SigType" SG_ 2566601982 PLedDueToFaultCondition 4;
BA_ "SPN" SG_ 2566601982 PLedDueToFaultCondition 13057;
BA_ "SigType" SG_ 2566601982 PLedDueToMotorTemp 4;
BA_ "SPN" SG_ 2566601982 PLedDueToMotorTemp 12139;
BA_ "SigType" SG_ 2566601982 PLedDueToInvTemp 4;
BA_ "SPN" SG_ 2566601982 PLedDueToInvTemp 12138;
BA_ "SigType" SG_ 2566601982 PLedDueToSpdMin 4;
BA_ "SPN" SG_ 2566601982 PLedDueToSpdMin 12137;
BA_ "SigType" SG_ 2566601982 PLedDueToSpdMax 4;
BA_ "SPN" SG_ 2566601982 PLedDueToSpdMax 12136;
BA_ "SigType" SG_ 2566601982 PLedDueToTrqMin 4;
BA_ "SPN" SG_ 2566601982 PLedDueToTrqMin 12135;
BA_ "SigType" SG_ 2566601982 PLedDueToTrqMax 4;
BA_ "SPN" SG_ 2566601982 PLedDueToTrqMax 12134;
BA_ "SigType" SG_ 2566601982 PLedDueToDCSidePwrMin 4;
BA_ "SPN" SG_ 2566601982 PLedDueToDCSidePwrMin 12133;
BA_ "SigType" SG_ 2566601982 PLedDueToDCSidePwrMax 4;
BA_ "SPN" SG_ 2566601982 PLedDueToDCSidePwrMax 12132;
BA_ "SigType" SG_ 2566601982 PLedDueToMechPwrMin 4;
BA_ "SPN" SG_ 2566601982 PLedDueToMechPwrMin 12131;
BA_ "SigType" SG_ 2566601982 PLedDueToMechPwrMax 4;
BA_ "SPN" SG_ 2566601982 PLedDueToMechPwrMax 12130;
BA_ "SigType" SG_ 2566601982 PLedDueToDCSideVMin 4;
BA_ "SPN" SG_ 2566601982 PLedDueToDCSideVMin 12129;
BA_ "SigType" SG_ 2566601982 PLedDueToDCSideVMax 4;
BA_ "SPN" SG_ 2566601982 PLedDueToDCSideVMax 12128;
BA_ "SigType" SG_ 2566601982 PLedDueToDCSideCurMin 4;
BA_ "SPN" SG_ 2566601982 PLedDueToDCSideCurMin 12127;
BA_ "SigType" SG_ 2566601982 PLedDueToDCSideCurMax 4;
BA_ "SPN" SG_ 2566601982 PLedDueToDCSideCurMax 12126;
BA_ "SigType" SG_ 2566601982 PLedDueToUndefinedReason 4;
BA_ "SPN" SG_ 2566601982 PLedDueToUndefinedReason 12125;
BA_ "SigType" SG_ 2566601726 HVBusPassiveIsolTestResults 1;
BA_ "SPN" SG_ 2566601726 HVBusPassiveIsolTestResults 12124;
BA_ "SigType" SG_ 2566601726 HVBusActiveIsolTestResults 1;
BA_ "SPN" SG_ 2566601726 HVBusActiveIsolTestResults 12123;
BA_ "SPN" SG_ 2566601726 HVBusPassiveIsolTestStatus 12122;
BA_ "SPN" SG_ 2566601726 HVBusActiveIsolTestStatus 12121;
BA_ "SPN" SG_ 2566601726 DCSideNegToChassisGroundV 12120;
BA_ "SigType" SG_ 2566601726 Counter 11;
BA_ "SPN" SG_ 2566601726 Counter 12119;
BA_ "SigType" SG_ 2566601726 CRC 12;
BA_ "SPN" SG_ 2566601726 CRC 12118;
BA_ "SigType" SG_ 2566601470 Temp4 1;
BA_ "SPN" SG_ 2566601470 Temp4 12109;
BA_ "SigType" SG_ 2566601470 Temp3 1;
BA_ "SPN" SG_ 2566601470 Temp3 12108;
BA_ "SigType" SG_ 2566601470 Temp2 1;
BA_ "SPN" SG_ 2566601470 Temp2 12107;
BA_ "SigType" SG_ 2566601470 Temp1 1;
BA_ "SPN" SG_ 2566601470 Temp1 12038;
BA_ "SigType" SG_ 2566601214 Five 1;
BA_ "SPN" SG_ 2566601214 Five 20918;
BA_ "SigType" SG_ 2566601214 Four 1;
BA_ "SPN" SG_ 2566601214 Four 12106;
BA_ "SigType" SG_ 2566601214 Three 1;
BA_ "SPN" SG_ 2566601214 Three 12105;
BA_ "SigType" SG_ 2566601214 Two 1;
BA_ "SPN" SG_ 2566601214 Two 12104;
BA_ "SigType" SG_ 2566601214 One 1;
BA_ "SPN" SG_ 2566601214 One 12103;
BA_ "SigType" SG_ 2365274366 V 1;
BA_ "SPN" SG_ 2365274366 V 12090;
BA_ "SigType" SG_ 2365274366 Cur 1;
BA_ "SPN" SG_ 2365274366 Cur 12089;
BA_ "SigType" SG_ 2365274366 Counter 11;
BA_ "SPN" SG_ 2365274366 Counter 12088;
BA_ "SigType" SG_ 2365274366 CRC 12;
BA_ "SPN" SG_ 2365274366 CRC 12087;
BA_ "SPN" SG_ 2365274110 DCSideV 12040;
BA_ "SPN" SG_ 2365274110 DCSideCur 12062;
BA_ "SigType" SG_ 2365274110 Spd 1;
BA_ "SPN" SG_ 2365274110 Spd 12037;
BA_ "SPN" SG_ 2365274110 Trq 12039;
BA_ "SigType" SG_ 2365274110 Counter 11;
BA_ "SPN" SG_ 2365274110 Counter 12061;
BA_ "SigType" SG_ 2365274110 CRC 12;
BA_ "SPN" SG_ 2365274110 CRC 12060;
BA_ "SigType" SG_ 2365273854 Pwr 1;
BA_ "SPN" SG_ 2365273854 Pwr 12059;
BA_ "SigType" SG_ 2365273854 Spd 1;
BA_ "SPN" SG_ 2365273854 Spd 12058;
BA_ "SigType" SG_ 2365273854 Trq 1;
BA_ "SPN" SG_ 2365273854 Trq 12057;
BA_ "SigType" SG_ 2365273854 Counter 11;
BA_ "SPN" SG_ 2365273854 Counter 12056;
BA_ "SigType" SG_ 2365273854 CRC 12;
BA_ "SPN" SG_ 2365273854 CRC 12055;
BA_ "SigType" SG_ 2566600190 TrqLimDueToMachineCharacter_0004 4;
BA_ "SPN" SG_ 2566600190 TrqLimDueToMachineCharacter_0004 13064;
BA_ "SystemSignalLongSymbol" SG_ 2566600190 TrqLimDueToMachineCharacter_0004 "TrqLimDueToMachineCharacteristics";
BA_ "SigType" SG_ 2566600190 PLedDueToActiveSpdRateLmt 4;
BA_ "SPN" SG_ 2566600190 PLedDueToActiveSpdRateLmt 13063;
BA_ "SigType" SG_ 2566600190 PLedDueToActiveTrqRateLmt 4;
BA_ "SPN" SG_ 2566600190 PLedDueToActiveTrqRateLmt 13062;
BA_ "SigType" SG_ 2566600190 PLedDueToFaultCondition 4;
BA_ "SPN" SG_ 2566600190 PLedDueToFaultCondition 13061;
BA_ "SigType" SG_ 2566600190 PLedDueToMotorTemp 4;
BA_ "SPN" SG_ 2566600190 PLedDueToMotorTemp 12257;
BA_ "SigType" SG_ 2566600190 PLedDueToInvTemp 4;
BA_ "SPN" SG_ 2566600190 PLedDueToInvTemp 12256;
BA_ "SigType" SG_ 2566600190 PLedDueToSpdMin 4;
BA_ "SPN" SG_ 2566600190 PLedDueToSpdMin 12255;
BA_ "SigType" SG_ 2566600190 PLedDueToSpdMax 4;
BA_ "SPN" SG_ 2566600190 PLedDueToSpdMax 12254;
BA_ "SigType" SG_ 2566600190 PLedDueToTrqMin 4;
BA_ "SPN" SG_ 2566600190 PLedDueToTrqMin 12253;
BA_ "SigType" SG_ 2566600190 PLedDueToTrqMax 4;
BA_ "SPN" SG_ 2566600190 PLedDueToTrqMax 12252;
BA_ "SigType" SG_ 2566600190 PLedDueToDCSidePwrMin 4;
BA_ "SPN" SG_ 2566600190 PLedDueToDCSidePwrMin 12251;
BA_ "SigType" SG_ 2566600190 PLedDueToDCSidePwrMax 4;
BA_ "SPN" SG_ 2566600190 PLedDueToDCSidePwrMax 12250;
BA_ "SigType" SG_ 2566600190 PLedDueToMechPwrMin 4;
BA_ "SPN" SG_ 2566600190 PLedDueToMechPwrMin 12249;
BA_ "SigType" SG_ 2566600190 PLedDueToMechPwrMax 4;
BA_ "SPN" SG_ 2566600190 PLedDueToMechPwrMax 12248;
BA_ "SigType" SG_ 2566600190 PLedDueToDCSideVMin 4;
BA_ "SPN" SG_ 2566600190 PLedDueToDCSideVMin 12247;
BA_ "SigType" SG_ 2566600190 PLedDueToDCSideVMax 4;
BA_ "SPN" SG_ 2566600190 PLedDueToDCSideVMax 12246;
BA_ "SigType" SG_ 2566600190 PLedDueToDCSideCurMin 4;
BA_ "SPN" SG_ 2566600190 PLedDueToDCSideCurMin 12245;
BA_ "SigType" SG_ 2566600190 PLedDueToDCSideCurMax 4;
BA_ "SPN" SG_ 2566600190 PLedDueToDCSideCurMax 12244;
BA_ "SigType" SG_ 2566600190 PLedDueToUndefinedReason 4;
BA_ "SPN" SG_ 2566600190 PLedDueToUndefinedReason 12243;
BA_ "SigType" SG_ 2566599934 HVBusPassiveIsolTestResults 1;
BA_ "SPN" SG_ 2566599934 HVBusPassiveIsolTestResults 12242;
BA_ "SigType" SG_ 2566599934 HVBusActiveIsolTestResults 1;
BA_ "SPN" SG_ 2566599934 HVBusActiveIsolTestResults 12241;
BA_ "SPN" SG_ 2566599934 HVBusPassiveIsolTestStatus 12240;
BA_ "SPN" SG_ 2566599934 HVBusActiveIsolTestStatus 12239;
BA_ "SPN" SG_ 2566599934 DCSideNegToChassisGroundV 12238;
BA_ "SigType" SG_ 2566599934 Counter 11;
BA_ "SPN" SG_ 2566599934 Counter 12237;
BA_ "SigType" SG_ 2566599934 CRC 12;
BA_ "SPN" SG_ 2566599934 CRC 12236;
BA_ "SigType" SG_ 2566599678 Temp4 1;
BA_ "SPN" SG_ 2566599678 Temp4 12227;
BA_ "SigType" SG_ 2566599678 Temp3 1;
BA_ "SPN" SG_ 2566599678 Temp3 12226;
BA_ "SigType" SG_ 2566599678 Temp2 1;
BA_ "SPN" SG_ 2566599678 Temp2 12225;
BA_ "SigType" SG_ 2566599678 Temp1 1;
BA_ "SPN" SG_ 2566599678 Temp1 12156;
BA_ "SigType" SG_ 2566599422 Five 1;
BA_ "SPN" SG_ 2566599422 Five 20919;
BA_ "SigType" SG_ 2566599422 Four 1;
BA_ "SPN" SG_ 2566599422 Four 12224;
BA_ "SigType" SG_ 2566599422 Three 1;
BA_ "SPN" SG_ 2566599422 Three 12223;
BA_ "SigType" SG_ 2566599422 Two 1;
BA_ "SPN" SG_ 2566599422 Two 12222;
BA_ "SigType" SG_ 2566599422 One 1;
BA_ "SPN" SG_ 2566599422 One 12221;
BA_ "SigType" SG_ 2365272574 V 1;
BA_ "SPN" SG_ 2365272574 V 12208;
BA_ "SigType" SG_ 2365272574 Cur 1;
BA_ "SPN" SG_ 2365272574 Cur 12207;
BA_ "SigType" SG_ 2365272574 Counter 11;
BA_ "SPN" SG_ 2365272574 Counter 12206;
BA_ "SigType" SG_ 2365272574 CRC 12;
BA_ "SPN" SG_ 2365272574 CRC 12205;
BA_ "SPN" SG_ 2365272318 DCSideV 12158;
BA_ "SPN" SG_ 2365272318 DCSideCur 12180;
BA_ "SigType" SG_ 2365272318 Spd 1;
BA_ "SPN" SG_ 2365272318 Spd 12155;
BA_ "SPN" SG_ 2365272318 Trq 12157;
BA_ "SigType" SG_ 2365272318 Counter 11;
BA_ "SPN" SG_ 2365272318 Counter 12179;
BA_ "SigType" SG_ 2365272318 CRC 12;
BA_ "SPN" SG_ 2365272318 CRC 12178;
BA_ "SigType" SG_ 2365272062 Pwr 1;
BA_ "SPN" SG_ 2365272062 Pwr 12177;
BA_ "SigType" SG_ 2365272062 Spd 1;
BA_ "SPN" SG_ 2365272062 Spd 12176;
BA_ "SigType" SG_ 2365272062 Trq 1;
BA_ "SPN" SG_ 2365272062 Trq 12175;
BA_ "SigType" SG_ 2365272062 Counter 11;
BA_ "SPN" SG_ 2365272062 Counter 12174;
BA_ "SigType" SG_ 2365272062 CRC 12;
BA_ "SPN" SG_ 2365272062 CRC 12173;
BA_ "SigType" SG_ 2566598398 RevolutionCounter 1;
BA_ "SPN" SG_ 2566598398 RevolutionCounter 12311;
BA_ "SigType" SG_ 2566598142 EngTC6CompressorInPress 1;
BA_ "SPN" SG_ 2566598142 EngTC6CompressorInPress 12316;
BA_ "SigType" SG_ 2566598142 EngTC5CompressorInPress 1;
BA_ "SPN" SG_ 2566598142 EngTC5CompressorInPress 12315;
BA_ "SigType" SG_ 2566598142 EngTC6Spd 1;
BA_ "SPN" SG_ 2566598142 EngTC6Spd 12314;
BA_ "SigType" SG_ 2566598142 EngTC5Spd 1;
BA_ "SPN" SG_ 2566598142 EngTC5Spd 12313;
BA_ "SigType" SG_ 2566597630 HVBusLowSideResistorConnectReq 5;
BA_ "SPN" SG_ 2566597630 HVBusLowSideResistorConnectReq 11881;
BA_ "SigType" SG_ 2566597630 HVBusHiSideResistorConnectReq 5;
BA_ "SPN" SG_ 2566597630 HVBusHiSideResistorConnectReq 11880;
BA_ "SigType" SG_ 2566597630 HVBusPassiveIsolTestCmd 5;
BA_ "SPN" SG_ 2566597630 HVBusPassiveIsolTestCmd 11879;
BA_ "SigType" SG_ 2566597630 HVBusActiveIsolTestCmd 5;
BA_ "SPN" SG_ 2566597630 HVBusActiveIsolTestCmd 11878;
BA_ "SPN" SG_ 2566597374 CurMin 11860;
BA_ "SPN" SG_ 2566597374 CurMax 11859;
BA_ "SPN" SG_ 2566597374 VMin 11858;
BA_ "SPN" SG_ 2566597374 VMax 11857;
BA_ "SigType" SG_ 2566597374 Counter 11;
BA_ "SPN" SG_ 2566597374 Counter 11856;
BA_ "SigType" SG_ 2566597374 CRC 12;
BA_ "SPN" SG_ 2566597374 CRC 11855;
BA_ "SPN" SG_ 2566597118 SpdMin 11844;
BA_ "SPN" SG_ 2566597118 SpdMax 11843;
BA_ "SPN" SG_ 2566597118 TrqMin 11842;
BA_ "SPN" SG_ 2566597118 TrqMax 11841;
BA_ "SigType" SG_ 2566597118 Counter 11;
BA_ "SPN" SG_ 2566597118 Counter 11840;
BA_ "SigType" SG_ 2566597118 CRC 12;
BA_ "SPN" SG_ 2566597118 CRC 11839;
BA_ "SPN" SG_ 2566596862 DCSidePwrMin 11832;
BA_ "SPN" SG_ 2566596862 DCSidePwrMax 11831;
BA_ "SPN" SG_ 2566596862 MechPwrMin 11830;
BA_ "SPN" SG_ 2566596862 MechPwrMax 11829;
BA_ "SigType" SG_ 2566596862 Counter 11;
BA_ "SPN" SG_ 2566596862 Counter 11828;
BA_ "SigType" SG_ 2566596862 CRC 12;
BA_ "SPN" SG_ 2566596862 CRC 11827;
BA_ "SPN" SG_ 2365270014 PIDCtrlFeedForwardTrq 11918;
BA_ "SPN" SG_ 2365270014 PIDCtrlNormalizedPropGain 11917;
BA_ "SigType" SG_ 2365270014 PIDCtrlNormalizedIntegralGain 1;
BA_ "SPN" SG_ 2365270014 PIDCtrlNormalizedIntegralGain 11916;
BA_ "SigType" SG_ 2365270014 PIDCtrlNormalizedDiffGain 1;
BA_ "SPN" SG_ 2365270014 PIDCtrlNormalizedDiffGain 11915;
BA_ "SPN" SG_ 2365270014 PIDCtrlApplicableMode 11914;
BA_ "SigType" SG_ 2365270014 RateLimitsReq2Counter 11;
BA_ "SPN" SG_ 2365270014 RateLimitsReq2Counter 11913;
BA_ "SigType" SG_ 2365270014 RateLimitsReq2CRC 12;
BA_ "SPN" SG_ 2365270014 RateLimitsReq2CRC 11912;
BA_ "SigType" SG_ 2566596350 HVBusLowSideResistorConnectReq 5;
BA_ "SPN" SG_ 2566596350 HVBusLowSideResistorConnectReq 11999;
BA_ "SigType" SG_ 2566596350 HVBusHiSideResistorConnectReq 5;
BA_ "SPN" SG_ 2566596350 HVBusHiSideResistorConnectReq 11998;
BA_ "SigType" SG_ 2566596350 HVBusPassiveIsolTestCmd 5;
BA_ "SPN" SG_ 2566596350 HVBusPassiveIsolTestCmd 11997;
BA_ "SigType" SG_ 2566596350 HVBusActiveIsolTestCmd 5;
BA_ "SPN" SG_ 2566596350 HVBusActiveIsolTestCmd 11996;
BA_ "SPN" SG_ 2566596094 CurMin 11978;
BA_ "SPN" SG_ 2566596094 CurMax 11977;
BA_ "SPN" SG_ 2566596094 VMin 11976;
BA_ "SPN" SG_ 2566596094 VMax 11975;
BA_ "SigType" SG_ 2566596094 Counter 11;
BA_ "SPN" SG_ 2566596094 Counter 11974;
BA_ "SigType" SG_ 2566596094 CRC 12;
BA_ "SPN" SG_ 2566596094 CRC 11973;
BA_ "SPN" SG_ 2566595838 SpdMin 11962;
BA_ "SPN" SG_ 2566595838 SpdMax 11961;
BA_ "SPN" SG_ 2566595838 TrqMin 11960;
BA_ "SPN" SG_ 2566595838 TrqMax 11959;
BA_ "SigType" SG_ 2566595838 Counter 11;
BA_ "SPN" SG_ 2566595838 Counter 11958;
BA_ "SigType" SG_ 2566595838 CRC 12;
BA_ "SPN" SG_ 2566595838 CRC 11957;
BA_ "SPN" SG_ 2566595582 DCSidePwrMin 11950;
BA_ "SPN" SG_ 2566595582 DCSidePwrMax 11949;
BA_ "SPN" SG_ 2566595582 MechPwrMin 11948;
BA_ "SPN" SG_ 2566595582 MechPwrMax 11947;
BA_ "SigType" SG_ 2566595582 Counter 11;
BA_ "SPN" SG_ 2566595582 Counter 11946;
BA_ "SigType" SG_ 2566595582 CRC 12;
BA_ "SPN" SG_ 2566595582 CRC 11945;
BA_ "SPN" SG_ 2365268734 PIDCtrlFeedForwardTrq 12036;
BA_ "SPN" SG_ 2365268734 PIDCtrlNormalizedPropGain 12035;
BA_ "SigType" SG_ 2365268734 PIDCtrlNormalizedIntegralGain 1;
BA_ "SPN" SG_ 2365268734 PIDCtrlNormalizedIntegralGain 12034;
BA_ "SigType" SG_ 2365268734 PIDCtrlNormalizedDiffGain 1;
BA_ "SPN" SG_ 2365268734 PIDCtrlNormalizedDiffGain 12033;
BA_ "SPN" SG_ 2365268734 PIDCtrlApplicableMode 12032;
BA_ "SigType" SG_ 2365268734 RateLimitsReq2Counter 11;
BA_ "SPN" SG_ 2365268734 RateLimitsReq2Counter 12031;
BA_ "SigType" SG_ 2365268734 RateLimitsReq2CRC 12;
BA_ "SPN" SG_ 2365268734 RateLimitsReq2CRC 12030;
BA_ "SigType" SG_ 2566595070 HVBusLowSideResistorConnectReq 5;
BA_ "SPN" SG_ 2566595070 HVBusLowSideResistorConnectReq 12117;
BA_ "SigType" SG_ 2566595070 HVBusHiSideResistorConnectReq 5;
BA_ "SPN" SG_ 2566595070 HVBusHiSideResistorConnectReq 12116;
BA_ "SigType" SG_ 2566595070 HVBusPassiveIsolTestCmd 5;
BA_ "SPN" SG_ 2566595070 HVBusPassiveIsolTestCmd 12115;
BA_ "SigType" SG_ 2566595070 HVBusActiveIsolTestCmd 5;
BA_ "SPN" SG_ 2566595070 HVBusActiveIsolTestCmd 12114;
BA_ "SPN" SG_ 2566594814 CurMin 12096;
BA_ "SPN" SG_ 2566594814 CurMax 12095;
BA_ "SPN" SG_ 2566594814 VMin 12094;
BA_ "SPN" SG_ 2566594814 VMax 12093;
BA_ "SigType" SG_ 2566594814 Counter 11;
BA_ "SPN" SG_ 2566594814 Counter 12092;
BA_ "SigType" SG_ 2566594814 CRC 12;
BA_ "SPN" SG_ 2566594814 CRC 12091;
BA_ "SPN" SG_ 2566594558 SpdMin 12080;
BA_ "SPN" SG_ 2566594558 SpdMax 12079;
BA_ "SPN" SG_ 2566594558 TrqMin 12078;
BA_ "SPN" SG_ 2566594558 TrqMax 12077;
BA_ "SigType" SG_ 2566594558 Counter 11;
BA_ "SPN" SG_ 2566594558 Counter 12076;
BA_ "SigType" SG_ 2566594558 CRC 12;
BA_ "SPN" SG_ 2566594558 CRC 12075;
BA_ "SPN" SG_ 2566594302 DCSidePwrMin 12068;
BA_ "SPN" SG_ 2566594302 DCSidePwrMax 12067;
BA_ "SPN" SG_ 2566594302 MechPwrMin 12066;
BA_ "SPN" SG_ 2566594302 MechPwrMax 12065;
BA_ "SigType" SG_ 2566594302 Counter 11;
BA_ "SPN" SG_ 2566594302 Counter 12064;
BA_ "SigType" SG_ 2566594302 CRC 12;
BA_ "SPN" SG_ 2566594302 CRC 12063;
BA_ "SPN" SG_ 2365267454 PIDCtrlFeedForwardTrq 12154;
BA_ "SPN" SG_ 2365267454 PIDCtrlNormalizedPropGain 12153;
BA_ "SigType" SG_ 2365267454 PIDCtrlNormalizedIntegralGain 1;
BA_ "SPN" SG_ 2365267454 PIDCtrlNormalizedIntegralGain 12152;
BA_ "SigType" SG_ 2365267454 PIDCtrlNormalizedDiffGain 1;
BA_ "SPN" SG_ 2365267454 PIDCtrlNormalizedDiffGain 12151;
BA_ "SPN" SG_ 2365267454 PIDCtrlApplicableMode 12150;
BA_ "SigType" SG_ 2365267454 RateLimitsReq2Counter 11;
BA_ "SPN" SG_ 2365267454 RateLimitsReq2Counter 12149;
BA_ "SigType" SG_ 2365267454 RateLimitsReq2CRC 12;
BA_ "SPN" SG_ 2365267454 RateLimitsReq2CRC 12148;
BA_ "SigType" SG_ 2566593790 HVBusLowSideResistorConnectReq 5;
BA_ "SPN" SG_ 2566593790 HVBusLowSideResistorConnectReq 12235;
BA_ "SigType" SG_ 2566593790 HVBusHiSideResistorConnectReq 5;
BA_ "SPN" SG_ 2566593790 HVBusHiSideResistorConnectReq 12234;
BA_ "SigType" SG_ 2566593790 HVBusPassiveIsolTestCmd 5;
BA_ "SPN" SG_ 2566593790 HVBusPassiveIsolTestCmd 12233;
BA_ "SigType" SG_ 2566593790 HVBusActiveIsolTestCmd 5;
BA_ "SPN" SG_ 2566593790 HVBusActiveIsolTestCmd 12232;
BA_ "SPN" SG_ 2566593534 CurMin 12214;
BA_ "SPN" SG_ 2566593534 CurMax 12213;
BA_ "SPN" SG_ 2566593534 VMin 12212;
BA_ "SPN" SG_ 2566593534 VMax 12211;
BA_ "SigType" SG_ 2566593534 Counter 11;
BA_ "SPN" SG_ 2566593534 Counter 12210;
BA_ "SigType" SG_ 2566593534 CRC 12;
BA_ "SPN" SG_ 2566593534 CRC 12209;
BA_ "SPN" SG_ 2566593278 SpdMin 12198;
BA_ "SPN" SG_ 2566593278 SpdMax 12197;
BA_ "SPN" SG_ 2566593278 TrqMin 12196;
BA_ "SPN" SG_ 2566593278 TrqMax 12195;
BA_ "SigType" SG_ 2566593278 Counter 11;
BA_ "SPN" SG_ 2566593278 Counter 12194;
BA_ "SigType" SG_ 2566593278 CRC 12;
BA_ "SPN" SG_ 2566593278 CRC 12193;
BA_ "SPN" SG_ 2566593022 DCSidePwrMin 12186;
BA_ "SPN" SG_ 2566593022 DCSidePwrMax 12185;
BA_ "SPN" SG_ 2566593022 MechPwrMin 12184;
BA_ "SPN" SG_ 2566593022 MechPwrMax 12183;
BA_ "SigType" SG_ 2566593022 Counter 11;
BA_ "SPN" SG_ 2566593022 Counter 12182;
BA_ "SigType" SG_ 2566593022 CRC 12;
BA_ "SPN" SG_ 2566593022 CRC 12181;
BA_ "SPN" SG_ 2365266174 PIDCtrlFeedForwardTrq 12272;
BA_ "SPN" SG_ 2365266174 PIDCtrlNormalizedPropGain 12271;
BA_ "SigType" SG_ 2365266174 PIDCtrlNormalizedIntegralGain 1;
BA_ "SPN" SG_ 2365266174 PIDCtrlNormalizedIntegralGain 12270;
BA_ "SigType" SG_ 2365266174 PIDCtrlNormalizedDiffGain 1;
BA_ "SPN" SG_ 2365266174 PIDCtrlNormalizedDiffGain 12269;
BA_ "SPN" SG_ 2365266174 PIDCtrlApplicableMode 12268;
BA_ "SigType" SG_ 2365266174 RateLimitsReq2Counter 11;
BA_ "SPN" SG_ 2365266174 RateLimitsReq2Counter 12267;
BA_ "SigType" SG_ 2365266174 RateLimitsReq2CRC 12;
BA_ "SPN" SG_ 2365266174 RateLimitsReq2CRC 12266;
BA_ "SigType" SG_ 2566592510 Bin17 1;
BA_ "SPN" SG_ 2566592510 Bin17 12337;
BA_ "SigType" SG_ 2566592510 Bin16 1;
BA_ "SPN" SG_ 2566592510 Bin16 12336;
BA_ "SigType" SG_ 2566592510 Bin15 1;
BA_ "SPN" SG_ 2566592510 Bin15 12335;
BA_ "SigType" SG_ 2566592510 Bin14 1;
BA_ "SPN" SG_ 2566592510 Bin14 12334;
BA_ "SigType" SG_ 2566592510 Bin13 1;
BA_ "SPN" SG_ 2566592510 Bin13 12333;
BA_ "SigType" SG_ 2566592510 Bin12 1;
BA_ "SPN" SG_ 2566592510 Bin12 12332;
BA_ "SigType" SG_ 2566592510 Bin11 1;
BA_ "SPN" SG_ 2566592510 Bin11 12331;
BA_ "SigType" SG_ 2566592510 Bin10 1;
BA_ "SPN" SG_ 2566592510 Bin10 12330;
BA_ "SigType" SG_ 2566592510 Bin9 1;
BA_ "SPN" SG_ 2566592510 Bin9 12329;
BA_ "SigType" SG_ 2566592510 Bin8 1;
BA_ "SPN" SG_ 2566592510 Bin8 12328;
BA_ "SigType" SG_ 2566592510 Bin7 1;
BA_ "SPN" SG_ 2566592510 Bin7 12327;
BA_ "SigType" SG_ 2566592510 Bin6 1;
BA_ "SPN" SG_ 2566592510 Bin6 12326;
BA_ "SigType" SG_ 2566592510 Bin5 1;
BA_ "SPN" SG_ 2566592510 Bin5 12325;
BA_ "SigType" SG_ 2566592510 Bin4 1;
BA_ "SPN" SG_ 2566592510 Bin4 12324;
BA_ "SigType" SG_ 2566592510 Bin3 1;
BA_ "SPN" SG_ 2566592510 Bin3 12323;
BA_ "SigType" SG_ 2566592510 Bin2 1;
BA_ "SPN" SG_ 2566592510 Bin2 12322;
BA_ "SigType" SG_ 2566592510 Bin1 1;
BA_ "SPN" SG_ 2566592510 Bin1 12321;
BA_ "SigType" SG_ 2566592254 Bin17 1;
BA_ "SPN" SG_ 2566592254 Bin17 12354;
BA_ "SigType" SG_ 2566592254 Bin16 1;
BA_ "SPN" SG_ 2566592254 Bin16 12353;
BA_ "SigType" SG_ 2566592254 Bin15 1;
BA_ "SPN" SG_ 2566592254 Bin15 12352;
BA_ "SigType" SG_ 2566592254 Bin14 1;
BA_ "SPN" SG_ 2566592254 Bin14 12351;
BA_ "SigType" SG_ 2566592254 Bin13 1;
BA_ "SPN" SG_ 2566592254 Bin13 12350;
BA_ "SigType" SG_ 2566592254 Bin12 1;
BA_ "SPN" SG_ 2566592254 Bin12 12349;
BA_ "SigType" SG_ 2566592254 Bin11 1;
BA_ "SPN" SG_ 2566592254 Bin11 12348;
BA_ "SigType" SG_ 2566592254 Bin10 1;
BA_ "SPN" SG_ 2566592254 Bin10 12347;
BA_ "SigType" SG_ 2566592254 Bin9 1;
BA_ "SPN" SG_ 2566592254 Bin9 12346;
BA_ "SigType" SG_ 2566592254 Bin8 1;
BA_ "SPN" SG_ 2566592254 Bin8 12345;
BA_ "SigType" SG_ 2566592254 Bin7 1;
BA_ "SPN" SG_ 2566592254 Bin7 12344;
BA_ "SigType" SG_ 2566592254 Bin6 1;
BA_ "SPN" SG_ 2566592254 Bin6 12343;
BA_ "SigType" SG_ 2566592254 Bin5 1;
BA_ "SPN" SG_ 2566592254 Bin5 12342;
BA_ "SigType" SG_ 2566592254 Bin4 1;
BA_ "SPN" SG_ 2566592254 Bin4 12341;
BA_ "SigType" SG_ 2566592254 Bin3 1;
BA_ "SPN" SG_ 2566592254 Bin3 12340;
BA_ "SigType" SG_ 2566592254 Bin2 1;
BA_ "SPN" SG_ 2566592254 Bin2 12339;
BA_ "SigType" SG_ 2566592254 Bin1 1;
BA_ "SPN" SG_ 2566592254 Bin1 12338;
BA_ "SigType" SG_ 2566591998 Bin17 1;
BA_ "SPN" SG_ 2566591998 Bin17 12371;
BA_ "SigType" SG_ 2566591998 Bin16 1;
BA_ "SPN" SG_ 2566591998 Bin16 12370;
BA_ "SigType" SG_ 2566591998 Bin15 1;
BA_ "SPN" SG_ 2566591998 Bin15 12369;
BA_ "SigType" SG_ 2566591998 Bin14 1;
BA_ "SPN" SG_ 2566591998 Bin14 12368;
BA_ "SigType" SG_ 2566591998 Bin13 1;
BA_ "SPN" SG_ 2566591998 Bin13 12367;
BA_ "SigType" SG_ 2566591998 Bin12 1;
BA_ "SPN" SG_ 2566591998 Bin12 12366;
BA_ "SigType" SG_ 2566591998 Bin11 1;
BA_ "SPN" SG_ 2566591998 Bin11 12365;
BA_ "SigType" SG_ 2566591998 Bin10 1;
BA_ "SPN" SG_ 2566591998 Bin10 12364;
BA_ "SigType" SG_ 2566591998 Bin9 1;
BA_ "SPN" SG_ 2566591998 Bin9 12363;
BA_ "SigType" SG_ 2566591998 Bin8 1;
BA_ "SPN" SG_ 2566591998 Bin8 12362;
BA_ "SigType" SG_ 2566591998 Bin7 1;
BA_ "SPN" SG_ 2566591998 Bin7 12361;
BA_ "SigType" SG_ 2566591998 Bin6 1;
BA_ "SPN" SG_ 2566591998 Bin6 12360;
BA_ "SigType" SG_ 2566591998 Bin5 1;
BA_ "SPN" SG_ 2566591998 Bin5 12359;
BA_ "SigType" SG_ 2566591998 Bin4 1;
BA_ "SPN" SG_ 2566591998 Bin4 12358;
BA_ "SigType" SG_ 2566591998 Bin3 1;
BA_ "SPN" SG_ 2566591998 Bin3 12357;
BA_ "SigType" SG_ 2566591998 Bin2 1;
BA_ "SPN" SG_ 2566591998 Bin2 12356;
BA_ "SigType" SG_ 2566591998 Bin1 1;
BA_ "SPN" SG_ 2566591998 Bin1 12355;
BA_ "SigType" SG_ 2566591742 Bin17 1;
BA_ "SPN" SG_ 2566591742 Bin17 12388;
BA_ "SigType" SG_ 2566591742 Bin16 1;
BA_ "SPN" SG_ 2566591742 Bin16 12387;
BA_ "SigType" SG_ 2566591742 Bin15 1;
BA_ "SPN" SG_ 2566591742 Bin15 12386;
BA_ "SigType" SG_ 2566591742 Bin14 1;
BA_ "SPN" SG_ 2566591742 Bin14 12385;
BA_ "SigType" SG_ 2566591742 Bin13 1;
BA_ "SPN" SG_ 2566591742 Bin13 12384;
BA_ "SigType" SG_ 2566591742 Bin12 1;
BA_ "SPN" SG_ 2566591742 Bin12 12383;
BA_ "SigType" SG_ 2566591742 Bin11 1;
BA_ "SPN" SG_ 2566591742 Bin11 12382;
BA_ "SigType" SG_ 2566591742 Bin10 1;
BA_ "SPN" SG_ 2566591742 Bin10 12381;
BA_ "SigType" SG_ 2566591742 Bin9 1;
BA_ "SPN" SG_ 2566591742 Bin9 12380;
BA_ "SigType" SG_ 2566591742 Bin8 1;
BA_ "SPN" SG_ 2566591742 Bin8 12379;
BA_ "SigType" SG_ 2566591742 Bin7 1;
BA_ "SPN" SG_ 2566591742 Bin7 12378;
BA_ "SigType" SG_ 2566591742 Bin6 1;
BA_ "SPN" SG_ 2566591742 Bin6 12377;
BA_ "SigType" SG_ 2566591742 Bin5 1;
BA_ "SPN" SG_ 2566591742 Bin5 12376;
BA_ "SigType" SG_ 2566591742 Bin4 1;
BA_ "SPN" SG_ 2566591742 Bin4 12375;
BA_ "SigType" SG_ 2566591742 Bin3 1;
BA_ "SPN" SG_ 2566591742 Bin3 12374;
BA_ "SigType" SG_ 2566591742 Bin2 1;
BA_ "SPN" SG_ 2566591742 Bin2 12373;
BA_ "SigType" SG_ 2566591742 Bin1 1;
BA_ "SPN" SG_ 2566591742 Bin1 12372;
BA_ "SigType" SG_ 2566591486 Bin17 1;
BA_ "SPN" SG_ 2566591486 Bin17 12405;
BA_ "SigType" SG_ 2566591486 Bin16 1;
BA_ "SPN" SG_ 2566591486 Bin16 12404;
BA_ "SigType" SG_ 2566591486 Bin15 1;
BA_ "SPN" SG_ 2566591486 Bin15 12403;
BA_ "SigType" SG_ 2566591486 Bin14 1;
BA_ "SPN" SG_ 2566591486 Bin14 12402;
BA_ "SigType" SG_ 2566591486 Bin13 1;
BA_ "SPN" SG_ 2566591486 Bin13 12401;
BA_ "SigType" SG_ 2566591486 Bin12 1;
BA_ "SPN" SG_ 2566591486 Bin12 12400;
BA_ "SigType" SG_ 2566591486 Bin11 1;
BA_ "SPN" SG_ 2566591486 Bin11 12399;
BA_ "SigType" SG_ 2566591486 Bin10 1;
BA_ "SPN" SG_ 2566591486 Bin10 12398;
BA_ "SigType" SG_ 2566591486 Bin9 1;
BA_ "SPN" SG_ 2566591486 Bin9 12397;
BA_ "SigType" SG_ 2566591486 Bin8 1;
BA_ "SPN" SG_ 2566591486 Bin8 12396;
BA_ "SigType" SG_ 2566591486 Bin7 1;
BA_ "SPN" SG_ 2566591486 Bin7 12395;
BA_ "SigType" SG_ 2566591486 Bin6 1;
BA_ "SPN" SG_ 2566591486 Bin6 12394;
BA_ "SigType" SG_ 2566591486 Bin5 1;
BA_ "SPN" SG_ 2566591486 Bin5 12393;
BA_ "SigType" SG_ 2566591486 Bin4 1;
BA_ "SPN" SG_ 2566591486 Bin4 12392;
BA_ "SigType" SG_ 2566591486 Bin3 1;
BA_ "SPN" SG_ 2566591486 Bin3 12391;
BA_ "SigType" SG_ 2566591486 Bin2 1;
BA_ "SPN" SG_ 2566591486 Bin2 12390;
BA_ "SigType" SG_ 2566591486 Bin1 1;
BA_ "SPN" SG_ 2566591486 Bin1 12389;
BA_ "SigType" SG_ 2566591230 Bin17 1;
BA_ "SPN" SG_ 2566591230 Bin17 12422;
BA_ "SigType" SG_ 2566591230 Bin16 1;
BA_ "SPN" SG_ 2566591230 Bin16 12421;
BA_ "SigType" SG_ 2566591230 Bin15 1;
BA_ "SPN" SG_ 2566591230 Bin15 12420;
BA_ "SigType" SG_ 2566591230 Bin14 1;
BA_ "SPN" SG_ 2566591230 Bin14 12419;
BA_ "SigType" SG_ 2566591230 Bin13 1;
BA_ "SPN" SG_ 2566591230 Bin13 12418;
BA_ "SigType" SG_ 2566591230 Bin12 1;
BA_ "SPN" SG_ 2566591230 Bin12 12417;
BA_ "SigType" SG_ 2566591230 Bin11 1;
BA_ "SPN" SG_ 2566591230 Bin11 12416;
BA_ "SigType" SG_ 2566591230 Bin10 1;
BA_ "SPN" SG_ 2566591230 Bin10 12415;
BA_ "SigType" SG_ 2566591230 Bin9 1;
BA_ "SPN" SG_ 2566591230 Bin9 12414;
BA_ "SigType" SG_ 2566591230 Bin8 1;
BA_ "SPN" SG_ 2566591230 Bin8 12413;
BA_ "SigType" SG_ 2566591230 Bin7 1;
BA_ "SPN" SG_ 2566591230 Bin7 12412;
BA_ "SigType" SG_ 2566591230 Bin6 1;
BA_ "SPN" SG_ 2566591230 Bin6 12411;
BA_ "SigType" SG_ 2566591230 Bin5 1;
BA_ "SPN" SG_ 2566591230 Bin5 12410;
BA_ "SigType" SG_ 2566591230 Bin4 1;
BA_ "SPN" SG_ 2566591230 Bin4 12409;
BA_ "SigType" SG_ 2566591230 Bin3 1;
BA_ "SPN" SG_ 2566591230 Bin3 12408;
BA_ "SigType" SG_ 2566591230 Bin2 1;
BA_ "SPN" SG_ 2566591230 Bin2 12407;
BA_ "SigType" SG_ 2566591230 Bin1 1;
BA_ "SPN" SG_ 2566591230 Bin1 12406;
BA_ "SigType" SG_ 2566590974 Bin17 1;
BA_ "SPN" SG_ 2566590974 Bin17 12439;
BA_ "SigType" SG_ 2566590974 Bin16 1;
BA_ "SPN" SG_ 2566590974 Bin16 12438;
BA_ "SigType" SG_ 2566590974 Bin15 1;
BA_ "SPN" SG_ 2566590974 Bin15 12437;
BA_ "SigType" SG_ 2566590974 Bin14 1;
BA_ "SPN" SG_ 2566590974 Bin14 12436;
BA_ "SigType" SG_ 2566590974 Bin13 1;
BA_ "SPN" SG_ 2566590974 Bin13 12435;
BA_ "SigType" SG_ 2566590974 Bin12 1;
BA_ "SPN" SG_ 2566590974 Bin12 12434;
BA_ "SigType" SG_ 2566590974 Bin11 1;
BA_ "SPN" SG_ 2566590974 Bin11 12433;
BA_ "SigType" SG_ 2566590974 Bin10 1;
BA_ "SPN" SG_ 2566590974 Bin10 12432;
BA_ "SigType" SG_ 2566590974 Bin9 1;
BA_ "SPN" SG_ 2566590974 Bin9 12431;
BA_ "SigType" SG_ 2566590974 Bin8 1;
BA_ "SPN" SG_ 2566590974 Bin8 12430;
BA_ "SigType" SG_ 2566590974 Bin7 1;
BA_ "SPN" SG_ 2566590974 Bin7 12429;
BA_ "SigType" SG_ 2566590974 Bin6 1;
BA_ "SPN" SG_ 2566590974 Bin6 12428;
BA_ "SigType" SG_ 2566590974 Bin5 1;
BA_ "SPN" SG_ 2566590974 Bin5 12427;
BA_ "SigType" SG_ 2566590974 Bin4 1;
BA_ "SPN" SG_ 2566590974 Bin4 12426;
BA_ "SigType" SG_ 2566590974 Bin3 1;
BA_ "SPN" SG_ 2566590974 Bin3 12425;
BA_ "SigType" SG_ 2566590974 Bin2 1;
BA_ "SPN" SG_ 2566590974 Bin2 12424;
BA_ "SigType" SG_ 2566590974 Bin1 1;
BA_ "SPN" SG_ 2566590974 Bin1 12423;
BA_ "SigType" SG_ 2566590718 Bin17 1;
BA_ "SPN" SG_ 2566590718 Bin17 12456;
BA_ "SigType" SG_ 2566590718 Bin16 1;
BA_ "SPN" SG_ 2566590718 Bin16 12455;
BA_ "SigType" SG_ 2566590718 Bin15 1;
BA_ "SPN" SG_ 2566590718 Bin15 12454;
BA_ "SigType" SG_ 2566590718 Bin14 1;
BA_ "SPN" SG_ 2566590718 Bin14 12453;
BA_ "SigType" SG_ 2566590718 Bin13 1;
BA_ "SPN" SG_ 2566590718 Bin13 12452;
BA_ "SigType" SG_ 2566590718 Bin12 1;
BA_ "SPN" SG_ 2566590718 Bin12 12451;
BA_ "SigType" SG_ 2566590718 Bin11 1;
BA_ "SPN" SG_ 2566590718 Bin11 12450;
BA_ "SigType" SG_ 2566590718 Bin10 1;
BA_ "SPN" SG_ 2566590718 Bin10 12449;
BA_ "SigType" SG_ 2566590718 Bin9 1;
BA_ "SPN" SG_ 2566590718 Bin9 12448;
BA_ "SigType" SG_ 2566590718 Bin8 1;
BA_ "SPN" SG_ 2566590718 Bin8 12447;
BA_ "SigType" SG_ 2566590718 Bin7 1;
BA_ "SPN" SG_ 2566590718 Bin7 12446;
BA_ "SigType" SG_ 2566590718 Bin6 1;
BA_ "SPN" SG_ 2566590718 Bin6 12445;
BA_ "SigType" SG_ 2566590718 Bin5 1;
BA_ "SPN" SG_ 2566590718 Bin5 12444;
BA_ "SigType" SG_ 2566590718 Bin4 1;
BA_ "SPN" SG_ 2566590718 Bin4 12443;
BA_ "SigType" SG_ 2566590718 Bin3 1;
BA_ "SPN" SG_ 2566590718 Bin3 12442;
BA_ "SigType" SG_ 2566590718 Bin2 1;
BA_ "SPN" SG_ 2566590718 Bin2 12441;
BA_ "SigType" SG_ 2566590718 Bin1 1;
BA_ "SPN" SG_ 2566590718 Bin1 12440;
BA_ "SigType" SG_ 2566590462 Bin17 1;
BA_ "SPN" SG_ 2566590462 Bin17 12473;
BA_ "SigType" SG_ 2566590462 Bin16 1;
BA_ "SPN" SG_ 2566590462 Bin16 12472;
BA_ "SigType" SG_ 2566590462 Bin15 1;
BA_ "SPN" SG_ 2566590462 Bin15 12471;
BA_ "SigType" SG_ 2566590462 Bin14 1;
BA_ "SPN" SG_ 2566590462 Bin14 12470;
BA_ "SigType" SG_ 2566590462 Bin13 1;
BA_ "SPN" SG_ 2566590462 Bin13 12469;
BA_ "SigType" SG_ 2566590462 Bin12 1;
BA_ "SPN" SG_ 2566590462 Bin12 12468;
BA_ "SigType" SG_ 2566590462 Bin11 1;
BA_ "SPN" SG_ 2566590462 Bin11 12467;
BA_ "SigType" SG_ 2566590462 Bin10 1;
BA_ "SPN" SG_ 2566590462 Bin10 12466;
BA_ "SigType" SG_ 2566590462 Bin9 1;
BA_ "SPN" SG_ 2566590462 Bin9 12465;
BA_ "SigType" SG_ 2566590462 Bin8 1;
BA_ "SPN" SG_ 2566590462 Bin8 12464;
BA_ "SigType" SG_ 2566590462 Bin7 1;
BA_ "SPN" SG_ 2566590462 Bin7 12463;
BA_ "SigType" SG_ 2566590462 Bin6 1;
BA_ "SPN" SG_ 2566590462 Bin6 12462;
BA_ "SigType" SG_ 2566590462 Bin5 1;
BA_ "SPN" SG_ 2566590462 Bin5 12461;
BA_ "SigType" SG_ 2566590462 Bin4 1;
BA_ "SPN" SG_ 2566590462 Bin4 12460;
BA_ "SigType" SG_ 2566590462 Bin3 1;
BA_ "SPN" SG_ 2566590462 Bin3 12459;
BA_ "SigType" SG_ 2566590462 Bin2 1;
BA_ "SPN" SG_ 2566590462 Bin2 12458;
BA_ "SigType" SG_ 2566590462 Bin1 1;
BA_ "SPN" SG_ 2566590462 Bin1 12457;
BA_ "SigType" SG_ 2566590206 Bin17 1;
BA_ "SPN" SG_ 2566590206 Bin17 12490;
BA_ "SigType" SG_ 2566590206 Bin16 1;
BA_ "SPN" SG_ 2566590206 Bin16 12489;
BA_ "SigType" SG_ 2566590206 Bin15 1;
BA_ "SPN" SG_ 2566590206 Bin15 12488;
BA_ "SigType" SG_ 2566590206 Bin14 1;
BA_ "SPN" SG_ 2566590206 Bin14 12487;
BA_ "SigType" SG_ 2566590206 Bin13 1;
BA_ "SPN" SG_ 2566590206 Bin13 12486;
BA_ "SigType" SG_ 2566590206 Bin12 1;
BA_ "SPN" SG_ 2566590206 Bin12 12485;
BA_ "SigType" SG_ 2566590206 Bin11 1;
BA_ "SPN" SG_ 2566590206 Bin11 12484;
BA_ "SigType" SG_ 2566590206 Bin10 1;
BA_ "SPN" SG_ 2566590206 Bin10 12483;
BA_ "SigType" SG_ 2566590206 Bin9 1;
BA_ "SPN" SG_ 2566590206 Bin9 12482;
BA_ "SigType" SG_ 2566590206 Bin8 1;
BA_ "SPN" SG_ 2566590206 Bin8 12481;
BA_ "SigType" SG_ 2566590206 Bin7 1;
BA_ "SPN" SG_ 2566590206 Bin7 12480;
BA_ "SigType" SG_ 2566590206 Bin6 1;
BA_ "SPN" SG_ 2566590206 Bin6 12479;
BA_ "SigType" SG_ 2566590206 Bin5 1;
BA_ "SPN" SG_ 2566590206 Bin5 12478;
BA_ "SigType" SG_ 2566590206 Bin4 1;
BA_ "SPN" SG_ 2566590206 Bin4 12477;
BA_ "SigType" SG_ 2566590206 Bin3 1;
BA_ "SPN" SG_ 2566590206 Bin3 12476;
BA_ "SigType" SG_ 2566590206 Bin2 1;
BA_ "SPN" SG_ 2566590206 Bin2 12475;
BA_ "SigType" SG_ 2566590206 Bin1 1;
BA_ "SPN" SG_ 2566590206 Bin1 12474;
BA_ "SigType" SG_ 2566589950 Bin17 1;
BA_ "SPN" SG_ 2566589950 Bin17 12507;
BA_ "SigType" SG_ 2566589950 Bin16 1;
BA_ "SPN" SG_ 2566589950 Bin16 12506;
BA_ "SigType" SG_ 2566589950 Bin15 1;
BA_ "SPN" SG_ 2566589950 Bin15 12505;
BA_ "SigType" SG_ 2566589950 Bin14 1;
BA_ "SPN" SG_ 2566589950 Bin14 12504;
BA_ "SigType" SG_ 2566589950 Bin13 1;
BA_ "SPN" SG_ 2566589950 Bin13 12503;
BA_ "SigType" SG_ 2566589950 Bin12 1;
BA_ "SPN" SG_ 2566589950 Bin12 12502;
BA_ "SigType" SG_ 2566589950 Bin11 1;
BA_ "SPN" SG_ 2566589950 Bin11 12501;
BA_ "SigType" SG_ 2566589950 Bin10 1;
BA_ "SPN" SG_ 2566589950 Bin10 12500;
BA_ "SigType" SG_ 2566589950 Bin9 1;
BA_ "SPN" SG_ 2566589950 Bin9 12499;
BA_ "SigType" SG_ 2566589950 Bin8 1;
BA_ "SPN" SG_ 2566589950 Bin8 12498;
BA_ "SigType" SG_ 2566589950 Bin7 1;
BA_ "SPN" SG_ 2566589950 Bin7 12497;
BA_ "SigType" SG_ 2566589950 Bin6 1;
BA_ "SPN" SG_ 2566589950 Bin6 12496;
BA_ "SigType" SG_ 2566589950 Bin5 1;
BA_ "SPN" SG_ 2566589950 Bin5 12495;
BA_ "SigType" SG_ 2566589950 Bin4 1;
BA_ "SPN" SG_ 2566589950 Bin4 12494;
BA_ "SigType" SG_ 2566589950 Bin3 1;
BA_ "SPN" SG_ 2566589950 Bin3 12493;
BA_ "SigType" SG_ 2566589950 Bin2 1;
BA_ "SPN" SG_ 2566589950 Bin2 12492;
BA_ "SigType" SG_ 2566589950 Bin1 1;
BA_ "SPN" SG_ 2566589950 Bin1 12491;
BA_ "SigType" SG_ 2566589694 Bin17 1;
BA_ "SPN" SG_ 2566589694 Bin17 12524;
BA_ "SigType" SG_ 2566589694 Bin16 1;
BA_ "SPN" SG_ 2566589694 Bin16 12523;
BA_ "SigType" SG_ 2566589694 Bin15 1;
BA_ "SPN" SG_ 2566589694 Bin15 12522;
BA_ "SigType" SG_ 2566589694 Bin14 1;
BA_ "SPN" SG_ 2566589694 Bin14 12521;
BA_ "SigType" SG_ 2566589694 Bin13 1;
BA_ "SPN" SG_ 2566589694 Bin13 12520;
BA_ "SigType" SG_ 2566589694 Bin12 1;
BA_ "SPN" SG_ 2566589694 Bin12 12519;
BA_ "SigType" SG_ 2566589694 Bin11 1;
BA_ "SPN" SG_ 2566589694 Bin11 12518;
BA_ "SigType" SG_ 2566589694 Bin10 1;
BA_ "SPN" SG_ 2566589694 Bin10 12517;
BA_ "SigType" SG_ 2566589694 Bin9 1;
BA_ "SPN" SG_ 2566589694 Bin9 12516;
BA_ "SigType" SG_ 2566589694 Bin8 1;
BA_ "SPN" SG_ 2566589694 Bin8 12515;
BA_ "SigType" SG_ 2566589694 Bin7 1;
BA_ "SPN" SG_ 2566589694 Bin7 12514;
BA_ "SigType" SG_ 2566589694 Bin6 1;
BA_ "SPN" SG_ 2566589694 Bin6 12513;
BA_ "SigType" SG_ 2566589694 Bin5 1;
BA_ "SPN" SG_ 2566589694 Bin5 12512;
BA_ "SigType" SG_ 2566589694 Bin4 1;
BA_ "SPN" SG_ 2566589694 Bin4 12511;
BA_ "SigType" SG_ 2566589694 Bin3 1;
BA_ "SPN" SG_ 2566589694 Bin3 12510;
BA_ "SigType" SG_ 2566589694 Bin2 1;
BA_ "SPN" SG_ 2566589694 Bin2 12509;
BA_ "SigType" SG_ 2566589694 Bin1 1;
BA_ "SPN" SG_ 2566589694 Bin1 12508;
BA_ "SigType" SG_ 2566589438 Bin17 1;
BA_ "SPN" SG_ 2566589438 Bin17 12541;
BA_ "SigType" SG_ 2566589438 Bin16 1;
BA_ "SPN" SG_ 2566589438 Bin16 12540;
BA_ "SigType" SG_ 2566589438 Bin15 1;
BA_ "SPN" SG_ 2566589438 Bin15 12539;
BA_ "SigType" SG_ 2566589438 Bin14 1;
BA_ "SPN" SG_ 2566589438 Bin14 12538;
BA_ "SigType" SG_ 2566589438 Bin13 1;
BA_ "SPN" SG_ 2566589438 Bin13 12537;
BA_ "SigType" SG_ 2566589438 Bin12 1;
BA_ "SPN" SG_ 2566589438 Bin12 12536;
BA_ "SigType" SG_ 2566589438 Bin11 1;
BA_ "SPN" SG_ 2566589438 Bin11 12535;
BA_ "SigType" SG_ 2566589438 Bin10 1;
BA_ "SPN" SG_ 2566589438 Bin10 12534;
BA_ "SigType" SG_ 2566589438 Bin9 1;
BA_ "SPN" SG_ 2566589438 Bin9 12533;
BA_ "SigType" SG_ 2566589438 Bin8 1;
BA_ "SPN" SG_ 2566589438 Bin8 12532;
BA_ "SigType" SG_ 2566589438 Bin7 1;
BA_ "SPN" SG_ 2566589438 Bin7 12531;
BA_ "SigType" SG_ 2566589438 Bin6 1;
BA_ "SPN" SG_ 2566589438 Bin6 12530;
BA_ "SigType" SG_ 2566589438 Bin5 1;
BA_ "SPN" SG_ 2566589438 Bin5 12529;
BA_ "SigType" SG_ 2566589438 Bin4 1;
BA_ "SPN" SG_ 2566589438 Bin4 12528;
BA_ "SigType" SG_ 2566589438 Bin3 1;
BA_ "SPN" SG_ 2566589438 Bin3 12527;
BA_ "SigType" SG_ 2566589438 Bin2 1;
BA_ "SPN" SG_ 2566589438 Bin2 12526;
BA_ "SigType" SG_ 2566589438 Bin1 1;
BA_ "SPN" SG_ 2566589438 Bin1 12525;
BA_ "SigType" SG_ 2566589182 Bin17 1;
BA_ "SPN" SG_ 2566589182 Bin17 12558;
BA_ "SigType" SG_ 2566589182 Bin16 1;
BA_ "SPN" SG_ 2566589182 Bin16 12557;
BA_ "SigType" SG_ 2566589182 Bin15 1;
BA_ "SPN" SG_ 2566589182 Bin15 12556;
BA_ "SigType" SG_ 2566589182 Bin14 1;
BA_ "SPN" SG_ 2566589182 Bin14 12555;
BA_ "SigType" SG_ 2566589182 Bin13 1;
BA_ "SPN" SG_ 2566589182 Bin13 12554;
BA_ "SigType" SG_ 2566589182 Bin12 1;
BA_ "SPN" SG_ 2566589182 Bin12 12553;
BA_ "SigType" SG_ 2566589182 Bin11 1;
BA_ "SPN" SG_ 2566589182 Bin11 12552;
BA_ "SigType" SG_ 2566589182 Bin10 1;
BA_ "SPN" SG_ 2566589182 Bin10 12551;
BA_ "SigType" SG_ 2566589182 Bin9 1;
BA_ "SPN" SG_ 2566589182 Bin9 12550;
BA_ "SigType" SG_ 2566589182 Bin8 1;
BA_ "SPN" SG_ 2566589182 Bin8 12549;
BA_ "SigType" SG_ 2566589182 Bin7 1;
BA_ "SPN" SG_ 2566589182 Bin7 12548;
BA_ "SigType" SG_ 2566589182 Bin6 1;
BA_ "SPN" SG_ 2566589182 Bin6 12547;
BA_ "SigType" SG_ 2566589182 Bin5 1;
BA_ "SPN" SG_ 2566589182 Bin5 12546;
BA_ "SigType" SG_ 2566589182 Bin4 1;
BA_ "SPN" SG_ 2566589182 Bin4 12545;
BA_ "SigType" SG_ 2566589182 Bin3 1;
BA_ "SPN" SG_ 2566589182 Bin3 12544;
BA_ "SigType" SG_ 2566589182 Bin2 1;
BA_ "SPN" SG_ 2566589182 Bin2 12543;
BA_ "SigType" SG_ 2566589182 Bin1 1;
BA_ "SPN" SG_ 2566589182 Bin1 12542;
VAL_ 2566601982 TrqLimDueToMachineCharacter_0003 3 "Not Available" 2 "Error" 1 "Torque limited for this reason" 0 "No torque limit for this reason" ;
VAL_ 2566601982 PLedDueToActiveSpdRateLmt 3 "Not Available" 2 "Error" 1 "Power limited for this reason" 0 "No power limit for this reason" ;
VAL_ 2566601982 PLedDueToActiveTrqRateLmt 3 "Not Available" 2 "Error" 1 "Power limited for this reason" 0 "No power limit for this reason" ;
VAL_ 2566601982 PLedDueToFaultCondition 3 "Not Available" 2 "Error" 1 "Power limited for this reason" 0 "No power limit for this reason" ;
VAL_ 2566601982 PLedDueToMotorTemp 3 "Not Available" 2 "Error" 1 "Power limited for this reason" 0 "No power limit for this reason" ;
VAL_ 2566601982 PLedDueToInvTemp 3 "Not Available" 2 "Error" 1 "Power limited for this reason" 0 "No power limit for this reason" ;
VAL_ 2566601982 PLedDueToSpdMin 3 "Not Available" 2 "Error" 1 "Power limited for this reason" 0 "No power limit for this reason" ;
VAL_ 2566601982 PLedDueToSpdMax 3 "Not Available" 2 "Error" 1 "Power limited for this reason" 0 "No power limit for this reason" ;
VAL_ 2566601982 PLedDueToTrqMin 3 "Not Available" 2 "Error" 1 "Power limited for this reason" 0 "No power limit for this reason" ;
VAL_ 2566601982 PLedDueToTrqMax 3 "Not Available" 2 "Error" 1 "Power limited for this reason" 0 "No power limit for this reason" ;
VAL_ 2566601982 PLedDueToDCSidePwrMin 3 "Not Available" 2 "Error" 1 "Power limited for this reason" 0 "No power limit for this reason" ;
VAL_ 2566601982 PLedDueToDCSidePwrMax 3 "Not Available" 2 "Error" 1 "Power limited for this reason" 0 "No power limit for this reason" ;
VAL_ 2566601982 PLedDueToMechPwrMin 3 "Not Available" 2 "Error" 1 "Power limited for this reason" 0 "No power limit for this reason" ;
VAL_ 2566601982 PLedDueToMechPwrMax 3 "Not Available" 2 "Error" 1 "Power limited for this reason" 0 "No power limit for this reason" ;
VAL_ 2566601982 PLedDueToDCSideVMin 3 "Not Available" 2 "Error" 1 "Power limited for this reason" 0 "No power limit for this reason" ;
VAL_ 2566601982 PLedDueToDCSideVMax 3 "Not Available" 2 "Error" 1 "Power limited for this reason" 0 "No power limit for this reason" ;
VAL_ 2566601982 PLedDueToDCSideCurMin 3 "Not Available" 2 "Error" 1 "Power limited for this reason" 0 "No power limit for this reason" ;
VAL_ 2566601982 PLedDueToDCSideCurMax 3 "Not Available" 2 "Error" 1 "Power limited for this reason" 0 "No power limit for this reason" ;
VAL_ 2566601982 PLedDueToUndefinedReason 3 "Not Available" 2 "Error" 1 "Power limited for this reason" 0 "No power limit for this reason" ;
VAL_ 2566601726 HVBusPassiveIsolTestStatus 15 "Not available" 14 "Error" 13 "Reserved" 12 "Reserved" 11 "Reserved" 10 "Reserved" 9 "Reserved" 8 "Reserved" 7 "Reserved" 6 "Passive Isolation Test Inhibited" 5 "Test complete,  isolation fault" 4 "Test complete,  isolation marginal" 3 "Test complete,  isolation acceptable" 2 "Test in process" 1 "Test requested but not yet in process" 0 "No test requested / No test in process" ;
VAL_ 2566601726 HVBusActiveIsolTestStatus 15 "Not available" 14 "Error" 13 "Reserved" 12 "Reserved" 11 "Reserved" 10 "Reserved" 9 "Reserved" 8 "Reserved" 7 "Reserved" 6 "Active Isolation Test Inhibited" 5 "Test complete,  isolation fault" 4 "Test complete,  isolation marginal" 3 "Test complete,  isolation acceptable" 2 "Test in process" 1 "Test requested but not yet in process" 0 "No test requested / No test in process" ;
VAL_ 2566600190 TrqLimDueToMachineCharacter_0004 3 "Not Available" 2 "Error" 1 "Torque limited for this reason" 0 "No torque limit for this reason" ;
VAL_ 2566600190 PLedDueToActiveSpdRateLmt 3 "Not Available" 2 "Error" 1 "Power limited for this reason" 0 "No power limit for this reason" ;
VAL_ 2566600190 PLedDueToActiveTrqRateLmt 3 "Not Available" 2 "Error" 1 "Power limited for this reason" 0 "No power limit for this reason" ;
VAL_ 2566600190 PLedDueToFaultCondition 3 "Not Available" 2 "Error" 1 "Power limited for this reason" 0 "No power limit for this reason" ;
VAL_ 2566600190 PLedDueToMotorTemp 3 "Not Available" 2 "Error" 1 "Power limited for this reason" 0 "No power limit for this reason" ;
VAL_ 2566600190 PLedDueToInvTemp 3 "Not Available" 2 "Error" 1 "Power limited for this reason" 0 "No power limit for this reason" ;
VAL_ 2566600190 PLedDueToSpdMin 3 "Not Available" 2 "Error" 1 "Power limited for this reason" 0 "No power limit for this reason" ;
VAL_ 2566600190 PLedDueToSpdMax 3 "Not Available" 2 "Error" 1 "Power limited for this reason" 0 "No power limit for this reason" ;
VAL_ 2566600190 PLedDueToTrqMin 3 "Not Available" 2 "Error" 1 "Power limited for this reason" 0 "No power limit for this reason" ;
VAL_ 2566600190 PLedDueToTrqMax 3 "Not Available" 2 "Error" 1 "Power limited for this reason" 0 "No power limit for this reason" ;
VAL_ 2566600190 PLedDueToDCSidePwrMin 3 "Not Available" 2 "Error" 1 "Power limited for this reason" 0 "No power limit for this reason" ;
VAL_ 2566600190 PLedDueToDCSidePwrMax 3 "Not Available" 2 "Error" 1 "Power limited for this reason" 0 "No power limit for this reason" ;
VAL_ 2566600190 PLedDueToMechPwrMin 3 "Not Available" 2 "Error" 1 "Power limited for this reason" 0 "No power limit for this reason" ;
VAL_ 2566600190 PLedDueToMechPwrMax 3 "Not Available" 2 "Error" 1 "Power limited for this reason" 0 "No power limit for this reason" ;
VAL_ 2566600190 PLedDueToDCSideVMin 3 "Not Available" 2 "Error" 1 "Power limited for this reason" 0 "No power limit for this reason" ;
VAL_ 2566600190 PLedDueToDCSideVMax 3 "Not Available" 2 "Error" 1 "Power limited for this reason" 0 "No power limit for this reason" ;
VAL_ 2566600190 PLedDueToDCSideCurMin 3 "Not Available" 2 "Error" 1 "Power limited for this reason" 0 "No power limit for this reason" ;
VAL_ 2566600190 PLedDueToDCSideCurMax 3 "Not Available" 2 "Error" 1 "Power limited for this reason" 0 "No power limit for this reason" ;
VAL_ 2566600190 PLedDueToUndefinedReason 3 "Not Available" 2 "Error" 1 "Power limited for this reason" 0 "No power limit for this reason" ;
VAL_ 2566599934 HVBusPassiveIsolTestStatus 15 "Not available" 14 "Error" 13 "Reserved" 12 "Reserved" 11 "Reserved" 10 "Reserved" 9 "Reserved" 8 "Reserved" 7 "Reserved" 6 "Passive Isolation Test Inhibited" 5 "Test complete,  isolation fault" 4 "Test complete,  isolation marginal" 3 "Test complete,  isolation acceptable" 2 "Test in process" 1 "Test requested but not yet in process" 0 "No test requested / No test in process" ;
VAL_ 2566599934 HVBusActiveIsolTestStatus 15 "Not available" 14 "Error" 13 "Reserved" 12 "Reserved" 11 "Reserved" 10 "Reserved" 9 "Reserved" 8 "Reserved" 7 "Reserved" 6 "Active Isolation Test Inhibited" 5 "Test complete,  isolation fault" 4 "Test complete,  isolation marginal" 3 "Test complete,  isolation acceptable" 2 "Test in process" 1 "Test requested but not yet in process" 0 "No test requested / No test in process" ;
VAL_ 2566597630 HVBusLowSideResistorConnectReq 3 "Don't care/take no action" 2 "Reserved" 1 "Connection Requested" 0 "Connection not Requested" ;
VAL_ 2566597630 HVBusHiSideResistorConnectReq 3 "Don't care/take no action" 2 "Reserved" 1 "Connection Requested" 0 "Connection not Requested" ;
VAL_ 2566597630 HVBusPassiveIsolTestCmd 3 "Don't care/Take no action" 2 "Inhibit Passive Isolation Test" 1 "Passive Isolation Test request" 0 "Passive Isolation Test not requested" ;
VAL_ 2566597630 HVBusActiveIsolTestCmd 3 "Don't care/Take no action" 2 "Inhibit Active Isolation Test" 1 "Active Isolation Test request" 0 "Active Isolation Test not requested" ;
VAL_ 2365270014 PIDCtrlApplicableMode 15 "Don't Care/Take No Action" 14 "SAE Reserved" 13 "SAE Reserved" 12 "SAE Reserved" 11 "SAE Reserved" 10 "SAE Reserved" 9 "SAE Reserved" 8 "SAE Reserved" 7 "SAE Reserved" 6 "SAE Reserved" 5 "SAE Reserved" 4 "Mechanical Power Control Mode" 3 "DC Power Control Mode" 2 "DC Side Current Mode" 1 "DC Side Voltage Mode" 0 "Speed Control Mode" ;
VAL_ 2566596350 HVBusLowSideResistorConnectReq 3 "Don't care/take no action" 2 "Reserved" 1 "Connection Requested" 0 "Connection not Requested" ;
VAL_ 2566596350 HVBusHiSideResistorConnectReq 3 "Don't care/take no action" 2 "Reserved" 1 "Connection Requested" 0 "Connection not Requested" ;
VAL_ 2566596350 HVBusPassiveIsolTestCmd 3 "Don't care/Take no action" 2 "Inhibit Passive Isolation Test" 1 "Passive Isolation Test request" 0 "Passive Isolation Test not requested" ;
VAL_ 2566596350 HVBusActiveIsolTestCmd 3 "Don't care/Take no action" 2 "Inhibit Active Isolation Test" 1 "Active Isolation Test request" 0 "Active Isolation Test not requested" ;
VAL_ 2365268734 PIDCtrlApplicableMode 15 "Don't Care/Take No Action" 14 "SAE Reserved" 13 "SAE Reserved" 12 "SAE Reserved" 11 "SAE Reserved" 10 "SAE Reserved" 9 "SAE Reserved" 8 "SAE Reserved" 7 "SAE Reserved" 6 "SAE Reserved" 5 "SAE Reserved" 4 "Mechanical Power Control Mode" 3 "DC Power Control Mode" 2 "DC Side Current Mode" 1 "DC Side Voltage Mode" 0 "Speed Control Mode" ;
VAL_ 2566595070 HVBusLowSideResistorConnectReq 3 "Don't care/take no action" 2 "Reserved" 1 "Connection Requested" 0 "Connection not Requested" ;
VAL_ 2566595070 HVBusHiSideResistorConnectReq 3 "Don't care/take no action" 2 "Reserved" 1 "Connection Requested" 0 "Connection not Requested" ;
VAL_ 2566595070 HVBusPassiveIsolTestCmd 3 "Don't care/Take no action" 2 "Inhibit Passive Isolation Test" 1 "Passive Isolation Test request" 0 "Passive Isolation Test not requested" ;
VAL_ 2566595070 HVBusActiveIsolTestCmd 3 "Don't care/Take no action" 2 "Inhibit Active Isolation Test" 1 "Active Isolation Test request" 0 "Active Isolation Test not requested" ;
VAL_ 2365267454 PIDCtrlApplicableMode 15 "Don't Care/Take No Action" 14 "SAE Reserved" 13 "SAE Reserved" 12 "SAE Reserved" 11 "SAE Reserved" 10 "SAE Reserved" 9 "SAE Reserved" 8 "SAE Reserved" 7 "SAE Reserved" 6 "SAE Reserved" 5 "SAE Reserved" 4 "Mechanical Power Control Mode" 3 "DC Power Control Mode" 2 "DC Side Current Mode" 1 "DC Side Voltage Mode" 0 "Speed Control Mode" ;
VAL_ 2566593790 HVBusLowSideResistorConnectReq 3 "Don't care/take no action" 2 "Reserved" 1 "Connection Requested" 0 "Connection not Requested" ;
VAL_ 2566593790 HVBusHiSideResistorConnectReq 3 "Don't care/take no action" 2 "Reserved" 1 "Connection Requested" 0 "Connection not Requested" ;
VAL_ 2566593790 HVBusPassiveIsolTestCmd 3 "Don't care/Take no action" 2 "Inhibit Passive Isolation Test" 1 "Passive Isolation Test request" 0 "Passive Isolation Test not requested" ;
VAL_ 2566593790 HVBusActiveIsolTestCmd 3 "Don't care/Take no action" 2 "Inhibit Active Isolation Test" 1 "Active Isolation Test request" 0 "Active Isolation Test not requested" ;
VAL_ 2365266174 PIDCtrlApplicableMode 15 "Don't Care/Take No Action" 14 "SAE Reserved" 13 "SAE Reserved" 12 "SAE Reserved" 11 "SAE Reserved" 10 "SAE Reserved" 9 "SAE Reserved" 8 "SAE Reserved" 7 "SAE Reserved" 6 "SAE Reserved" 5 "SAE Reserved" 4 "Mechanical Power Control Mode" 3 "DC Power Control Mode" 2 "DC Side Current Mode" 1 "DC Side Voltage Mode" 0 "Speed Control Mode" ;
